VERSION ""

NS_ :

BS_:

BU_: FSClient FSBrowser FileServer
VAL_TABLE_ TIM_AuthErrorCode 39 "LwAPossibleBitMismatch" 38 "AuthenticationAbortedDueToGeneralPeerError" 37 "AuthenticationAbortedByPeerDueToError" 36 "ChallengeDataCorrupt" 35 "InvalidChallengeLength" 34 "FunctionFacilityNotCertified" 33 "RequestNotAllowed" 32 "Reserved_0x20" 31 "AuthenticationTimeout" 30 "CertificateTypeInvalid" 29 "DeviceCertificateRevoked" 28 "ManufacturerSeriesCertificateRevoked" 27 "ManufacturerCertificateRevoked" 26 "LabCertificateRevoked" 25 "RootCertificateRevoked" 24 "CertificateTypeMismatch" 23 "CertificateChainInvalid" 22 "ECU_CCID_Mismatch" 21 "NAME_Mismatch" 20 "ECC_PublicKeyValidationFailed" 19 "UnexpectedRestartAuthenticationBitSet" 18 "AuthenticationStatusInvalid" 17 "AuthenticationTypeNotSupported" 16 "AuthenticationStatusLost" 15 "DeviceCertificateDataCorrupt" 14 "ManufacturerSeriesCertificateDataCorrupt" 13 "ManufacturerCertificateDataCorrupt" 12 "TestLabCertificateDataCorrupt" 11 "RootCertificateDataCorrupt" 10 "InternalError" 9 "ChallengesDontMatch" 8 "DeviceCertificateSignatureInvalid" 7 "ManufacturerSeriesCertificateSignatureInvalid" 6 "ManufacturerCertificateSignatureInvalid" 5 "LabCertificateSignatureInvalid" 4 "RootCertificateSignatureInvalid" 3 "NotAuthenticationServerOrClient" 2 "CertificateFormatNotSupported" 1 "ParticipantBusy" 0 "NoError" ;
VAL_TABLE_ TIM_CertificateType 255 "NotAvailable" 6 "CRLCertificate" 5 "CRLSigningCertificate" 4 "DeviceCertificate" 3 "ManufacturereSeriesCertificate" 2 "ManufacturerCertificate" 1 "TestlabCertificate" 0 "AEFRootCertificate" ;
VAL_TABLE_ NetworkInterconnUnitParametrics 16 "NetworkInterconnectionUnitType" 15 "NumberOfPorts" 14 "UptimeSinceLastPowerOnReset " 13 "AverageNumOfMsgsFilteredPerSec" 12 "AverageNumOfMsgsForwardedPerSec" 11 "AverageNumOfMsgsReceivedPerSec" 10 "NumOfMsgsWithExcessTransitDelayTime " 9 "NumOfMsgsLostDueToBufferOverflow " 8 "AverageTransitDelayTime" 7 "MaxTransitDelayTime" 6 "MaxNumOfMsgsFilteredPerSec" 5 "MaxNumOfMsgsForwardedPerSec" 4 "MaxNumOfMsgsReceivedPerSec" 3 "NumberOfFilterDatabaseEntries" 2 "MaxFilterDatabaseSize" 1 "BufferSize" 0 "RequestAllParameters" ;
VAL_TABLE_ FMI 0 "Above normal (most severe)" 1 "Below normal (most severe)" 2 "Data erratic" 3 "Voltage above normal" 4 "Voltage below normal" 5 "Current below normal" 6 "Current above normal" 7 "Mechanical system not responding" 8 "Abnormal frequency" 9 "Abnormal update rate" 10 "Abnormal rate of change" 11 "Root cause not known" 12 "Bad intelligent device" 13 "Out of calibration" 14 "Special intstructions" 15 "Above normal (least severe)" 16 "Above normal (moderately severe)" 17 "Below normal (least severe)" 18 "Below normal (moderately severe)" 19 "Received network data in error" 31 "Not available" 20 "Data Drifted High" 21 "Data Drifted Low" ;

BO_ 2628517377 FSC_FileServer: 35 FileServer
 SG_ OF_ATTR_VolumeSupportsHidden m32 : 34|1@1+ (1,0) [0|1] "" Vector__XXX
 SG_ GCD_PathName m16 : 88|16@1+ (1,0) [0|65535] "" Vector__XXX
 SG_ GCD_FreeSpace m16 : 56|32@1+ (512,0) [0|4294966744] "Bytes" Vector__XXX
 SG_ FDT_TimeHour m52 : 51|5@1+ (1,0) [0|23] "Hour" Vector__XXX
 SG_ FDT_TimeMinutes m52 : 45|6@1+ (1,0) [0|59] "Minutes" Vector__XXX
 SG_ FDT_TimeSeconds m52 : 40|5@1+ (2,0) [0|58] "Seconds" Vector__XXX
 SG_ OF_ATTR_VolumeIsCaseSensitive m32 : 39|1@1+ (1,0) [0|1] "" Vector__XXX
 SG_ OF_ATTR_VolumeIsRemovable m32 : 38|1@1+ (1,0) [0|1] "" Vector__XXX
 SG_ OF_ATTR_SupportsLongFilenames m32 : 37|1@1+ (1,0) [0|1] "" Vector__XXX
 SG_ OF_ATTR_IsDirectory m32 : 36|1@1+ (1,0) [0|1] "" Vector__XXX
 SG_ OF_ATTR_IsVolume m32 : 35|1@1+ (1,0) [0|1] "" Vector__XXX
 SG_ FDT_DateYear m52 : 33|7@1+ (1,1980) [1980|2107] "Year" Vector__XXX
 SG_ OF_ATTR_Hidden m32 : 33|1@1+ (1,0) [0|1] "" Vector__XXX
 SG_ SF_Position m33 : 32|32@1+ (1,0) [0|4294967295] "" Vector__XXX
 SG_ OF_ATTR_ReadOnly m32 : 32|1@1+ (1,0) [0|1] "" Vector__XXX
 SG_ GA_Size m50 : 32|32@1+ (1,0) [0|4294967295] "" Vector__XXX
 SG_ VS_VolumeName m2 : 32|16@1+ (1,0) [0|65535] "" Vector__XXX
 SG_ VI_VolumeIsCaseSensitive m64 : 31|1@1+ (1,0) [0|1] "" Vector__XXX
 SG_ GA_ATTR_VolumeIsCaseSensitive m50 : 31|1@1+ (1,0) [0|1] "" Vector__XXX
 SG_ VI_ATTR_VolumeRemovable m64 : 30|1@1+ (1,0) [0|1] "" Vector__XXX
 SG_ GA_ATTR_VolumeIsRemovable m50 : 30|1@1+ (1,0) [0|1] "" Vector__XXX
 SG_ VI_ATTR_SupportsLongFilenames m64 : 29|1@1+ (1,0) [0|1] "" Vector__XXX
 SG_ FDT_DateMonth m52 : 29|4@1+ (1,0) [0|12] "Month" Vector__XXX
 SG_ GA_ATTR_SupportsLongFilenames m50 : 29|1@1+ (1,0) [0|1] "" Vector__XXX
 SG_ GA_ATTR_IsDirectory m50 : 28|1@1+ (1,0) [0|1] "" Vector__XXX
 SG_ VI_ATTR_IsDirectory m64 : 28|1@1+ (1,0) [0|1] "" Vector__XXX
 SG_ VI_ATTR_IsVolume m64 : 27|1@1+ (1,0) [0|1] "" Vector__XXX
 SG_ GA_ATTR_IsVolume m50 : 27|1@1+ (1,0) [0|1] "" Vector__XXX
 SG_ VI_ATTR_VolumeSupportsHidden m64 : 26|1@1+ (1,0) [0|1] "" Vector__XXX
 SG_ GA_ATTR_VolumeSupportsHidden m50 : 26|1@1+ (1,0) [0|1] "" Vector__XXX
 SG_ VI_ATTR_Hidden m64 : 25|1@1+ (1,0) [0|1] "" Vector__XXX
 SG_ GA_ATTR_Hidden m50 : 25|1@1+ (1,0) [0|1] "" Vector__XXX
 SG_ VI_ATTR_ReadOnly m64 : 24|1@1+ (1,0) [0|1] "" Vector__XXX
 SG_ FDT_DateDay m52 : 24|5@1+ (1,0) [0|31] "Day" Vector__XXX
 SG_ GA_ATTR_ReadOnly m50 : 24|1@1+ (1,0) [0|1] "" Vector__XXX
 SG_ OF_Handle m32 : 24|8@1+ (1,0) [0|255] "" Vector__XXX
 SG_ GCD_TotalSpace m16 : 24|32@1+ (512,0) [0|4294966744] "Bytes" Vector__XXX
 SG_ RF_Count m34 : 24|16@1+ (1,0) [0|65535] "Bytes" Vector__XXX
 SG_ GSP_SupportMultipleVolumes m1 : 24|1@1+ (1,0) [0|255] "" Vector__XXX
 SG_ WF_Count m35 : 24|16@1+ (1,0) [0|65535] "" Vector__XXX
 SG_ VS_ErrorCode m2 : 24|8@1+ (1,0) [0|255] "" Vector__XXX
 SG_ FDT_ErrorCode m52 : 16|8@1+ (1,0) [0|255] "" Vector__XXX
 SG_ RF_ErrorCode m34 : 16|8@1+ (1,0) [0|255] "" Vector__XXX
 SG_ SF_ErrorCode m33 : 16|8@1+ (1,0) [0|255] "" Vector__XXX
 SG_ FSNumberOfOpenFiles m0 : 16|8@1- (1,0) [0|255] "" Vector__XXX
 SG_ OF_ErrorCode m32 : 16|8@1+ (1,0) [0|255] "" Vector__XXX
 SG_ WF_ErrorCode m35 : 16|8@1+ (1,0) [0|255] "" Vector__XXX
 SG_ CF_ErrorCode m36 : 16|8@1+ (1,0) [0|255] "" Vector__XXX
 SG_ MF_ErrorCode m48 : 16|8@1+ (1,0) [0|255] "" Vector__XXX
 SG_ GA_ErrorCode m50 : 16|8@1+ (1,0) [0|255] "" Vector__XXX
 SG_ SA_ErrorCode m51 : 16|8@1+ (1,0) [0|255] "" Vector__XXX
 SG_ GCD_ErrorCode m16 : 16|8@1+ (1,0) [0|255] "" Vector__XXX
 SG_ CCD_ErrorCode m17 : 16|8@1+ (1,0) [0|255] "" Vector__XXX
 SG_ GSP_MaxNrSimultaneousFilesOpen m1 : 16|8@1+ (1,0) [0|255] "" Vector__XXX
 SG_ DF_ErrorCode m49 : 16|8@1+ (1,0) [0|255] "" Vector__XXX
 SG_ VI_ErrorCode m64 : 16|8@1+ (1,0) [0|255] "" Vector__XXX
 SG_ VS_MaxTimeBeforeVolRemoval m2 : 16|8@1+ (1,0) [0|250] "min/bit" Vector__XXX
 SG_ FSBusyWriting m0 : 9|1@1+ (1,0) [0|1] "" Vector__XXX
 SG_ FSBusyReading m0 : 8|1@1+ (1,0) [0|1] "" Vector__XXX
 SG_ OF_TAN m32 : 8|8@1+ (1,0) [0|255] "" Vector__XXX
 SG_ SF_TAN m33 : 8|8@1+ (1,0) [0|255] "" Vector__XXX
 SG_ RF_TAN m34 : 8|8@1+ (1,0) [0|255] "" Vector__XXX
 SG_ WF_TAN m35 : 8|8@1+ (1,0) [0|255] "" Vector__XXX
 SG_ CF_TAN m36 : 8|8@1+ (1,0) [0|255] "" Vector__XXX
 SG_ MF_TAN m48 : 8|8@1+ (1,0) [0|255] "" Vector__XXX
 SG_ GA_TAN m50 : 8|8@1+ (1,0) [0|255] "" Vector__XXX
 SG_ SA_TAN m51 : 8|8@1+ (1,0) [0|255] "" Vector__XXX
 SG_ FDT_TAN m52 : 8|8@1+ (1,0) [0|255] "" Vector__XXX
 SG_ GCD_TAN m16 : 8|8@1+ (1,0) [0|255] "" Vector__XXX
 SG_ CCD_TAN m17 : 8|8@1+ (1,0) [0|255] "" Vector__XXX
 SG_ GSP_VersionNumber m1 : 8|8@1+ (1,0) [0|255] "" Vector__XXX
 SG_ DF_TAN m49 : 8|8@1+ (1,0) [0|255] "" Vector__XXX
 SG_ VI_TAN m64 : 8|8@1+ (1,0) [0|255] "" Vector__XXX
 SG_ VS_VolumeStatus m2 : 8|8@1+ (1,0) [0|3] "" Vector__XXX
 SG_ FSServerCommand M : 0|8@1+ (1,0) [0|255] "" Vector__XXX

BO_ 2628451851 CFS_FSBrowser: 9 FSBrowser
 SG_ SA_ATTR_SupportsLongFilenames m51 : 21|1@1+ (1,0) [0|1] "" Vector__XXX
 SG_ SA_ATTR_VolumeSupportsHidden m51 : 18|1@1+ (1,0) [0|1] "" Vector__XXX
 SG_ SA_ATTR_VolumeIsRemovable m51 : 22|1@1+ (1,0) [0|1] "" Vector__XXX
 SG_ SA_ATTR_VolumeIsCaseSensitive m51 : 23|1@1+ (1,0) [0|1] "" Vector__XXX
 SG_ SA_ATTR_IsVolume m51 : 19|1@1+ (1,0) [0|1] "" Vector__XXX
 SG_ SA_ATTR_IsDirectory m51 : 20|1@1+ (1,0) [0|1] "" Vector__XXX
 SG_ VI_VolumeName m64 : 56|16@1+ (1,0) [0|65535] "" Vector__XXX
 SG_ VI_Flag_OverwriteExisting m64 : 48|1@1+ (1,0) [0|1] "" Vector__XXX
 SG_ MF_DestinationPathNameLength m48 : 40|16@1+ (1,0) [0|65535] "" Vector__XXX
 SG_ RF_ReportHiddenFiles m34 : 40|8@1+ (1,0) [0|255] "" Vector__XXX
 SG_ SF_Offset m33 : 32|32@1- (1,0) [-2147483648|2147483647] "" Vector__XXX
 SG_ RF_Count m34 : 24|16@1+ (1,0) [0|65535] "" Vector__XXX
 SG_ SF_PositionMode m33 : 24|8@1+ (1,0) [0|255] "" Vector__XXX
 SG_ OF_PathName m32 : 24|16@1+ (1,0) [0|65535] "" Vector__XXX
 SG_ MF_SourcePathNameLength m48 : 24|16@1+ (1,0) [0|65535] "" Vector__XXX
 SG_ WF_Count m35 : 24|16@1+ (1,0) [0|65535] "" Vector__XXX
 SG_ DF_PathName m49 : 24|16@1+ (1,0) [0|65535] "" Vector__XXX
 SG_ SA_PathName m51 : 24|16@1+ (1,0) [0|65535] "" Vector__XXX
 SG_ VI_Space m64 : 16|32@1+ (1,0) [0|4294967295] "" Vector__XXX
 SG_ OF_FlagExclusiveAccess m32 : 20|1@1+ (1,0) [0|1] "" Vector__XXX
 SG_ OF_FlagAppend m32 : 19|1@1+ (1,0) [0|1] "" Vector__XXX
 SG_ SA_ATTR_Hidden m51 : 17|1@1+ (1,0) [0|1] "" Vector__XXX
 SG_ OF_FlagCreateNew m32 : 18|1@1+ (1,0) [0|1] "" Vector__XXX
 SG_ MF_MoveModeRecursive m48 : 18|1@1+ (1,0) [0|1] "" Vector__XXX
 SG_ DF_DeleteModeRecursive m49 : 18|1@1+ (1,0) [0|1] "" Vector__XXX
 SG_ MF_MoveModeForce m48 : 17|1@1+ (1,0) [0|1] "" Vector__XXX
 SG_ DF_DeleteModeForce m49 : 17|1@1+ (1,0) [0|1] "" Vector__XXX
 SG_ VI_Flag_UsingSpaceSpecified m64 : 49|1@1+ (1,0) [0|1] "" Vector__XXX
 SG_ SA_ATTR_ReadOnly m51 : 16|1@1+ (1,0) [0|1] "" Vector__XXX
 SG_ CF_Handle m36 : 16|8@1+ (1,0) [0|255] "" Vector__XXX
 SG_ WF_Handle m35 : 16|8@1+ (1,0) [0|255] "" Vector__XXX
 SG_ RF_Handle m34 : 16|8@1+ (1,0) [0|255] "" Vector__XXX
 SG_ SF_Handle m33 : 16|8@1+ (1,0) [0|255] "" Vector__XXX
 SG_ OF_FlagReadWrite m32 : 16|2@1+ (1,0) [0|3] "" Vector__XXX
 SG_ CCD_PathName m17 : 16|16@1+ (1,0) [0|65535] "" Vector__XXX
 SG_ MF_MoveModeCopy m48 : 16|1@1+ (1,0) [0|1] "" Vector__XXX
 SG_ DF_DeleteMode m49 : 16|1@1+ (1,0) [0|1] "" Vector__XXX
 SG_ GA_PathName m50 : 16|16@1+ (1,0) [0|65535] "" Vector__XXX
 SG_ FDT_PathName m52 : 16|16@1+ (1,0) [0|65535] "" Vector__XXX
 SG_ VS_VolumeName m2 : 16|16@1+ (1,0) [0|0] "" Vector__XXX
 SG_ VS_RequestVolumeToPrepareForRemo m2 : 9|1@1- (1,0) [0|1] "" Vector__XXX
 SG_ CCD_TAN m17 : 8|8@1+ (1,0) [0|255] "" Vector__XXX
 SG_ GCD_TAN m16 : 8|8@1+ (1,0) [0|255] "" Vector__XXX
 SG_ FDT_TAN m52 : 8|8@1+ (1,0) [0|255] "" Vector__XXX
 SG_ SA_TAN m51 : 8|8@1+ (1,0) [0|255] "" Vector__XXX
 SG_ GA_TAN m50 : 8|8@1+ (1,0) [0|255] "" Vector__XXX
 SG_ RF_TAN m34 : 8|8@1+ (1,0) [0|255] "" Vector__XXX
 SG_ CF_TAN m36 : 8|8@1+ (1,0) [0|255] "" Vector__XXX
 SG_ WF_TAN m35 : 8|8@1+ (1,0) [0|255] "" Vector__XXX
 SG_ SF_TAN m33 : 8|8@1+ (1,0) [0|255] "" Vector__XXX
 SG_ OF_TAN m32 : 8|8@1+ (1,0) [0|255] "" Vector__XXX
 SG_ MF_TAN m48 : 8|8@1+ (1,0) [0|255] "" Vector__XXX
 SG_ DF_TAN m49 : 8|8@1+ (1,0) [0|255] "" Vector__XXX
 SG_ VI_TAN m64 : 8|8@1+ (1,0) [0|255] "" Vector__XXX
 SG_ VS_ReportVolumeUsedByClient m2 : 8|1@1+ (1,0) [0|1] "" Vector__XXX
 SG_ CM_VersionNumber m0 : 8|8@1+ (1,0) [0|255] "" Vector__XXX
 SG_ FSClientCommand M : 0|8@1+ (1,0) [0|255] "" Vector__XXX

BO_ 2628451850 CFS_FSClient: 9 FSClient
 SG_ SA_ATTR_SupportsLongFilenames m51 : 21|1@1+ (1,0) [0|1] "" Vector__XXX
 SG_ SA_ATTR_VolumeSupportsHidden m51 : 18|1@1+ (1,0) [0|1] "" Vector__XXX
 SG_ SA_ATTR_VolumeIsRemovable m51 : 22|1@1+ (1,0) [0|1] "" Vector__XXX
 SG_ SA_ATTR_VolumeIsCaseSensitive m51 : 23|1@1+ (1,0) [0|1] "" Vector__XXX
 SG_ SA_ATTR_IsVolume m51 : 19|1@1+ (1,0) [0|1] "" Vector__XXX
 SG_ SA_ATTR_IsDirectory m51 : 20|1@1+ (1,0) [0|1] "" Vector__XXX
 SG_ VI_VolumeName m64 : 56|16@1+ (1,0) [0|65535] "" Vector__XXX
 SG_ VI_Flag_OverwriteExisting m64 : 48|1@1+ (1,0) [0|1] "" Vector__XXX
 SG_ MF_DestinationPathNameLength m48 : 40|16@1+ (1,0) [0|65535] "" Vector__XXX
 SG_ RF_ReportHiddenFiles m34 : 40|8@1+ (1,0) [0|255] "" Vector__XXX
 SG_ SF_Offset m33 : 32|32@1- (1,0) [-2147483648|2147483647] "" Vector__XXX
 SG_ RF_Count m34 : 24|16@1+ (1,0) [0|65535] "" Vector__XXX
 SG_ SF_PositionMode m33 : 24|8@1+ (1,0) [0|255] "" Vector__XXX
 SG_ OF_PathName m32 : 24|16@1+ (1,0) [0|65535] "" Vector__XXX
 SG_ MF_SourcePathNameLength m48 : 24|16@1+ (1,0) [0|65535] "" Vector__XXX
 SG_ WF_Count m35 : 24|16@1+ (1,0) [0|65535] "" Vector__XXX
 SG_ DF_PathName m49 : 24|16@1+ (1,0) [0|65535] "" Vector__XXX
 SG_ SA_PathName m51 : 24|16@1+ (1,0) [0|65535] "" Vector__XXX
 SG_ VI_Space m64 : 16|32@1+ (1,0) [0|4294967295] "" Vector__XXX
 SG_ OF_FlagExclusiveAccess m32 : 20|1@1+ (1,0) [0|1] "" Vector__XXX
 SG_ OF_FlagAppend m32 : 19|1@1+ (1,0) [0|1] "" Vector__XXX
 SG_ SA_ATTR_Hidden m51 : 17|1@1+ (1,0) [0|1] "" Vector__XXX
 SG_ OF_FlagCreateNew m32 : 18|1@1+ (1,0) [0|1] "" Vector__XXX
 SG_ MF_MoveModeRecursive m48 : 18|1@1+ (1,0) [0|1] "" Vector__XXX
 SG_ DF_DeleteModeRecursive m49 : 18|1@1+ (1,0) [0|1] "" Vector__XXX
 SG_ MF_MoveModeForce m48 : 17|1@1+ (1,0) [0|1] "" Vector__XXX
 SG_ DF_DeleteModeForce m49 : 17|1@1+ (1,0) [0|1] "" Vector__XXX
 SG_ VI_Flag_UsingSpaceSpecified m64 : 49|1@1+ (1,0) [0|1] "" Vector__XXX
 SG_ SA_ATTR_ReadOnly m51 : 16|1@1+ (1,0) [0|1] "" Vector__XXX
 SG_ CF_Handle m36 : 16|8@1+ (1,0) [0|255] "" Vector__XXX
 SG_ WF_Handle m35 : 16|8@1+ (1,0) [0|255] "" Vector__XXX
 SG_ RF_Handle m34 : 16|8@1+ (1,0) [0|255] "" Vector__XXX
 SG_ SF_Handle m33 : 16|8@1+ (1,0) [0|255] "" Vector__XXX
 SG_ OF_FlagReadWrite m32 : 16|2@1+ (1,0) [0|3] "" Vector__XXX
 SG_ CCD_PathName m17 : 16|16@1+ (1,0) [0|65535] "" Vector__XXX
 SG_ MF_MoveModeCopy m48 : 16|1@1+ (1,0) [0|1] "" Vector__XXX
 SG_ DF_DeleteMode m49 : 16|1@1+ (1,0) [0|1] "" Vector__XXX
 SG_ GA_PathName m50 : 16|16@1+ (1,0) [0|65535] "" Vector__XXX
 SG_ FDT_PathName m52 : 16|16@1+ (1,0) [0|65535] "" Vector__XXX
 SG_ VS_VolumeName m2 : 16|16@1+ (1,0) [0|0] "" Vector__XXX
 SG_ VS_RequestVolumeToPrepareFo_0000 m2 : 9|1@1- (1,0) [0|1] "" Vector__XXX
 SG_ CCD_TAN m17 : 8|8@1+ (1,0) [0|255] "" Vector__XXX
 SG_ GCD_TAN m16 : 8|8@1+ (1,0) [0|255] "" Vector__XXX
 SG_ FDT_TAN m52 : 8|8@1+ (1,0) [0|255] "" Vector__XXX
 SG_ SA_TAN m51 : 8|8@1+ (1,0) [0|255] "" Vector__XXX
 SG_ GA_TAN m50 : 8|8@1+ (1,0) [0|255] "" Vector__XXX
 SG_ RF_TAN m34 : 8|8@1+ (1,0) [0|255] "" Vector__XXX
 SG_ CF_TAN m36 : 8|8@1+ (1,0) [0|255] "" Vector__XXX
 SG_ WF_TAN m35 : 8|8@1+ (1,0) [0|255] "" Vector__XXX
 SG_ SF_TAN m33 : 8|8@1+ (1,0) [0|255] "" Vector__XXX
 SG_ OF_TAN m32 : 8|8@1+ (1,0) [0|255] "" Vector__XXX
 SG_ MF_TAN m48 : 8|8@1+ (1,0) [0|255] "" Vector__XXX
 SG_ DF_TAN m49 : 8|8@1+ (1,0) [0|255] "" Vector__XXX
 SG_ VI_TAN m64 : 8|8@1+ (1,0) [0|255] "" Vector__XXX
 SG_ VS_ReportVolumeUsedByClient m2 : 8|1@1+ (1,0) [0|1] "" Vector__XXX
 SG_ CM_VersionNumber m0 : 8|8@1+ (1,0) [0|255] "" Vector__XXX
 SG_ FSClientCommand M : 0|8@1+ (1,0) [0|255] "" Vector__XXX

BO_ 2565799425 ACL_FileServer: 8 FileServer
 SG_ ReservedBit : 48|1@1+ (1,0) [0|0] "" Vector__XXX
 SG_ ArbitraryAddressCapable : 63|1@1+ (1,0) [0|1] "" Vector__XXX
 SG_ IndustryGroup M : 60|3@1+ (1,0) [0|7] "" Vector__XXX
 SG_ VehicleSystemInstance : 56|4@1+ (1,0) [0|15] "" Vector__XXX
 SG_ VehicleSystem m0 : 49|7@1+ (1,0) [0|127] "" Vector__XXX
 SG_ VehicleSystem5 m5 : 49|7@1+ (1,0) [0|127] "" Vector__XXX
 SG_ VehicleSystem4 m4 : 49|7@1+ (1,0) [0|127] "" Vector__XXX
 SG_ VehicleSystem3 m3 : 49|7@1+ (1,0) [0|127] "" Vector__XXX
 SG_ VehicleSystem2 m2 : 49|7@1+ (1,0) [0|127] "" Vector__XXX
 SG_ VehicleSystem1 m1 : 49|7@1+ (1,0) [0|127] "" Vector__XXX
 SG_ Function : 40|8@1+ (1,0) [0|255] "" Vector__XXX
 SG_ FunctionInstance : 35|5@1+ (1,0) [0|31] "" Vector__XXX
 SG_ ECUInstance : 32|3@1+ (1,0) [0|7] "" Vector__XXX
 SG_ ManufacturerCode : 21|11@1+ (1,0) [0|2047] "" Vector__XXX
 SG_ IdentityNumber : 0|21@1+ (1,0) [0|2097152] "" Vector__XXX

BO_ 2565799435 ACL_FSBrowser: 8 FSBrowser
 SG_ ReservedBit : 48|1@1+ (1,0) [0|0] "" Vector__XXX
 SG_ ArbitraryAddressCapable : 63|1@1+ (1,0) [0|1] "" Vector__XXX
 SG_ IndustryGroup M : 60|3@1+ (1,0) [0|7] "" Vector__XXX
 SG_ VehicleSystemInstance : 56|4@1+ (1,0) [0|15] "" Vector__XXX
 SG_ VehicleSystem m0 : 49|7@1+ (1,0) [0|127] "" Vector__XXX
 SG_ VehicleSystem5 m5 : 49|7@1+ (1,0) [0|127] "" Vector__XXX
 SG_ VehicleSystem4 m4 : 49|7@1+ (1,0) [0|127] "" Vector__XXX
 SG_ VehicleSystem3 m3 : 49|7@1+ (1,0) [0|127] "" Vector__XXX
 SG_ VehicleSystem2 m2 : 49|7@1+ (1,0) [0|127] "" Vector__XXX
 SG_ VehicleSystem1 m1 : 49|7@1+ (1,0) [0|127] "" Vector__XXX
 SG_ Function : 40|8@1+ (1,0) [0|255] "" Vector__XXX
 SG_ FunctionInstance : 35|5@1+ (1,0) [0|31] "" Vector__XXX
 SG_ ECUInstance : 32|3@1+ (1,0) [0|7] "" Vector__XXX
 SG_ ManufacturerCode : 21|11@1+ (1,0) [0|2047] "" Vector__XXX
 SG_ IdentityNumber : 0|21@1+ (1,0) [0|2097152] "" Vector__XXX

BO_ 2565799434 ACL_FSClient: 8 FSClient
 SG_ ReservedBit : 48|1@1+ (1,0) [0|0] "" Vector__XXX
 SG_ ArbitraryAddressCapable : 63|1@1+ (1,0) [0|1] "" Vector__XXX
 SG_ IndustryGroup M : 60|3@1+ (1,0) [0|7] "" Vector__XXX
 SG_ VehicleSystemInstance : 56|4@1+ (1,0) [0|15] "" Vector__XXX
 SG_ VehicleSystem m0 : 49|7@1+ (1,0) [0|127] "" Vector__XXX
 SG_ VehicleSystem5 m5 : 49|7@1+ (1,0) [0|127] "" Vector__XXX
 SG_ VehicleSystem4 m4 : 49|7@1+ (1,0) [0|127] "" Vector__XXX
 SG_ VehicleSystem3 m3 : 49|7@1+ (1,0) [0|127] "" Vector__XXX
 SG_ VehicleSystem2 m2 : 49|7@1+ (1,0) [0|127] "" Vector__XXX
 SG_ VehicleSystem1 m1 : 49|7@1+ (1,0) [0|127] "" Vector__XXX
 SG_ Function : 40|8@1+ (1,0) [0|255] "" Vector__XXX
 SG_ FunctionInstance : 35|5@1+ (1,0) [0|31] "" Vector__XXX
 SG_ ECUInstance : 32|3@1+ (1,0) [0|7] "" Vector__XXX
 SG_ ManufacturerCode : 21|11@1+ (1,0) [0|2047] "" Vector__XXX
 SG_ IdentityNumber : 0|21@1+ (1,0) [0|2097152] "" Vector__XXX

BO_ 2628452094 CFS: 9 Vector__XXX
 SG_ SA_ATTR_SupportsLongFilenames m51 : 21|1@1+ (1,0) [0|1] "" Vector__XXX
 SG_ SA_ATTR_VolumeSupportsHidden m51 : 18|1@1+ (1,0) [0|1] "" Vector__XXX
 SG_ SA_ATTR_VolumeIsRemovable m51 : 22|1@1+ (1,0) [0|1] "" Vector__XXX
 SG_ SA_ATTR_VolumeIsCaseSensitive m51 : 23|1@1+ (1,0) [0|1] "" Vector__XXX
 SG_ SA_ATTR_IsVolume m51 : 19|1@1+ (1,0) [0|1] "" Vector__XXX
 SG_ SA_ATTR_IsDirectory m51 : 20|1@1+ (1,0) [0|1] "" Vector__XXX
 SG_ VI_VolumeName m64 : 56|16@1+ (1,0) [0|65535] "" Vector__XXX
 SG_ VI_Flag_OverwriteExisting m64 : 48|1@1+ (1,0) [0|1] "" Vector__XXX
 SG_ MF_DestinationPathNameLength m48 : 40|16@1+ (1,0) [0|65535] "" Vector__XXX
 SG_ RF_ReportHiddenFiles m34 : 40|8@1+ (1,0) [0|255] "" Vector__XXX
 SG_ SF_Offset m33 : 32|32@1- (1,0) [-2147483648|2147483647] "" Vector__XXX
 SG_ RF_Count m34 : 24|16@1+ (1,0) [0|65535] "" Vector__XXX
 SG_ SF_PositionMode m33 : 24|8@1+ (1,0) [0|255] "" Vector__XXX
 SG_ OF_PathName m32 : 24|16@1+ (1,0) [0|65535] "" Vector__XXX
 SG_ MF_SourcePathNameLength m48 : 24|16@1+ (1,0) [0|65535] "" Vector__XXX
 SG_ WF_Count m35 : 24|16@1+ (1,0) [0|65535] "" Vector__XXX
 SG_ DF_PathName m49 : 24|16@1+ (1,0) [0|65535] "" Vector__XXX
 SG_ SA_PathName m51 : 24|16@1+ (1,0) [0|65535] "" Vector__XXX
 SG_ VI_Space m64 : 16|32@1+ (1,0) [0|4294967295] "" Vector__XXX
 SG_ OF_FlagExclusiveAccess m32 : 20|1@1+ (1,0) [0|1] "" Vector__XXX
 SG_ OF_FlagAppend m32 : 19|1@1+ (1,0) [0|1] "" Vector__XXX
 SG_ SA_ATTR_Hidden m51 : 17|1@1+ (1,0) [0|1] "" Vector__XXX
 SG_ OF_FlagCreateNew m32 : 18|1@1+ (1,0) [0|1] "" Vector__XXX
 SG_ MF_MoveModeRecursive m48 : 18|1@1+ (1,0) [0|1] "" Vector__XXX
 SG_ DF_DeleteModeRecursive m49 : 18|1@1+ (1,0) [0|1] "" Vector__XXX
 SG_ MF_MoveModeForce m48 : 17|1@1+ (1,0) [0|1] "" Vector__XXX
 SG_ DF_DeleteModeForce m49 : 17|1@1+ (1,0) [0|1] "" Vector__XXX
 SG_ VI_Flag_UsingSpaceSpecified m64 : 49|1@1+ (1,0) [0|1] "" Vector__XXX
 SG_ SA_ATTR_ReadOnly m51 : 16|1@1+ (1,0) [0|1] "" Vector__XXX
 SG_ CF_Handle m36 : 16|8@1+ (1,0) [0|255] "" Vector__XXX
 SG_ WF_Handle m35 : 16|8@1+ (1,0) [0|255] "" Vector__XXX
 SG_ RF_Handle m34 : 16|8@1+ (1,0) [0|255] "" Vector__XXX
 SG_ SF_Handle m33 : 16|8@1+ (1,0) [0|255] "" Vector__XXX
 SG_ OF_FlagReadWrite m32 : 16|2@1+ (1,0) [0|3] "" Vector__XXX
 SG_ CCD_PathName m17 : 16|16@1+ (1,0) [0|65535] "" Vector__XXX
 SG_ MF_MoveModeCopy m48 : 16|1@1+ (1,0) [0|1] "" Vector__XXX
 SG_ DF_DeleteMode m49 : 16|1@1+ (1,0) [0|1] "" Vector__XXX
 SG_ GA_PathName m50 : 16|16@1+ (1,0) [0|65535] "" Vector__XXX
 SG_ FDT_PathName m52 : 16|16@1+ (1,0) [0|65535] "" Vector__XXX
 SG_ VS_VolumeName m2 : 16|16@1+ (1,0) [0|0] "" Vector__XXX
 SG_ VS_RequestVolumeToPrepareFo_0001 m2 : 9|1@1- (1,0) [0|1] "" Vector__XXX
 SG_ CCD_TAN m17 : 8|8@1+ (1,0) [0|255] "" Vector__XXX
 SG_ GCD_TAN m16 : 8|8@1+ (1,0) [0|255] "" Vector__XXX
 SG_ FDT_TAN m52 : 8|8@1+ (1,0) [0|255] "" Vector__XXX
 SG_ SA_TAN m51 : 8|8@1+ (1,0) [0|255] "" Vector__XXX
 SG_ GA_TAN m50 : 8|8@1+ (1,0) [0|255] "" Vector__XXX
 SG_ RF_TAN m34 : 8|8@1+ (1,0) [0|255] "" Vector__XXX
 SG_ CF_TAN m36 : 8|8@1+ (1,0) [0|255] "" Vector__XXX
 SG_ WF_TAN m35 : 8|8@1+ (1,0) [0|255] "" Vector__XXX
 SG_ SF_TAN m33 : 8|8@1+ (1,0) [0|255] "" Vector__XXX
 SG_ OF_TAN m32 : 8|8@1+ (1,0) [0|255] "" Vector__XXX
 SG_ MF_TAN m48 : 8|8@1+ (1,0) [0|255] "" Vector__XXX
 SG_ DF_TAN m49 : 8|8@1+ (1,0) [0|255] "" Vector__XXX
 SG_ VI_TAN m64 : 8|8@1+ (1,0) [0|255] "" Vector__XXX
 SG_ VS_ReportVolumeUsedByClient m2 : 8|1@1+ (1,0) [0|1] "" Vector__XXX
 SG_ CM_VersionNumber m0 : 8|8@1+ (1,0) [0|255] "" Vector__XXX
 SG_ FSClientCommand M : 0|8@1+ (1,0) [0|255] "" Vector__XXX

BO_ 2628517630 FSC: 35 Vector__XXX
 SG_ OF_ATTR_VolumeSupportsHidden m32 : 34|1@1+ (1,0) [0|1] "" Vector__XXX
 SG_ GCD_PathName m16 : 88|16@1+ (1,0) [0|65535] "" Vector__XXX
 SG_ GCD_FreeSpace m16 : 56|32@1+ (512,0) [0|4294966744] "Bytes" Vector__XXX
 SG_ FDT_TimeHour m52 : 51|5@1+ (1,0) [0|23] "Hour" Vector__XXX
 SG_ FDT_TimeMinutes m52 : 45|6@1+ (1,0) [0|59] "Minutes" Vector__XXX
 SG_ FDT_TimeSeconds m52 : 40|5@1+ (2,0) [0|58] "Seconds" Vector__XXX
 SG_ OF_ATTR_VolumeIsCaseSensitive m32 : 39|1@1+ (1,0) [0|1] "" Vector__XXX
 SG_ OF_ATTR_VolumeIsRemovable m32 : 38|1@1+ (1,0) [0|1] "" Vector__XXX
 SG_ OF_ATTR_SupportsLongFilenames m32 : 37|1@1+ (1,0) [0|1] "" Vector__XXX
 SG_ OF_ATTR_IsDirectory m32 : 36|1@1+ (1,0) [0|1] "" Vector__XXX
 SG_ OF_ATTR_IsVolume m32 : 35|1@1+ (1,0) [0|1] "" Vector__XXX
 SG_ FDT_DateYear m52 : 33|7@1+ (1,1980) [1980|2107] "Year" Vector__XXX
 SG_ OF_ATTR_Hidden m32 : 33|1@1+ (1,0) [0|1] "" Vector__XXX
 SG_ SF_Position m33 : 32|32@1+ (1,0) [0|4294967295] "" Vector__XXX
 SG_ OF_ATTR_ReadOnly m32 : 32|1@1+ (1,0) [0|1] "" Vector__XXX
 SG_ GA_Size m50 : 32|32@1+ (1,0) [0|4294967295] "" Vector__XXX
 SG_ VS_VolumeName m2 : 32|16@1+ (1,0) [0|65535] "" Vector__XXX
 SG_ VI_VolumeIsCaseSensitive m64 : 31|1@1+ (1,0) [0|1] "" Vector__XXX
 SG_ GA_ATTR_VolumeIsCaseSensitive m50 : 31|1@1+ (1,0) [0|1] "" Vector__XXX
 SG_ VI_ATTR_VolumeRemovable m64 : 30|1@1+ (1,0) [0|1] "" Vector__XXX
 SG_ GA_ATTR_VolumeIsRemovable m50 : 30|1@1+ (1,0) [0|1] "" Vector__XXX
 SG_ VI_ATTR_SupportsLongFilenames m64 : 29|1@1+ (1,0) [0|1] "" Vector__XXX
 SG_ FDT_DateMonth m52 : 29|4@1+ (1,0) [0|12] "Month" Vector__XXX
 SG_ GA_ATTR_SupportsLongFilenames m50 : 29|1@1+ (1,0) [0|1] "" Vector__XXX
 SG_ GA_ATTR_IsDirectory m50 : 28|1@1+ (1,0) [0|1] "" Vector__XXX
 SG_ VI_ATTR_IsDirectory m64 : 28|1@1+ (1,0) [0|1] "" Vector__XXX
 SG_ VI_ATTR_IsVolume m64 : 27|1@1+ (1,0) [0|1] "" Vector__XXX
 SG_ GA_ATTR_IsVolume m50 : 27|1@1+ (1,0) [0|1] "" Vector__XXX
 SG_ VI_ATTR_VolumeSupportsHidden m64 : 26|1@1+ (1,0) [0|1] "" Vector__XXX
 SG_ GA_ATTR_VolumeSupportsHidden m50 : 26|1@1+ (1,0) [0|1] "" Vector__XXX
 SG_ VI_ATTR_Hidden m64 : 25|1@1+ (1,0) [0|1] "" Vector__XXX
 SG_ GA_ATTR_Hidden m50 : 25|1@1+ (1,0) [0|1] "" Vector__XXX
 SG_ VI_ATTR_ReadOnly m64 : 24|1@1+ (1,0) [0|1] "" Vector__XXX
 SG_ FDT_DateDay m52 : 24|5@1+ (1,0) [0|31] "Day" Vector__XXX
 SG_ GA_ATTR_ReadOnly m50 : 24|1@1+ (1,0) [0|1] "" Vector__XXX
 SG_ OF_Handle m32 : 24|8@1+ (1,0) [0|255] "" Vector__XXX
 SG_ GCD_TotalSpace m16 : 24|32@1+ (512,0) [0|4294966744] "Bytes" Vector__XXX
 SG_ RF_Count m34 : 24|16@1+ (1,0) [0|65535] "Bytes" Vector__XXX
 SG_ GSP_SupportMultipleVolumes m1 : 24|1@1+ (1,0) [0|255] "" Vector__XXX
 SG_ WF_Count m35 : 24|16@1+ (1,0) [0|65535] "" Vector__XXX
 SG_ VS_ErrorCode m2 : 24|8@1+ (1,0) [0|255] "" Vector__XXX
 SG_ FDT_ErrorCode m52 : 16|8@1+ (1,0) [0|255] "" Vector__XXX
 SG_ RF_ErrorCode m34 : 16|8@1+ (1,0) [0|255] "" Vector__XXX
 SG_ SF_ErrorCode m33 : 16|8@1+ (1,0) [0|255] "" Vector__XXX
 SG_ FSNumberOfOpenFiles m0 : 16|8@1- (1,0) [0|255] "" Vector__XXX
 SG_ OF_ErrorCode m32 : 16|8@1+ (1,0) [0|255] "" Vector__XXX
 SG_ WF_ErrorCode m35 : 16|8@1+ (1,0) [0|255] "" Vector__XXX
 SG_ CF_ErrorCode m36 : 16|8@1+ (1,0) [0|255] "" Vector__XXX
 SG_ MF_ErrorCode m48 : 16|8@1+ (1,0) [0|255] "" Vector__XXX
 SG_ GA_ErrorCode m50 : 16|8@1+ (1,0) [0|255] "" Vector__XXX
 SG_ SA_ErrorCode m51 : 16|8@1+ (1,0) [0|255] "" Vector__XXX
 SG_ GCD_ErrorCode m16 : 16|8@1+ (1,0) [0|255] "" Vector__XXX
 SG_ CCD_ErrorCode m17 : 16|8@1+ (1,0) [0|255] "" Vector__XXX
 SG_ GSP_MaxNrSimultaneousFilesOpen m1 : 16|8@1+ (1,0) [0|255] "" Vector__XXX
 SG_ DF_ErrorCode m49 : 16|8@1+ (1,0) [0|255] "" Vector__XXX
 SG_ VI_ErrorCode m64 : 16|8@1+ (1,0) [0|255] "" Vector__XXX
 SG_ VS_MaxTimeBeforeVolRemoval m2 : 16|8@1+ (1,0) [0|250] "min/bit" Vector__XXX
 SG_ FSBusyWriting m0 : 9|1@1+ (1,0) [0|1] "" Vector__XXX
 SG_ FSBusyReading m0 : 8|1@1+ (1,0) [0|1] "" Vector__XXX
 SG_ OF_TAN m32 : 8|8@1+ (1,0) [0|255] "" Vector__XXX
 SG_ SF_TAN m33 : 8|8@1+ (1,0) [0|255] "" Vector__XXX
 SG_ RF_TAN m34 : 8|8@1+ (1,0) [0|255] "" Vector__XXX
 SG_ WF_TAN m35 : 8|8@1+ (1,0) [0|255] "" Vector__XXX
 SG_ CF_TAN m36 : 8|8@1+ (1,0) [0|255] "" Vector__XXX
 SG_ MF_TAN m48 : 8|8@1+ (1,0) [0|255] "" Vector__XXX
 SG_ GA_TAN m50 : 8|8@1+ (1,0) [0|255] "" Vector__XXX
 SG_ SA_TAN m51 : 8|8@1+ (1,0) [0|255] "" Vector__XXX
 SG_ FDT_TAN m52 : 8|8@1+ (1,0) [0|255] "" Vector__XXX
 SG_ GCD_TAN m16 : 8|8@1+ (1,0) [0|255] "" Vector__XXX
 SG_ CCD_TAN m17 : 8|8@1+ (1,0) [0|255] "" Vector__XXX
 SG_ GSP_VersionNumber m1 : 8|8@1+ (1,0) [0|255] "" Vector__XXX
 SG_ DF_TAN m49 : 8|8@1+ (1,0) [0|255] "" Vector__XXX
 SG_ VI_TAN m64 : 8|8@1+ (1,0) [0|255] "" Vector__XXX
 SG_ VS_VolumeStatus m2 : 8|8@1+ (1,0) [0|3] "" Vector__XXX
 SG_ FSServerCommand M : 0|8@1+ (1,0) [0|255] "" Vector__XXX

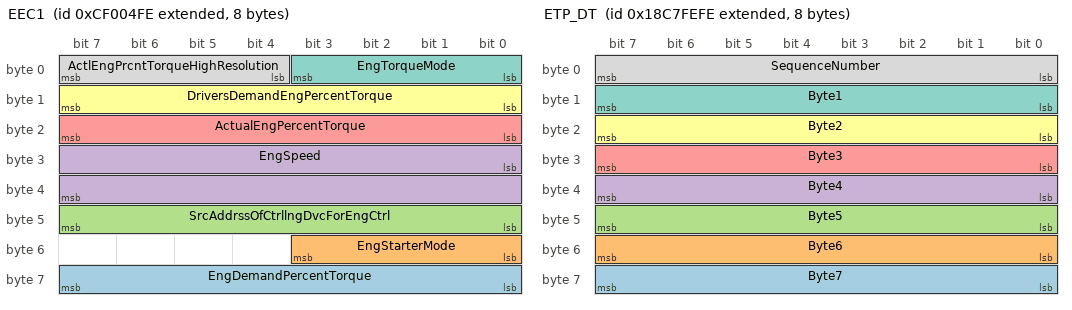
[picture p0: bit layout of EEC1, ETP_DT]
BO_ 2364540158 EEC1: 8 Vector__XXX
 SG_ EngDemandPercentTorque : 56|8@1+ (1,-125) [-125|125] "%" Vector__XXX
 SG_ EngStarterMode : 48|4@1+ (1,0) [0|15] "" Vector__XXX
 SG_ SrcAddrssOfCtrllngDvcForEngCtrl : 40|8@1+ (1,0) [0|255] "" Vector__XXX
 SG_ EngSpeed : 24|16@1+ (0.125,0) [0|8031.875] "rpm" Vector__XXX
 SG_ ActualEngPercentTorque : 16|8@1+ (1,-125) [-125|125] "%" Vector__XXX
 SG_ DriversDemandEngPercentTorque : 8|8@1+ (1,-125) [-125|125] "%" Vector__XXX
 SG_ EngTorqueMode : 0|4@1+ (1,0) [0|15] "" Vector__XXX
 SG_ ActlEngPrcntTorqueHighResolution : 4|4@1+ (0.125,0) [0|0.875] "%" Vector__XXX

BO_ 2563243774 ETP_DT: 8 Vector__XXX
 SG_ Byte7 : 56|8@1+ (1,0) [0|255] "" Vector__XXX
 SG_ Byte6 : 48|8@1+ (1,0) [0|255] "" Vector__XXX
 SG_ Byte5 : 40|8@1+ (1,0) [0|255] "" Vector__XXX
 SG_ Byte4 : 32|8@1+ (1,0) [0|255] "" Vector__XXX
 SG_ Byte3 : 24|8@1+ (1,0) [0|255] "" Vector__XXX
 SG_ Byte2 : 16|8@1+ (1,0) [0|255] "" Vector__XXX
 SG_ Byte1 : 8|8@1+ (1,0) [0|255] "" Vector__XXX
 SG_ SequenceNumber : 0|8@1+ (1,0) [1|255] "" Vector__XXX

BO_ 2563309310 ETP_CM: 8 Vector__XXX
 SG_ PGNumber : 40|24@1+ (1,0) [0|16777200] "" Vector__XXX
 SG_ DataPacketOffset m22 : 16|24@1+ (1,0) [0|16777215] "" Vector__XXX
 SG_ NextPacketNumberToSend m21 : 16|24@1+ (1,0) [1|16777215] "" Vector__XXX
 SG_ NumberOfBytesTransfered m23 : 8|32@1+ (1,0) [1786|117440505] "" Vector__XXX
 SG_ NumberOfPacketsOffset m22 : 8|8@1+ (1,0) [1|255] "" Vector__XXX
 SG_ NumberOfPacketsToSend m21 : 8|8@1+ (1,0) [1|255] "" Vector__XXX
 SG_ NumberOfBytesToTransfer m20 : 8|32@1+ (1,0) [1786|117440505] "" Vector__XXX
 SG_ ControlByte M : 0|8@1+ (1,0) [0|255] "" Vector__XXX
 SG_ ConnectionAbortReason m255 : 8|8@1+ (1,0) [0|255] "" Vector__XXX

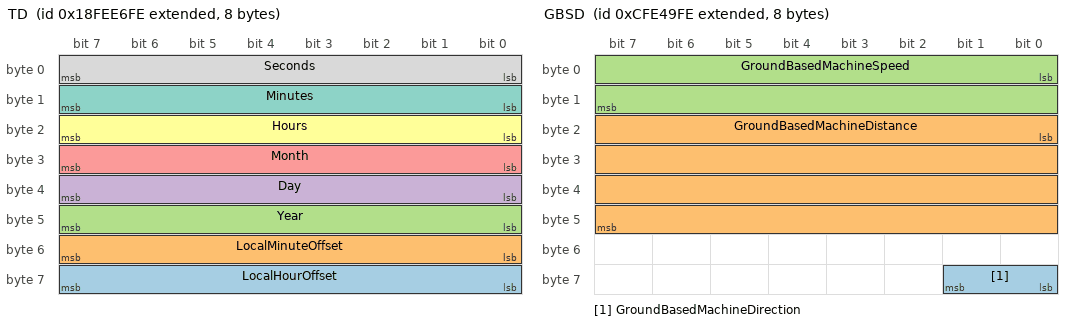
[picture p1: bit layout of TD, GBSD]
BO_ 2566842110 TD: 8 Vector__XXX
 SG_ LocalHourOffset : 56|8@1+ (1,-125) [-125|125] "hr" Vector__XXX
 SG_ LocalMinuteOffset : 48|8@1+ (1,-125) [-125|125] "mins" Vector__XXX
 SG_ Year : 40|8@1+ (1,1985) [1985|2235] "years" Vector__XXX
 SG_ Day : 32|8@1+ (0.25,0) [0|62.5] "days" Vector__XXX
 SG_ Month : 24|8@1+ (1,0) [0|250] "months" Vector__XXX
 SG_ Hours : 16|8@1+ (1,0) [0|250] "hr" Vector__XXX
 SG_ Minutes : 8|8@1+ (1,0) [0|250] "mins" Vector__XXX
 SG_ Seconds : 0|8@1+ (0.25,0) [0|62.5] "s" Vector__XXX

BO_ 2365475326 GBSD: 8 Vector__XXX
 SG_ GroundBasedMachineDirection : 56|2@1+ (1,0) [0|3] "" Vector__XXX
 SG_ GroundBasedMachineDistance : 16|32@1+ (0.001,0) [0|4211080] "m" Vector__XXX
 SG_ GroundBasedMachineSpeed : 0|16@1+ (0.001,0) [0|64.255] "m/s" Vector__XXX

CM_ BO_ 2628517377 "File Server to Client (ECU) message";
CM_ SG_ 2628517377 GCD_PathName "Length of path name string for Get Current Directory";
CM_ SG_ 2628517377 GCD_FreeSpace "Free Volume Space for Get Current Directory";
CM_ SG_ 2628517377 FDT_TimeHour "Hour of File Time";
CM_ SG_ 2628517377 FDT_TimeMinutes "Minutes of File Time";
CM_ SG_ 2628517377 FDT_TimeSeconds "Day of File Time";
CM_ SG_ 2628517377 FDT_DateYear "Year of File Date";
CM_ SG_ 2628517377 SF_Position "Position of Seek File response";
CM_ SG_ 2628517377 GA_Size "The number of bytes in a file.";
CM_ SG_ 2628517377 GA_ATTR_VolumeIsCaseSensitive "GetFileAttribute attribute 'Volume is case-sensitive'";
CM_ SG_ 2628517377 GA_ATTR_VolumeIsRemovable "GetFileAttribute attribute 'Volume is not removable'";
CM_ SG_ 2628517377 FDT_DateMonth "Month of File Date";
CM_ SG_ 2628517377 GA_ATTR_SupportsLongFilenames "GetFileAttribute attribute 'Volume supports long filenames'";
CM_ SG_ 2628517377 GA_ATTR_IsDirectory "GetFileAttribute attribute 'Handle specifies a directory'";
CM_ SG_ 2628517377 VI_ATTR_IsDirectory "File Attribute DirectoryFile Attribute DirectoryFile Attribute DirectoryFile Attribute Directory";
CM_ SG_ 2628517377 GA_ATTR_IsVolume "GetFileAttribute attribute 'Handle specifies a volume'";
CM_ SG_ 2628517377 GA_ATTR_VolumeSupportsHidden "GetFileAttribute attribute 'Volume supports hidden attribute'";
CM_ SG_ 2628517377 GA_ATTR_Hidden "GetFileAttribute attribute 'Hidden'";
CM_ SG_ 2628517377 FDT_DateDay "Day of File Date";
CM_ SG_ 2628517377 GA_ATTR_ReadOnly "GetFileAttribute attribute 'Read-Only'";
CM_ SG_ 2628517377 OF_Handle "Handle for Open File";
CM_ SG_ 2628517377 GCD_TotalSpace "Total Volume Space for Get Current Directory";
CM_ SG_ 2628517377 RF_Count "Number of read bytes or number of read directory entries";
CM_ SG_ 2628517377 GSP_SupportMultipleVolumes "File Server Capabilities for Get File Server Properties";
CM_ SG_ 2628517377 WF_Count "Number of written bytes";
CM_ SG_ 2628517377 FDT_ErrorCode "Error Code for Get File Data & Time";
CM_ SG_ 2628517377 RF_ErrorCode "Error Code for Read File";
CM_ SG_ 2628517377 SF_ErrorCode "ErrorCode for Seek File";
CM_ SG_ 2628517377 FSNumberOfOpenFiles "Number of open files";
CM_ SG_ 2628517377 OF_ErrorCode "Error Code for Open File";
CM_ SG_ 2628517377 WF_ErrorCode "Error Code for Write File";
CM_ SG_ 2628517377 CF_ErrorCode "Error Code for Close File";
CM_ SG_ 2628517377 MF_ErrorCode "Error Code for Move File";
CM_ SG_ 2628517377 GA_ErrorCode "Error Code for Get File Attribute";
CM_ SG_ 2628517377 SA_ErrorCode "Error Code for Set File Attribute";
CM_ SG_ 2628517377 GCD_ErrorCode "ErrorCode for Get Current Directory";
CM_ SG_ 2628517377 CCD_ErrorCode "Error Code for Change Current Directory";
CM_ SG_ 2628517377 GSP_MaxNrSimultaneousFilesOpen "The number of files that can maximally be opened simultaneous at the File Server.";
CM_ SG_ 2628517377 DF_ErrorCode "Error Code for Delete File";
CM_ SG_ 2628517377 VI_ErrorCode "Error Code for Volume Initialization";
CM_ SG_ 2628517377 FSBusyWriting "Busy writing";
CM_ SG_ 2628517377 FSBusyReading "Busy reading";
CM_ SG_ 2628517377 OF_TAN "Transaction Number for Open File";
CM_ SG_ 2628517377 SF_TAN "Transaction Number for Seek File";
CM_ SG_ 2628517377 RF_TAN "Transaction Number for Rename File";
CM_ SG_ 2628517377 WF_TAN "Transaction Number for Write File";
CM_ SG_ 2628517377 CF_TAN "Transaction Number for Close File";
CM_ SG_ 2628517377 MF_TAN "Transaction Number for Move File";
CM_ SG_ 2628517377 GA_TAN "Transaction Number for Get File Attributes";
CM_ SG_ 2628517377 SA_TAN "Transaction Number for Set File Attributes";
CM_ SG_ 2628517377 FDT_TAN "Transaction Number for Get File Data & Time";
CM_ SG_ 2628517377 GCD_TAN "Transaction Number for Get Current Directory";
CM_ SG_ 2628517377 CCD_TAN "Transaction Number for Change Current Directory";
CM_ SG_ 2628517377 GSP_VersionNumber "The version of ISO11783-13 that this File Server meets.";
CM_ SG_ 2628517377 DF_TAN "Transaction Number for Delete File";
CM_ SG_ 2628517377 VI_TAN "Transaction Number for Volume Initialization";
CM_ SG_ 2628517377 FSServerCommand "File Server Command";
CM_ BO_ 2628451851 "Client (ECU) to File Server message";
CM_ SG_ 2628451851 SA_ATTR_SupportsLongFilenames "SetFile Attribute 'Volume supports long filenames'";
CM_ SG_ 2628451851 SA_ATTR_VolumeSupportsHidden "SetFile Attribute 'Volume supports hidden attribute'";
CM_ SG_ 2628451851 SA_ATTR_VolumeIsRemovable "SetFile Attribute 'Volume is not removable'";
CM_ SG_ 2628451851 SA_ATTR_VolumeIsCaseSensitive "SetFile Attribute 'Volume is case-sensitive'";
CM_ SG_ 2628451851 SA_ATTR_IsVolume "SetFile Attribute 'Handle specifies a volume'";
CM_ SG_ 2628451851 SA_ATTR_IsDirectory "SetFile Attribute 'Handle specifies a directory'";
CM_ SG_ 2628451851 VI_VolumeName "Length of path name string for Initailize Volume Request";
CM_ SG_ 2628451851 VI_Flag_OverwriteExisting "Create a new volume if not yet existing (fails if existing volume)";
CM_ SG_ 2628451851 MF_DestinationPathNameLength "Length of destination path name string for Move File";
CM_ SG_ 2628451851 RF_ReportHiddenFiles "Report Hidden Files";
CM_ SG_ 2628451851 SF_Offset "Offset for Seek File";
CM_ SG_ 2628451851 RF_Count "Number of bytes or number of directory entries to be read";
CM_ SG_ 2628451851 SF_PositionMode "Position Mode for Seek File";
CM_ SG_ 2628451851 OF_PathName "Length of path name string for Open File";
CM_ SG_ 2628451851 MF_SourcePathNameLength "Length of source path name string for Move File";
CM_ SG_ 2628451851 WF_Count "Byte count of data to be written to file";
CM_ SG_ 2628451851 DF_PathName "Length of path name string for Delete File";
CM_ SG_ 2628451851 SA_PathName "Length of path name string for Set File Attributes";
CM_ SG_ 2628451851 VI_Space "The space in units of 512";
CM_ SG_ 2628451851 OF_FlagExclusiveAccess "Open file with exclusive access (fails if already open)";
CM_ SG_ 2628451851 OF_FlagAppend "Open file for appending data to the end of the file";
CM_ SG_ 2628451851 SA_ATTR_Hidden "SetFile Attribute 'Hidden'";
CM_ SG_ 2628451851 OF_FlagCreateNew "Create a new file if not yet existing";
CM_ SG_ 2628451851 MF_MoveModeRecursive "Recursive mode for Move File";
CM_ SG_ 2628451851 DF_DeleteModeRecursive "Recursive mode for Move File";
CM_ SG_ 2628451851 MF_MoveModeForce "Force mode for Move File";
CM_ SG_ 2628451851 DF_DeleteModeForce "Force mode for Move File";
CM_ SG_ 2628451851 VI_Flag_UsingSpaceSpecified "Create volume using space specified";
CM_ SG_ 2628451851 SA_ATTR_ReadOnly "SetFile Attribute Read-Only";
CM_ SG_ 2628451851 CF_Handle "Handle for Close File";
CM_ SG_ 2628451851 WF_Handle "Handle for Write File";
CM_ SG_ 2628451851 RF_Handle "Handle for Read File";
CM_ SG_ 2628451851 SF_Handle "Handle for Seek File";
CM_ SG_ 2628451851 OF_FlagReadWrite "Read/Write/Both/Directory Flag for Open File";
CM_ SG_ 2628451851 CCD_PathName "Length of path name string for Change Current Directory";
CM_ SG_ 2628451851 MF_MoveModeCopy "Copy mode for Move File";
CM_ SG_ 2628451851 DF_DeleteMode "Copy mode for Move File";
CM_ SG_ 2628451851 GA_PathName "Length of path name string for Get File Attributes";
CM_ SG_ 2628451851 FDT_PathName "Length of path name string for Get File Date and Time";
CM_ SG_ 2628451851 CCD_TAN "Transaction Number for Change Default Directory";
CM_ SG_ 2628451851 GCD_TAN "Transaction Number for Get Default Directory";
CM_ SG_ 2628451851 FDT_TAN "Transaction Number for Get File Data & Time";
CM_ SG_ 2628451851 SA_TAN "Transaction Number for Set File Attribute";
CM_ SG_ 2628451851 GA_TAN "Transaction Number for Get File Attribute";
CM_ SG_ 2628451851 RF_TAN "Transaction Number for Read File";
CM_ SG_ 2628451851 CF_TAN "Transaction Number for Close File";
CM_ SG_ 2628451851 WF_TAN "Transaction Number for Write File";
CM_ SG_ 2628451851 SF_TAN "Transaction Number for Seek File";
CM_ SG_ 2628451851 OF_TAN "Transaction Number for Open File";
CM_ SG_ 2628451851 MF_TAN "Transaction Number for Move File";
CM_ SG_ 2628451851 DF_TAN "Transaction Number for Delete File";
CM_ SG_ 2628451851 VI_TAN "Transaction Number for Initailize Volume Request";
CM_ SG_ 2628451851 FSClientCommand "File Server - Client Command";
CM_ BO_ 2628451850 "Client (ECU) to File Server message";
CM_ SG_ 2628451850 SA_ATTR_SupportsLongFilenames "SetFile Attribute 'Volume supports long filenames'";
CM_ SG_ 2628451850 SA_ATTR_VolumeSupportsHidden "SetFile Attribute 'Volume supports hidden attribute'";
CM_ SG_ 2628451850 SA_ATTR_VolumeIsRemovable "SetFile Attribute 'Volume is not removable'";
CM_ SG_ 2628451850 SA_ATTR_VolumeIsCaseSensitive "SetFile Attribute 'Volume is case-sensitive'";
CM_ SG_ 2628451850 SA_ATTR_IsVolume "SetFile Attribute 'Handle specifies a volume'";
CM_ SG_ 2628451850 SA_ATTR_IsDirectory "SetFile Attribute 'Handle specifies a directory'";
CM_ SG_ 2628451850 VI_VolumeName "Length of path name string for Initailize Volume Request";
CM_ SG_ 2628451850 VI_Flag_OverwriteExisting "Create a new volume if not yet existing (fails if existing volume)";
CM_ SG_ 2628451850 MF_DestinationPathNameLength "Length of destination path name string for Move File";
CM_ SG_ 2628451850 RF_ReportHiddenFiles "Report Hidden Files";
CM_ SG_ 2628451850 SF_Offset "Offset for Seek File";
CM_ SG_ 2628451850 RF_Count "Number of bytes or number of directory entries to be read";
CM_ SG_ 2628451850 SF_PositionMode "Position Mode for Seek File";
CM_ SG_ 2628451850 OF_PathName "Length of path name string for Open File";
CM_ SG_ 2628451850 MF_SourcePathNameLength "Length of source path name string for Move File";
CM_ SG_ 2628451850 WF_Count "Byte count of data to be written to file";
CM_ SG_ 2628451850 DF_PathName "Length of path name string for Delete File";
CM_ SG_ 2628451850 SA_PathName "Length of path name string for Set File Attributes";
CM_ SG_ 2628451850 VI_Space "The space in units of 512";
CM_ SG_ 2628451850 OF_FlagExclusiveAccess "Open file with exclusive access (fails if already open)";
CM_ SG_ 2628451850 OF_FlagAppend "Open file for appending data to the end of the file";
CM_ SG_ 2628451850 SA_ATTR_Hidden "SetFile Attribute 'Hidden'";
CM_ SG_ 2628451850 OF_FlagCreateNew "Create a new file if not yet existing";
CM_ SG_ 2628451850 MF_MoveModeRecursive "Recursive mode for Move File";
CM_ SG_ 2628451850 DF_DeleteModeRecursive "Recursive mode for Move File";
CM_ SG_ 2628451850 MF_MoveModeForce "Force mode for Move File";
CM_ SG_ 2628451850 DF_DeleteModeForce "Force mode for Move File";
CM_ SG_ 2628451850 VI_Flag_UsingSpaceSpecified "Create volume using space specified";
CM_ SG_ 2628451850 SA_ATTR_ReadOnly "SetFile Attribute Read-Only";
CM_ SG_ 2628451850 CF_Handle "Handle for Close File";
CM_ SG_ 2628451850 WF_Handle "Handle for Write File";
CM_ SG_ 2628451850 RF_Handle "Handle for Read File";
CM_ SG_ 2628451850 SF_Handle "Handle for Seek File";
CM_ SG_ 2628451850 OF_FlagReadWrite "Read/Write/Both/Directory Flag for Open File";
CM_ SG_ 2628451850 CCD_PathName "Length of path name string for Change Current Directory";
CM_ SG_ 2628451850 MF_MoveModeCopy "Copy mode for Move File";
CM_ SG_ 2628451850 DF_DeleteMode "Copy mode for Move File";
CM_ SG_ 2628451850 GA_PathName "Length of path name string for Get File Attributes";
CM_ SG_ 2628451850 FDT_PathName "Length of path name string for Get File Date and Time";
CM_ SG_ 2628451850 CCD_TAN "Transaction Number for Change Default Directory";
CM_ SG_ 2628451850 GCD_TAN "Transaction Number for Get Default Directory";
CM_ SG_ 2628451850 FDT_TAN "Transaction Number for Get File Data & Time";
CM_ SG_ 2628451850 SA_TAN "Transaction Number for Set File Attribute";
CM_ SG_ 2628451850 GA_TAN "Transaction Number for Get File Attribute";
CM_ SG_ 2628451850 RF_TAN "Transaction Number for Read File";
CM_ SG_ 2628451850 CF_TAN "Transaction Number for Close File";
CM_ SG_ 2628451850 WF_TAN "Transaction Number for Write File";
CM_ SG_ 2628451850 SF_TAN "Transaction Number for Seek File";
CM_ SG_ 2628451850 OF_TAN "Transaction Number for Open File";
CM_ SG_ 2628451850 MF_TAN "Transaction Number for Move File";
CM_ SG_ 2628451850 DF_TAN "Transaction Number for Delete File";
CM_ SG_ 2628451850 VI_TAN "Transaction Number for Initailize Volume Request";
CM_ SG_ 2628451850 FSClientCommand "File Server - Client Command";
CM_ BO_ 2565799425 "Address Claimed";
CM_ SG_ 2565799425 ReservedBit "The reserved bit shall be set to zero.";
CM_ BO_ 2565799435 "Address Claimed";
CM_ SG_ 2565799435 ReservedBit "The reserved bit shall be set to zero.";
CM_ BO_ 2565799434 "Address Claimed";
CM_ SG_ 2565799434 ReservedBit "The reserved bit shall be set to zero.";
CM_ BO_ 2628452094 "Client (ECU) to File Server message";
CM_ SG_ 2628452094 SA_ATTR_SupportsLongFilenames "SetFile Attribute 'Volume supports long filenames'";
CM_ SG_ 2628452094 SA_ATTR_VolumeSupportsHidden "SetFile Attribute 'Volume supports hidden attribute'";
CM_ SG_ 2628452094 SA_ATTR_VolumeIsRemovable "SetFile Attribute 'Volume is not removable'";
CM_ SG_ 2628452094 SA_ATTR_VolumeIsCaseSensitive "SetFile Attribute 'Volume is case-sensitive'";
CM_ SG_ 2628452094 SA_ATTR_IsVolume "SetFile Attribute 'Handle specifies a volume'";
CM_ SG_ 2628452094 SA_ATTR_IsDirectory "SetFile Attribute 'Handle specifies a directory'";
CM_ SG_ 2628452094 VI_VolumeName "Length of path name string for Initailize Volume Request";
CM_ SG_ 2628452094 VI_Flag_OverwriteExisting "Create a new volume if not yet existing (fails if existing volume)";
CM_ SG_ 2628452094 MF_DestinationPathNameLength "Length of destination path name string for Move File";
CM_ SG_ 2628452094 RF_ReportHiddenFiles "Report Hidden Files";
CM_ SG_ 2628452094 SF_Offset "Offset for Seek File";
CM_ SG_ 2628452094 RF_Count "Number of bytes or number of directory entries to be read";
CM_ SG_ 2628452094 SF_PositionMode "Position Mode for Seek File";
CM_ SG_ 2628452094 OF_PathName "Length of path name string for Open File";
CM_ SG_ 2628452094 MF_SourcePathNameLength "Length of source path name string for Move File";
CM_ SG_ 2628452094 WF_Count "Byte count of data to be written to file";
CM_ SG_ 2628452094 DF_PathName "Length of path name string for Delete File";
CM_ SG_ 2628452094 SA_PathName "Length of path name string for Set File Attributes";
CM_ SG_ 2628452094 VI_Space "The space in units of 512";
CM_ SG_ 2628452094 OF_FlagExclusiveAccess "Open file with exclusive access (fails if already open)";
CM_ SG_ 2628452094 OF_FlagAppend "Open file for appending data to the end of the file";
CM_ SG_ 2628452094 SA_ATTR_Hidden "SetFile Attribute 'Hidden'";
CM_ SG_ 2628452094 OF_FlagCreateNew "Create a new file if not yet existing";
CM_ SG_ 2628452094 MF_MoveModeRecursive "Recursive mode for Move File";
CM_ SG_ 2628452094 DF_DeleteModeRecursive "Recursive mode for Move File";
CM_ SG_ 2628452094 MF_MoveModeForce "Force mode for Move File";
CM_ SG_ 2628452094 DF_DeleteModeForce "Force mode for Move File";
CM_ SG_ 2628452094 VI_Flag_UsingSpaceSpecified "Create volume using space specified";
CM_ SG_ 2628452094 SA_ATTR_ReadOnly "SetFile Attribute Read-Only";
CM_ SG_ 2628452094 CF_Handle "Handle for Close File";
CM_ SG_ 2628452094 WF_Handle "Handle for Write File";
CM_ SG_ 2628452094 RF_Handle "Handle for Read File";
CM_ SG_ 2628452094 SF_Handle "Handle for Seek File";
CM_ SG_ 2628452094 OF_FlagReadWrite "Read/Write/Both/Directory Flag for Open File";
CM_ SG_ 2628452094 CCD_PathName "Length of path name string for Change Current Directory";
CM_ SG_ 2628452094 MF_MoveModeCopy "Copy mode for Move File";
CM_ SG_ 2628452094 DF_DeleteMode "Copy mode for Move File";
CM_ SG_ 2628452094 GA_PathName "Length of path name string for Get File Attributes";
CM_ SG_ 2628452094 FDT_PathName "Length of path name string for Get File Date and Time";
CM_ SG_ 2628452094 CCD_TAN "Transaction Number for Change Default Directory";
CM_ SG_ 2628452094 GCD_TAN "Transaction Number for Get Default Directory";
CM_ SG_ 2628452094 FDT_TAN "Transaction Number for Get File Data & Time";
CM_ SG_ 2628452094 SA_TAN "Transaction Number for Set File Attribute";
CM_ SG_ 2628452094 GA_TAN "Transaction Number for Get File Attribute";
CM_ SG_ 2628452094 RF_TAN "Transaction Number for Read File";
CM_ SG_ 2628452094 CF_TAN "Transaction Number for Close File";
CM_ SG_ 2628452094 WF_TAN "Transaction Number for Write File";
CM_ SG_ 2628452094 SF_TAN "Transaction Number for Seek File";
CM_ SG_ 2628452094 OF_TAN "Transaction Number for Open File";
CM_ SG_ 2628452094 MF_TAN "Transaction Number for Move File";
CM_ SG_ 2628452094 DF_TAN "Transaction Number for Delete File";
CM_ SG_ 2628452094 VI_TAN "Transaction Number for Initailize Volume Request";
CM_ SG_ 2628452094 FSClientCommand "File Server - Client Command";
CM_ BO_ 2628517630 "File Server to Client (ECU) message";
CM_ SG_ 2628517630 GCD_PathName "Length of path name string for Get Current Directory";
CM_ SG_ 2628517630 GCD_FreeSpace "Free Volume Space for Get Current Directory";
CM_ SG_ 2628517630 FDT_TimeHour "Hour of File Time";
CM_ SG_ 2628517630 FDT_TimeMinutes "Minutes of File Time";
CM_ SG_ 2628517630 FDT_TimeSeconds "Day of File Time";
CM_ SG_ 2628517630 FDT_DateYear "Year of File Date";
CM_ SG_ 2628517630 SF_Position "Position of Seek File response";
CM_ SG_ 2628517630 GA_Size "The number of bytes in a file.";
CM_ SG_ 2628517630 GA_ATTR_VolumeIsCaseSensitive "GetFileAttribute attribute 'Volume is case-sensitive'";
CM_ SG_ 2628517630 GA_ATTR_VolumeIsRemovable "GetFileAttribute attribute 'Volume is not removable'";
CM_ SG_ 2628517630 FDT_DateMonth "Month of File Date";
CM_ SG_ 2628517630 GA_ATTR_SupportsLongFilenames "GetFileAttribute attribute 'Volume supports long filenames'";
CM_ SG_ 2628517630 GA_ATTR_IsDirectory "GetFileAttribute attribute 'Handle specifies a directory'";
CM_ SG_ 2628517630 VI_ATTR_IsDirectory "File Attribute DirectoryFile Attribute DirectoryFile Attribute DirectoryFile Attribute Directory";
CM_ SG_ 2628517630 GA_ATTR_IsVolume "GetFileAttribute attribute 'Handle specifies a volume'";
CM_ SG_ 2628517630 GA_ATTR_VolumeSupportsHidden "GetFileAttribute attribute 'Volume supports hidden attribute'";
CM_ SG_ 2628517630 GA_ATTR_Hidden "GetFileAttribute attribute 'Hidden'";
CM_ SG_ 2628517630 FDT_DateDay "Day of File Date";
CM_ SG_ 2628517630 GA_ATTR_ReadOnly "GetFileAttribute attribute 'Read-Only'";
CM_ SG_ 2628517630 OF_Handle "Handle for Open File";
CM_ SG_ 2628517630 GCD_TotalSpace "Total Volume Space for Get Current Directory";
CM_ SG_ 2628517630 RF_Count "Number of read bytes or number of read directory entries";
CM_ SG_ 2628517630 GSP_SupportMultipleVolumes "File Server Capabilities for Get File Server Properties";
CM_ SG_ 2628517630 WF_Count "Number of written bytes";
CM_ SG_ 2628517630 FDT_ErrorCode "Error Code for Get File Data & Time";
CM_ SG_ 2628517630 RF_ErrorCode "Error Code for Read File";
CM_ SG_ 2628517630 SF_ErrorCode "ErrorCode for Seek File";
CM_ SG_ 2628517630 FSNumberOfOpenFiles "Number of open files";
CM_ SG_ 2628517630 OF_ErrorCode "Error Code for Open File";
CM_ SG_ 2628517630 WF_ErrorCode "Error Code for Write File";
CM_ SG_ 2628517630 CF_ErrorCode "Error Code for Close File";
CM_ SG_ 2628517630 MF_ErrorCode "Error Code for Move File";
CM_ SG_ 2628517630 GA_ErrorCode "Error Code for Get File Attribute";
CM_ SG_ 2628517630 SA_ErrorCode "Error Code for Set File Attribute";
CM_ SG_ 2628517630 GCD_ErrorCode "ErrorCode for Get Current Directory";
CM_ SG_ 2628517630 CCD_ErrorCode "Error Code for Change Current Directory";
CM_ SG_ 2628517630 GSP_MaxNrSimultaneousFilesOpen "The number of files that can maximally be opened simultaneous at the File Server.";
CM_ SG_ 2628517630 DF_ErrorCode "Error Code for Delete File";
CM_ SG_ 2628517630 VI_ErrorCode "Error Code for Volume Initialization";
CM_ SG_ 2628517630 FSBusyWriting "Busy writing";
CM_ SG_ 2628517630 FSBusyReading "Busy reading";
CM_ SG_ 2628517630 OF_TAN "Transaction Number for Open File";
CM_ SG_ 2628517630 SF_TAN "Transaction Number for Seek File";
CM_ SG_ 2628517630 RF_TAN "Transaction Number for Rename File";
CM_ SG_ 2628517630 WF_TAN "Transaction Number for Write File";
CM_ SG_ 2628517630 CF_TAN "Transaction Number for Close File";
CM_ SG_ 2628517630 MF_TAN "Transaction Number for Move File";
CM_ SG_ 2628517630 GA_TAN "Transaction Number for Get File Attributes";
CM_ SG_ 2628517630 SA_TAN "Transaction Number for Set File Attributes";
CM_ SG_ 2628517630 FDT_TAN "Transaction Number for Get File Data & Time";
CM_ SG_ 2628517630 GCD_TAN "Transaction Number for Get Current Directory";
CM_ SG_ 2628517630 CCD_TAN "Transaction Number for Change Current Directory";
CM_ SG_ 2628517630 GSP_VersionNumber "The version of ISO11783-13 that this File Server meets.";
CM_ SG_ 2628517630 DF_TAN "Transaction Number for Delete File";
CM_ SG_ 2628517630 VI_TAN "Transaction Number for Volume Initialization";
CM_ SG_ 2628517630 FSServerCommand "File Server Command";
CM_ BO_ 2364540158 "Electronic Engine Controller #1";
CM_ SG_ 2364540158 EngStarterMode "There are several phases in a starting action and different reasons why a start cannot take place.";
CM_ SG_ 2364540158 SrcAddrssOfCtrllngDvcForEngCtrl "The source address of the SAE J1939 device currently controlling the engine.";
CM_ SG_ 2364540158 ActualEngPercentTorque "The calculated output torque of the engine.";
CM_ SG_ 2364540158 DriversDemandEngPercentTorque "The requested torque output of the engine by the driver.";
CM_ SG_ 2364540158 EngTorqueMode "State signal which indicates which engine torque mode is currently generating, limiting, or controlling the torque.";
CM_ SG_ 2364540158 ActlEngPrcntTorqueHighResolution "This parameter displays an additional torque in percent of the reference engine torque.";
CM_ BO_ 2563243774 "Extended TP (Data)";
CM_ BO_ 2563309310 "Extended TP (Command)";
CM_ BO_ 2566842110 "Time/Date";
CM_ SG_ 2566842110 LocalHourOffset "The hour component of the offset between the UTC (Universal Time Coordinate) time and date and a local time zone time ...";
CM_ SG_ 2566842110 LocalMinuteOffset "The minute component of the offset between the UTC time and date and a local time zone time and date.  This is the ...";
CM_ SG_ 2566842110 Day "The day component of the current calendar date.  This should be reported as the day component of the current date at ...";
CM_ SG_ 2566842110 Hours "The hour component of the current time of day.  This should be reported as the hour component of the current time at ...";
CM_ SG_ 2566842110 Minutes "The minutes component of the current time of day.  This should be reported as the minutes component of the current time ...";
CM_ BO_ 2365475326 "Ground-based Speed and Distance";
BA_DEF_  "ISO11783_11_SpecVersion" STRING ;
BA_DEF_  "ISO11783_7_SpecVersion" STRING ;
BA_DEF_  "ISO11783_6_SpecVersion" STRING ;
BA_DEF_ SG_  "DDI" INT 0 65535;
BA_DEF_ BO_  "SingleFrame" INT 0 1;
BA_DEF_ BU_  "NodeLayerModules" STRING ;
BA_DEF_  "ProtocolType" STRING ;
BA_DEF_  "BusType" STRING ;
BA_DEF_  "ISO11783_TIM_SpecVersion" STRING ;
BA_DEF_ BU_  "NmStationAddress" INT 0 255;
BA_DEF_ BU_  "NmJ1939AAC" INT 0 1;
BA_DEF_ BU_  "NmJ1939IndustryGroup" INT 0 7;
BA_DEF_ BU_  "NmJ1939System" INT 0 127;
BA_DEF_ BU_  "NmJ1939SystemInstance" INT 0 15;
BA_DEF_ BU_  "NmJ1939Function" INT 0 255;
BA_DEF_ BU_  "NmJ1939FunctionInstance" INT 0 7;
BA_DEF_ BU_  "NmJ1939ECUInstance" INT 0 3;
BA_DEF_ BU_  "NmJ1939ManufacturerCode" INT 0 2047;
BA_DEF_ BU_  "NmJ1939IdentityNumber" INT 0 2097151;
BA_DEF_ BO_  "VFrameFormat" ENUM  "StandardCAN","ExtendedCAN","reserved","J1939PG","vector_leerstring";
BA_DEF_ BO_  "GenMsgSendType" ENUM  "cyclic","NotUsed","IfActive","NotUsed","NotUsed","NotUsed","NotUsed","NotUsed","noMsgSendType","vector_leerstring";
BA_DEF_ BO_  "GenMsgCycleTime" INT 0 3600000;
BA_DEF_ BO_  "GenMsgRequestable" INT 0 1;
BA_DEF_ BO_  "GenMsgCycleTimeFast" INT 0 3600000;
BA_DEF_ SG_  "SPN" INT 0 524287;
BA_DEF_  "DatabaseVersion" STRING ;
BA_DEF_ SG_  "GenSigSendType" ENUM  "Cyclic","OnWrite","OnWriteWithRepetition","OnChange","OnChangeWithRepetition","IfActive","IfActiveWithRepetition","NoSigSendType";
BA_DEF_ SG_  "SigType" ENUM  "Default","Range","RangeSigned","ASCII","Discrete","Control","ReferencePGN","DTC","StringDelimiter","StringLength","StringLengthControl","MessageCounter","MessageChecksum";
BA_DEF_  "ISO11783_12_SpecVersion" STRING ;
BA_DEF_  "ISO11783_13_SpecVersion" STRING ;
BA_DEF_ SG_  "GenSigStartValue" INT -2147483648 2147483647;
BA_DEF_ BU_  "ISO11783IOPVersion" ENUM  "0","1","2","3","4";
BA_DEF_ BU_  "ISO11783PDDVersion" ENUM  "0","1","2","3";
BA_DEF_ SG_  "SystemSignalLongSymbol" STRING ;
BA_DEF_DEF_  "ISO11783_11_SpecVersion" "";
BA_DEF_DEF_  "ISO11783_7_SpecVersion" "";
BA_DEF_DEF_  "ISO11783_6_SpecVersion" "";
BA_DEF_DEF_  "DDI" 0;
BA_DEF_DEF_  "SingleFrame" 1;
BA_DEF_DEF_  "NodeLayerModules" "";
BA_DEF_DEF_  "ProtocolType" "";
BA_DEF_DEF_  "BusType" "";
BA_DEF_DEF_  "ISO11783_TIM_SpecVersion" "";
BA_DEF_DEF_  "NmStationAddress" 254;
BA_DEF_DEF_  "NmJ1939AAC" 0;
BA_DEF_DEF_  "NmJ1939IndustryGroup" 0;
BA_DEF_DEF_  "NmJ1939System" 0;
BA_DEF_DEF_  "NmJ1939SystemInstance" 0;
BA_DEF_DEF_  "NmJ1939Function" 0;
BA_DEF_DEF_  "NmJ1939FunctionInstance" 0;
BA_DEF_DEF_  "NmJ1939ECUInstance" 0;
BA_DEF_DEF_  "NmJ1939ManufacturerCode" 0;
BA_DEF_DEF_  "NmJ1939IdentityNumber" 0;
BA_DEF_DEF_  "VFrameFormat" "J1939PG";
BA_DEF_DEF_  "GenMsgSendType" "noMsgSendType";
BA_DEF_DEF_  "GenMsgCycleTime" 0;
BA_DEF_DEF_  "GenMsgRequestable" 1;
BA_DEF_DEF_  "GenMsgCycleTimeFast" 0;
BA_DEF_DEF_  "SPN" 0;
BA_DEF_DEF_  "DatabaseVersion" "";
BA_DEF_DEF_  "GenSigSendType" "NoSigSendType";
BA_DEF_DEF_  "SigType" "Default";
BA_DEF_DEF_  "ISO11783_12_SpecVersion" "";
BA_DEF_DEF_  "ISO11783_13_SpecVersion" "";
BA_DEF_DEF_  "GenSigStartValue" 0;
BA_DEF_DEF_  "ISO11783IOPVersion" "3";
BA_DEF_DEF_  "ISO11783PDDVersion" "3";
BA_DEF_DEF_  "SystemSignalLongSymbol" "";
BA_ "ISO11783_12_SpecVersion" "2013-01-29 IS (ISO/TC 23/SC 19)";
BA_ "DatabaseVersion" "7.5 SP2";
BA_ "ProtocolType" "ISO11783";
BA_ "ISO11783_6_SpecVersion" "2010-05-11 FDIS";
BA_ "ISO11783_7_SpecVersion" "2009-01-29 FDIS";
BA_ "ISO11783_11_SpecVersion" "2007-04-01 IS";
BA_ "BusType" "CAN";
BA_ "ISO11783_13_SpecVersion" "2010-01-29 2007 With Amendments ";
BA_ "ISO11783_TIM_SpecVersion" "AEF 023 DIG 0_07 ISOBUS - ISOBUS Automation Principles";
BA_ "NmJ1939IdentityNumber" BU_ FSClient 13001;
BA_ "NmJ1939ManufacturerCode" BU_ FSClient 1861;
BA_ "NmJ1939Function" BU_ FSClient 255;
BA_ "NmJ1939IndustryGroup" BU_ FSClient 2;
BA_ "NmStationAddress" BU_ FSClient 10;
BA_ "NodeLayerModules" BU_ FSClient "ISO11783_IL.dll";
BA_ "NmJ1939IdentityNumber" BU_ FSBrowser 13101;
BA_ "NmJ1939ManufacturerCode" BU_ FSBrowser 1861;
BA_ "NmJ1939Function" BU_ FSBrowser 255;
BA_ "NmJ1939IndustryGroup" BU_ FSBrowser 2;
BA_ "NmStationAddress" BU_ FSBrowser 11;
BA_ "NodeLayerModules" BU_ FSBrowser "ISO11783_IL.dll";
BA_ "NmJ1939IdentityNumber" BU_ FileServer 25501;
BA_ "NmJ1939ManufacturerCode" BU_ FileServer 1861;
BA_ "NmJ1939Function" BU_ FileServer 61;
BA_ "NmJ1939IndustryGroup" BU_ FileServer 2;
BA_ "NmJ1939AAC" BU_ FileServer 1;
BA_ "NodeLayerModules" BU_ FileServer "ISO11783_FS_IL.dll";
BA_ "NmStationAddress" BU_ FileServer 1;
BA_ "GenMsgSendType" BO_ 2365475326 8.53594844804822E-317;
BA_ "GenMsgCycleTime" BO_ 2365475326 100;
BA_ "SigType" SG_ 2628517377 GCD_PathName 9;
BA_ "SigType" SG_ 2628517377 VS_VolumeName 9;
BA_ "SigType" SG_ 2628451851 VI_VolumeName 9;
BA_ "SigType" SG_ 2628451851 OF_PathName 9;
BA_ "SigType" SG_ 2628451851 DF_PathName 9;
BA_ "SigType" SG_ 2628451851 SA_PathName 9;
BA_ "SigType" SG_ 2628451851 CCD_PathName 9;
BA_ "SigType" SG_ 2628451851 GA_PathName 9;
BA_ "SigType" SG_ 2628451851 FDT_PathName 9;
BA_ "SigType" SG_ 2628451851 VS_VolumeName 8;
BA_ "SystemSignalLongSymbol" SG_ 2628451851 VS_RequestVolumeToPrepareForRemo "VS_RequestVolumeToPrepareForRemoval";
BA_ "SigType" SG_ 2628451850 VI_VolumeName 9;
BA_ "SigType" SG_ 2628451850 OF_PathName 9;
BA_ "SigType" SG_ 2628451850 DF_PathName 9;
BA_ "SigType" SG_ 2628451850 SA_PathName 9;
BA_ "SigType" SG_ 2628451850 CCD_PathName 9;
BA_ "SigType" SG_ 2628451850 GA_PathName 9;
BA_ "SigType" SG_ 2628451850 FDT_PathName 9;
BA_ "SigType" SG_ 2628451850 VS_VolumeName 8;
BA_ "SystemSignalLongSymbol" SG_ 2628451850 VS_RequestVolumeToPrepareFo_0000 "VS_RequestVolumeToPrepareForRemoval";
BA_ "SPN" SG_ 2565799425 ArbitraryAddressCapable 2844;
BA_ "SPN" SG_ 2565799425 IndustryGroup 2846;
BA_ "SPN" SG_ 2565799425 VehicleSystemInstance 2843;
BA_ "SPN" SG_ 2565799425 Function 2841;
BA_ "SPN" SG_ 2565799425 FunctionInstance 2839;
BA_ "SPN" SG_ 2565799425 ECUInstance 2840;
BA_ "SigType" SG_ 2565799425 ManufacturerCode 1;
BA_ "SPN" SG_ 2565799425 ManufacturerCode 2838;
BA_ "SPN" SG_ 2565799425 IdentityNumber 2837;
BA_ "SPN" SG_ 2565799435 ArbitraryAddressCapable 2844;
BA_ "SPN" SG_ 2565799435 IndustryGroup 2846;
BA_ "SPN" SG_ 2565799435 VehicleSystemInstance 2843;
BA_ "SPN" SG_ 2565799435 Function 2841;
BA_ "SPN" SG_ 2565799435 FunctionInstance 2839;
BA_ "SPN" SG_ 2565799435 ECUInstance 2840;
BA_ "SigType" SG_ 2565799435 ManufacturerCode 1;
BA_ "SPN" SG_ 2565799435 ManufacturerCode 2838;
BA_ "SPN" SG_ 2565799435 IdentityNumber 2837;
BA_ "SPN" SG_ 2565799434 ArbitraryAddressCapable 2844;
BA_ "SPN" SG_ 2565799434 IndustryGroup 2846;
BA_ "SPN" SG_ 2565799434 VehicleSystemInstance 2843;
BA_ "SPN" SG_ 2565799434 Function 2841;
BA_ "SPN" SG_ 2565799434 FunctionInstance 2839;
BA_ "SPN" SG_ 2565799434 ECUInstance 2840;
BA_ "SigType" SG_ 2565799434 ManufacturerCode 1;
BA_ "SPN" SG_ 2565799434 ManufacturerCode 2838;
BA_ "SPN" SG_ 2565799434 IdentityNumber 2837;
BA_ "SigType" SG_ 2628452094 VI_VolumeName 9;
BA_ "SigType" SG_ 2628452094 OF_PathName 9;
BA_ "SigType" SG_ 2628452094 DF_PathName 9;
BA_ "SigType" SG_ 2628452094 SA_PathName 9;
BA_ "SigType" SG_ 2628452094 CCD_PathName 9;
BA_ "SigType" SG_ 2628452094 GA_PathName 9;
BA_ "SigType" SG_ 2628452094 FDT_PathName 9;
BA_ "SigType" SG_ 2628452094 VS_VolumeName 8;
BA_ "SystemSignalLongSymbol" SG_ 2628452094 VS_RequestVolumeToPrepareFo_0001 "VS_RequestVolumeToPrepareForRemoval";
BA_ "SigType" SG_ 2628517630 GCD_PathName 9;
BA_ "SigType" SG_ 2628517630 VS_VolumeName 9;
BA_ "SPN" SG_ 2364540158 EngDemandPercentTorque 2432;
BA_ "SigType" SG_ 2364540158 EngDemandPercentTorque 1;
BA_ "SPN" SG_ 2364540158 EngStarterMode 1675;
BA_ "SPN" SG_ 2364540158 SrcAddrssOfCtrllngDvcForEngCtrl 1483;
BA_ "SPN" SG_ 2364540158 EngSpeed 190;
BA_ "SigType" SG_ 2364540158 EngSpeed 1;
BA_ "SPN" SG_ 2364540158 ActualEngPercentTorque 513;
BA_ "SigType" SG_ 2364540158 ActualEngPercentTorque 1;
BA_ "SPN" SG_ 2364540158 DriversDemandEngPercentTorque 512;
BA_ "SigType" SG_ 2364540158 DriversDemandEngPercentTorque 1;
BA_ "SPN" SG_ 2364540158 EngTorqueMode 899;
BA_ "SPN" SG_ 2364540158 ActlEngPrcntTorqueHighResolution 4154;
BA_ "SigType" SG_ 2563243774 Byte7 1;
BA_ "SigType" SG_ 2563243774 Byte6 1;
BA_ "SigType" SG_ 2563243774 Byte5 1;
BA_ "SigType" SG_ 2563243774 Byte4 1;
BA_ "SigType" SG_ 2563243774 Byte3 1;
BA_ "SigType" SG_ 2563243774 Byte2 1;
BA_ "SigType" SG_ 2563243774 Byte1 1;
BA_ "SigType" SG_ 2563243774 SequenceNumber 1;
BA_ "GenSigStartValue" SG_ 2563243774 SequenceNumber 1;
BA_ "SigType" SG_ 2563309310 PGNumber 6;
BA_ "SigType" SG_ 2563309310 DataPacketOffset 1;
BA_ "SigType" SG_ 2563309310 NextPacketNumberToSend 1;
BA_ "GenSigStartValue" SG_ 2563309310 NextPacketNumberToSend 1;
BA_ "SigType" SG_ 2563309310 NumberOfBytesTransfered 1;
BA_ "GenSigStartValue" SG_ 2563309310 NumberOfBytesTransfered 1786;
BA_ "SigType" SG_ 2563309310 NumberOfPacketsOffset 1;
BA_ "GenSigStartValue" SG_ 2563309310 NumberOfPacketsOffset 1;
BA_ "SigType" SG_ 2563309310 NumberOfPacketsToSend 1;
BA_ "GenSigStartValue" SG_ 2563309310 NumberOfPacketsToSend 1;
BA_ "SigType" SG_ 2563309310 NumberOfBytesToTransfer 1;
BA_ "GenSigStartValue" SG_ 2563309310 NumberOfBytesToTransfer 1786;
BA_ "SigType" SG_ 2563309310 ControlByte 1;
BA_ "SigType" SG_ 2566842110 LocalHourOffset 1;
BA_ "SPN" SG_ 2566842110 LocalHourOffset 1602;
BA_ "SigType" SG_ 2566842110 LocalMinuteOffset 1;
BA_ "SPN" SG_ 2566842110 LocalMinuteOffset 1601;
BA_ "SigType" SG_ 2566842110 Year 1;
BA_ "SPN" SG_ 2566842110 Year 964;
BA_ "SigType" SG_ 2566842110 Day 1;
BA_ "SPN" SG_ 2566842110 Day 962;
BA_ "SigType" SG_ 2566842110 Month 1;
BA_ "SPN" SG_ 2566842110 Month 963;
BA_ "SigType" SG_ 2566842110 Hours 1;
BA_ "SPN" SG_ 2566842110 Hours 961;
BA_ "SigType" SG_ 2566842110 Minutes 1;
BA_ "SPN" SG_ 2566842110 Minutes 960;
BA_ "SigType" SG_ 2566842110 Seconds 1;
BA_ "SPN" SG_ 2566842110 Seconds 959;
BA_ "SigType" SG_ 2365475326 GroundBasedMachineDirection 4;
BA_ "SPN" SG_ 2365475326 GroundBasedMachineDirection 1861;
BA_ "SigType" SG_ 2365475326 GroundBasedMachineDistance 1;
BA_ "SPN" SG_ 2365475326 GroundBasedMachineDistance 1860;
BA_ "SigType" SG_ 2365475326 GroundBasedMachineSpeed 1;
BA_ "SPN" SG_ 2365475326 GroundBasedMachineSpeed 1859;
VAL_ 2628517377 OF_ATTR_VolumeSupportsHidden 0 "No support of hidden attribute" 1 "Supports hidden attribute" ;
VAL_ 2628517377 OF_ATTR_VolumeIsCaseSensitive 0 "Is case-insensitive" 1 "Is case-sensitive" ;
VAL_ 2628517377 OF_ATTR_VolumeIsRemovable 0 "Is removable" 1 "Is not removable" ;
VAL_ 2628517377 OF_ATTR_SupportsLongFilenames 0 "Does not support long filename" 1 "Supports long filenames" ;
VAL_ 2628517377 OF_ATTR_IsDirectory 0 "Does not specifiy a directory" 1 "Specifes a directory" ;
VAL_ 2628517377 OF_ATTR_IsVolume 0 "Does not specifiy a volume" 1 "Specifies a volume" ;
VAL_ 2628517377 OF_ATTR_Hidden 0 "'Hidden' attribute is not set" 1 "'Hidden' attribute is set" ;
VAL_ 2628517377 OF_ATTR_ReadOnly 0 "'Read-only' attribute is not set" 1 "'Read-only' attribute is set" ;
VAL_ 2628517377 GA_ATTR_VolumeIsCaseSensitive 0 "Is case-insensitive" 1 "Is case-sensitive" ;
VAL_ 2628517377 VI_ATTR_VolumeRemovable 0 "Is removable" 1 "Is not removable" ;
VAL_ 2628517377 GA_ATTR_VolumeIsRemovable 0 "Is removable" 1 "Is not removable" ;
VAL_ 2628517377 VI_ATTR_SupportsLongFilenames 0 "Does not support long filename" 1 "Supports long filenames" ;
VAL_ 2628517377 GA_ATTR_SupportsLongFilenames 0 "Does not support long filename" 1 "Supports long filenames" ;
VAL_ 2628517377 GA_ATTR_IsDirectory 0 "Does not specifiy a directory" 1 "Specifes a directory" ;
VAL_ 2628517377 VI_ATTR_IsDirectory 0 "Does not specify a directory" 1 "Secifies a directory" ;
VAL_ 2628517377 VI_ATTR_IsVolume 0 "Does not specifiy a volume" 1 "Specifies a volume" ;
VAL_ 2628517377 GA_ATTR_IsVolume 0 "Does not specifiy a volume" 1 "Specifies a volume" ;
VAL_ 2628517377 VI_ATTR_VolumeSupportsHidden 0 "No support of hidden attribute" 1 "Supports hidden attribute" ;
VAL_ 2628517377 GA_ATTR_VolumeSupportsHidden 0 "No support of hidden attribute" 1 "Supports hidden attribute" ;
VAL_ 2628517377 VI_ATTR_Hidden 0 "'Hidden' attribute is not set" 1 "'Hidden' attribute is set" ;
VAL_ 2628517377 GA_ATTR_Hidden 0 "'Hidden' attribute is not set" 1 "'Hidden' attribute is set" ;
VAL_ 2628517377 VI_ATTR_ReadOnly 0 "'Read-only' attribute is not set" 1 "'Read-only' attribute is set" ;
VAL_ 2628517377 GA_ATTR_ReadOnly 0 "'Read-only' attribute is not set" 1 "'Read-only' attribute is set" ;
VAL_ 2628517377 GSP_SupportMultipleVolumes 0 "Beschreibung für den Wert '0'" ;
VAL_ 2628517377 FDT_ErrorCode 0 "Success" 1 "Access Denied" 3 "Too many files open" 4 "File, path or volume not found" 6 "Invalid given source name" 10 "Media is not present" 44 "Any other error" 43 "Out ot memory" 11 "Failure during a read operation" 13 " Volume possibly not initialized" ;
VAL_ 2628517377 RF_ErrorCode 45 "File pointer at end of file" 44 "Any other error" 42 "Invalid request length" 5 "Invalid handle" 0 "Success" 11 "Failure during read operation" 43 "Out of memory" 1 "Access denied" ;
VAL_ 2628517377 SF_ErrorCode 0 "Success" 5 "Invalid handle" 42 "Invalid request length" 44 "Any other error" 45 "File pointer at end of file" 11 "Failure during read operation" 43 "Out of memory" ;
VAL_ 2628517377 OF_ErrorCode 0 "Success" 1 "Access Denied" 2 "Invalid Access" 3 "Too many files open" 4 "File, path or volume not found" 6 "Invalid given source name" 8 "Volume out of free space" 10 "Media is not present" 44 "Any other error" 43 "Out of memory" 13 "Volume possibly not initialized" ;
VAL_ 2628517377 WF_ErrorCode 0 "Success" 1 "Access Denied" 5 "Invalid handle" 8 "Volume out of free space" 9 "Failure during a write operation" 42 "Invalid request length" 44 "Any other error" 43 "Out of memory" ;
VAL_ 2628517377 CF_ErrorCode 0 "Success" 1 "Access Denied" 5 "Invalid handle" 8 "Volume out of free space" 9 "Failure during a write operation" 44 "Any other error" 43 "Out ot memory" ;
VAL_ 2628517377 MF_ErrorCode 0 "Success" 1 "Access Denied" 3 "Too many files open" 6 "Invalid given source name" 7 "Invalid given destination name" 8 "Volume out of free space" 9 "Verify failure during a write op" 10 "Media is not present" 44 "Any other error" 43 "Out of memory" 4 "File, path or volume not found" 13 "Volume possibly not initialized" ;
VAL_ 2628517377 GA_ErrorCode 0 "Success" 1 "Access Denied" 3 "Too many files open" 4 "File, path or volume not found" 6 "Invalid given source name" 10 "Media is not present" 44 "Any other error" 43 "Out of memory" 11 "Failure during read operation" 13 "Volume possibly not initialized" ;
VAL_ 2628517377 SA_ErrorCode 0 "Success" 1 "Access Denied" 3 "Too many files open" 4 "File, path or volume not found" 6 "Invalid given source name" 8 "Volume out of free space" 9 "Failure during write operation" 10 "Media is not present" 44 "Any other error" 43 "Out of memory" 11 "Failure during read operation" 13 "Volume possibly not initialized" ;
VAL_ 2628517377 GCD_ErrorCode 0 "Success" 10 "Media is not present" 44 "Any other error" 43 "Out of Memory" 13 "Volume possibly not initialized" ;
VAL_ 2628517377 CCD_ErrorCode 0 "Success" 10 "Media is not present" 44 "Any other error" 43 "Out of memory" 13 "Volume possibly not initialized" 1 "Access denied" 2 "Invalid Access" 4 "File, path or volume not found" 7 "Invalid destination name given" ;
VAL_ 2628517377 DF_ErrorCode 0 "Success" 1 "Access Denied" 4 "File, path or volume not found" 6 "Invalid given source name" 10 "Media is not present" 44 "Any other error" 43 "Out of memory" 9 "Failure during write operation" 11 "Failure during read operation" 13 "Volume possibly not initialized" ;
VAL_ 2628517377 VI_ErrorCode 0 "Success" 1 "Access Denied" 4 "File, path or volume not found" 6 "Invalid given source name" 8 "Volume out of free space" 9 "Failure during write operation" 42 "Invalid request length" 44 "Any other error" 43 "Out of memory" 10 "Media is not present" 11 "Failure during read operation" 13 "Volume possibly not initialized" ;
VAL_ 2628517377 GSP_VersionNumber 0 "DIS" 1 "FDIS" 2 "FirstPublishedEditionOfIS" 3 "SecondPublishedEditionOfIS" 255 "CompliantToVersion2AndPrior" ;
VAL_ 2628517377 VS_VolumeStatus 0 "Present" 1 "InUse" 2 "PreparingForRemoval" 3 "Removed" ;
VAL_ 2628517377 FSServerCommand 0 "FileServerStatus" 16 "GetCurrentDirectoryResponse" 32 "OpenFileResponse" 33 "SeekFileResponse" 34 "ReadFileResponse" 35 "WriteFileResponse" 36 "CloseFileResponse" 48 "MoveFileResponse" 49 "DeleteFileResponse" 50 "GetFileAttributesResponse" 51 "SetFileAttributeResponse" 17 "ChangeCurrentDirectoryResponse" 52 "GetFileDateTimeResponse" 64 "VolumeInitializationResponse" 1 "GetFileServerPropertiesResponse" 2 "VolumeStatusResponse" ;
VAL_ 2628451851 SA_ATTR_SupportsLongFilenames 0 "Does not support long file names" 1 "Supports long file names" ;
VAL_ 2628451851 SA_ATTR_VolumeSupportsHidden 0 "No support of hidden attribute" 1 "Supports hidden attribute" ;
VAL_ 2628451851 SA_ATTR_VolumeIsRemovable 0 "Is not removable" 1 "Is removable" ;
VAL_ 2628451851 SA_ATTR_VolumeIsCaseSensitive 0 "Is case-insensitive" 1 "Is case-sensitive" ;
VAL_ 2628451851 SA_ATTR_IsVolume 0 "Does not specify a volume " 1 "Specifies a volume" ;
VAL_ 2628451851 SA_ATTR_IsDirectory 0 "Does not specify a directory" 1 "Specifies a directory" ;
VAL_ 2628451851 RF_ReportHiddenFiles 0 "DoNotReportHiddenFiles" 1 "ReportHiddenFiles" 255 "NotAvailable" ;
VAL_ 2628451851 SF_PositionMode 0 "From the beginning of the file" 1 "From the current pointer pos" 2 "From the end of the file" ;
VAL_ 2628451851 OF_FlagExclusiveAccess 0 "Open file for shared read access" 1 "Open file with exclusive access" ;
VAL_ 2628451851 OF_FlagAppend 0 "Open file for random access" 1 "Open file for appending data" ;
VAL_ 2628451851 SA_ATTR_Hidden 0 "'Hidden' attribute is not set" 1 "'Hidden' attribute is set" ;
VAL_ 2628451851 OF_FlagCreateNew 0 "Open an existing file" 1 "Create new file if not existing" ;
VAL_ 2628451851 MF_MoveModeRecursive 0 "'recursive' mode is not set" 1 "'recursive' mode is set" ;
VAL_ 2628451851 DF_DeleteModeRecursive 0 "'recursive' mode is not set" 1 "'recursive' mode is set" ;
VAL_ 2628451851 MF_MoveModeForce 0 "'force' mode is not set" 1 "'force' mode is set" ;
VAL_ 2628451851 DF_DeleteModeForce 0 "'force' mode is not set" 1 "'force' mode is set" ;
VAL_ 2628451851 SA_ATTR_ReadOnly 0 "'Read-only' attribute is not set" 1 "'Read-only' attribute is set" ;
VAL_ 2628451851 OF_FlagReadWrite 0 "Open file for reading only" 1 "Open file for writing only" 2 "Open file for reading & writing" 3 "Open directory for reading" ;
VAL_ 2628451851 MF_MoveModeCopy 0 "'copy' mode is not set" 1 "'copy' mode is set" ;
VAL_ 2628451851 DF_DeleteMode 0 "'copy' mode is not set" 1 "'copy' mode is set" ;
VAL_ 2628451851 VS_RequestVolumeToPrepareForRemo 1 "RequestVolumeToPrepareForRemoval" ;
VAL_ 2628451851 VS_ReportVolumeUsedByClient 0 "ReportVolumeNotInUseByClient" 1 "ReportVolumeInUseByClient" ;
VAL_ 2628451851 CM_VersionNumber 0 "DIS" 1 "FDIS" 2 "FirstPublishedEditionOfIS" 3 "SecondPublishedEditionOfIS" 255 "CompliantToVersion2AndPrior" ;
VAL_ 2628451851 FSClientCommand 0 "ConnectionMaintenance" 16 "GetCurrentDirectoryRequest" 32 "OpenFileRequest" 33 "SeekFileRequest" 34 "ReadFileRequest" 35 "WriteFileRequest" 36 "CloseFileRequest" 48 "MoveFileRequest" 49 "DeleteFileRequest" 50 "GetFileAttributesRequest" 51 "SetFileAttributesRequest" 17 "ChangeCurrentDirectoryRequest" 52 "GetFileDateTimeRequest" 64 "VolumeInitializationRequest" 1 "GetFileServerProperties" 2 "VolumeStatusRequest" ;
VAL_ 2628451850 SA_ATTR_SupportsLongFilenames 0 "Does not support long file names" 1 "Supports long file names" ;
VAL_ 2628451850 SA_ATTR_VolumeSupportsHidden 0 "No support of hidden attribute" 1 "Supports hidden attribute" ;
VAL_ 2628451850 SA_ATTR_VolumeIsRemovable 0 "Is not removable" 1 "Is removable" ;
VAL_ 2628451850 SA_ATTR_VolumeIsCaseSensitive 0 "Is case-insensitive" 1 "Is case-sensitive" ;
VAL_ 2628451850 SA_ATTR_IsVolume 0 "Does not specify a volume " 1 "Specifies a volume" ;
VAL_ 2628451850 SA_ATTR_IsDirectory 0 "Does not specify a directory" 1 "Specifies a directory" ;
VAL_ 2628451850 RF_ReportHiddenFiles 0 "DoNotReportHiddenFiles" 1 "ReportHiddenFiles" 255 "NotAvailable" ;
VAL_ 2628451850 SF_PositionMode 0 "From the beginning of the file" 1 "From the current pointer pos" 2 "From the end of the file" ;
VAL_ 2628451850 OF_FlagExclusiveAccess 0 "Open file for shared read access" 1 "Open file with exclusive access" ;
VAL_ 2628451850 OF_FlagAppend 0 "Open file for random access" 1 "Open file for appending data" ;
VAL_ 2628451850 SA_ATTR_Hidden 0 "'Hidden' attribute is not set" 1 "'Hidden' attribute is set" ;
VAL_ 2628451850 OF_FlagCreateNew 0 "Open an existing file" 1 "Create new file if not existing" ;
VAL_ 2628451850 MF_MoveModeRecursive 0 "'recursive' mode is not set" 1 "'recursive' mode is set" ;
VAL_ 2628451850 DF_DeleteModeRecursive 0 "'recursive' mode is not set" 1 "'recursive' mode is set" ;
VAL_ 2628451850 MF_MoveModeForce 0 "'force' mode is not set" 1 "'force' mode is set" ;
VAL_ 2628451850 DF_DeleteModeForce 0 "'force' mode is not set" 1 "'force' mode is set" ;
VAL_ 2628451850 SA_ATTR_ReadOnly 0 "'Read-only' attribute is not set" 1 "'Read-only' attribute is set" ;
VAL_ 2628451850 OF_FlagReadWrite 0 "Open file for reading only" 1 "Open file for writing only" 2 "Open file for reading & writing" 3 "Open directory for reading" ;
VAL_ 2628451850 MF_MoveModeCopy 0 "'copy' mode is not set" 1 "'copy' mode is set" ;
VAL_ 2628451850 DF_DeleteMode 0 "'copy' mode is not set" 1 "'copy' mode is set" ;
VAL_ 2628451850 VS_RequestVolumeToPrepareFo_0000 1 "RequestVolumeToPrepareForRemoval" ;
VAL_ 2628451850 VS_ReportVolumeUsedByClient 0 "ReportVolumeNotInUseByClient" 1 "ReportVolumeInUseByClient" ;
VAL_ 2628451850 CM_VersionNumber 0 "DIS" 1 "FDIS" 2 "FirstPublishedEditionOfIS" 3 "SecondPublishedEditionOfIS" 255 "CompliantToVersion2AndPrior" ;
VAL_ 2628451850 FSClientCommand 0 "ConnectionMaintenance" 16 "GetCurrentDirectoryRequest" 32 "OpenFileRequest" 33 "SeekFileRequest" 34 "ReadFileRequest" 35 "WriteFileRequest" 36 "CloseFileRequest" 48 "MoveFileRequest" 49 "DeleteFileRequest" 50 "GetFileAttributesRequest" 51 "SetFileAttributesRequest" 17 "ChangeCurrentDirectoryRequest" 52 "GetFileDateTimeRequest" 64 "VolumeInitializationRequest" 1 "GetFileServerProperties" 2 "VolumeStatusRequest" ;
VAL_ 2565799425 IndustryGroup 7 "Reserved for SAE" 5 "IndustrialProcessCtrlStationary" 4 "Marine" 3 "Construction" 2 "Agricultural and Forestry" 1 "On-Highway" 0 "Global" ;
VAL_ 2565799425 VehicleSystem 127 "Not Available" 0 "Non-specific System" ;
VAL_ 2565799425 VehicleSystem5 0 "Ind. Process Control Stationary" 127 "Not Available" ;
VAL_ 2565799425 VehicleSystem4 0 "Non-specific System" 127 "Not Available" 10 "System Tools" 20 "Safety Systems" 25 "Inter/Intranetwork Device" 30 "Electrical Distribution" 40 "Steering and Control Surfaces" 50 "Propulsion" 60 "Navigation" 70 "Communications" 80 "Instrumentation/General Systems (deprecate)" 90 "Internal Environment" 100 "Deck, Cargo and Fishing Equipment" 35 "Electrical Generation" 75 "Sensor Communication Interface" 85 "External Environment" 120 "Display" 125 "Entertainment" ;
VAL_ 2565799425 VehicleSystem3 0 "Non-specific System" 127 "Not Available" 1 "Skid Steer Loader" 2 "Articulated Dump Truck" 3 "Backhoe" 4 "Crawler" 5 "Excavator" 6 "Forklift" 7 "Four Wheel Drive Loader" 8 "Grader" ;
VAL_ 2565799425 VehicleSystem2 0 "Non-specific System" 127 "Not Available" 1 "Tractor" 2 "Tillage" 3 "Secondary Tillage" 4 "Planters/Seeders" 5 "Fertilizers" 6 "Sprayers" 7 "Harvesters" 8 "Root Harvesters" 9 "Forage" 10 "Irrigation" 11 "Transport/Trailer" 12 "Farm Yard Operations" 13 "Powered Auxiliary Device" 14 "Special Crops" 15 "Earth Work" 16 "Skidder" 17 "Sensor Systems" 19 "Timber Harvesters" 20 "Forwarders" 21 "Timber loaders" 22 "Timber Processing Machines" 23 "Mulchers" 24 "Utility Vehicles" 25 "Slurry Applicators" ;
VAL_ 2565799425 VehicleSystem1 0 "Non-specific System" 127 "Not Available" 1 "Tractor" 2 "Trailer" ;
VAL_ 2565799425 Function 43 "Transmission Display" 44 "Exhaust Emission Control" 45 "Vehicle Dynamic Stability Control" 46 "Oil Sensor Unit" 47 "Information System Controller" 48 "Ramp Control" 49 "Clutch/Converter Control" 50 "Auxiliary Heater" 51 "Forward-Looking Collision Warning System" 52 "Chassis Controller" 53 "Alternator/Charging System" 54 "Communications Unit, Cellular" 55 "Communications Unit, Satellite" 56 "Communications Unit, Radio" 57 "Steering Column Unit" 58 "Fan Drive Control" 59 "Starter" 60 "Cab Display" 61 "File Server/Printer" 62 "On-Board Diagnostic Unit" 63 "Engine Valve Controller" 64 "Endurance Braking" 65 "Gas Flow Measurement" 66 "I/O Controller" 67 "Electrical System Controller" 68 "Aftertreatment system gas measurement" 69 "Engine Emission Aftertreatement System" 70 "Auxiliary Regeneration Device" 71 "Transfer Case Control" 72 "Coolant Valve Controller" 73 "Rollover Detection Control" 74 "Lubrication System" 75 "Supplemental Fan" 76 "Temperature Sensor" 77 "Fuel Properties Sensor" 78 "Fire Suppression System" 79 "Power Systems Manager" 80 "Electric Powertrain" 81 "Hydraulic Powertrain" 82 "File Server" 83 "Printer" 84 "Start Aid Device" 85 "Engine Injection Control Module" 86 "Reserved" 87 "Reserved" 88 "Reserved" 89 "Reserved" 90 "Reserved" 91 "Reserved" 92 "Reserved" 93 "Reserved" 94 "Reserved" 95 "Reserved" 96 "Reserved" 97 "Reserved" 98 "Reserved" 99 "Reserved" 100 "Reserved" 0 "Engine" 1 "Auxiliary Power Unit (APU)" 2 "Electric Propulsion Control" 3 "Transmission" 4 "Battery Pack Monitor" 5 "Shift Control/Console" 6 "Power TakeOff - (Main or Rear)" 7 "Axle - Steering" 8 "Axle - Drive" 9 "Brakes - System Controller" 10 "Brakes - Steer Axle" 11 "Brakes - Drive Axle" 12 "Retarder - Engine" 13 "Retarder - Driveline" 14 "Cruise Control" 15 "Fuel System" 16 "Steering Controller" 17 "Suspension - Steer Axle" 18 "Suspension - Drive Axle" 19 "Instrument Cluster" 20 "Trip Recorder" 21 "Cab Climate Control" 22 "Aerodynamic Control" 23 "Vehicle Navigation" 24 "Vehicle Security" 25 "Network Interconnect ECU" 26 "Body Controller" 27 "Power TakeOff (Secondary or Front)" 28 "Off Vehicle Gateway" 29 "Virtual Terminal (in cab)" 30 "Management Computer" 31 "Propulsion Battery Charger" 32 "Headway Controller" 33 "System Monitor" 34 "Hydraulic Pump Controller" 35 "Suspension - System Controller" 36 "Pneumatic - System Controller" 37 "Cab Controller" 38 "Tire Pressure Control" 39 "Ignition Control Module" 40 "Seat Control" 41 "Lighting - Operator Controls" 42 "Water Pump Control" 101 "Reserved" 102 "Reserved" 103 "Reserved" 104 "Reserved" 105 "Reserved" 106 "Reserved" 107 "Reserved" 108 "Reserved" 109 "Reserved" 110 "Reserved" 111 "Reserved" 112 "Reserved" 113 "Reserved" 114 "Reserved" 115 "Reserved" 116 "Reserved" 117 "Reserved" 118 "Reserved" 119 "Reserved" 120 "Reserved" 121 "Reserved" 122 "Reserved" 123 "Reserved" 124 "Reserved" 125 "Reserved" 126 "Reserved" 127 "Reserved" 128 "Non Virtual Terminal Display" 129 "Operator Controls" 130 "Task Controller" 131 "Position Control" 132 "Machine Control" 133 "Foreign Object Detection" 134 "Tractor ECU" 135 "Sequence Control Master" 136 "Product Dosing" 137 "Product Treatment" 138 "Reserved" 139 "Data Logger" 140 "Decision Support" 141 "Lighting Controller" 142 "TIM Server" 255 "Not Available" ;
VAL_ 2565799425 ManufacturerCode 1863 "Thomas G. Faria Co." 1862 "Sanshin" 1861 "Vector North America " 1860 "MMP" 1859 "Kvasar AB" 1858 "Litton" 1857 "Simrad" 1856 "Trimble" 1855 "Furuno USA" 1854 "Northstar Technologies" 1853 "Japan Radio Co" 1852 "Navionics" 1851 "RayMarine" 1850 "Teleflex" 786 "Johnson Matthey Battery Systems" 785 "Fischer Panda GmbH" 784 "CM Automotive Systems, Inc." 783 "Loup Electronics Inc." 782 "AVR bvba" 781 "Poly-Planar LLC" 780 "AVID Technology Ltd" 779 "RLC Electronic Systems" 778 "Seakeeper Inc." 777 "Ocean Signal Ltd" 776 "HMI Systems LLC" 775 "ZIEHL-ABEGG Automotive GmbH" 774 "Taisho Corporation" 773 "Clarion Corporation of America" 772 "Blink Marine" 771 "Shaw Development, LLC" 770 "MONOSEM" 769 "Trombetta" 768 "Flores Automation, LLC" 767 "Alliance Wireless Technologies Inc." 766 "Epec Oy" 765 "GIGAVAC" 764 "Bednar FMT s.r.o." 763 "AT-Systems BVBA" 762 "ROJ s.r.l." 761 "MITA OLEODINAMICA S.p.A." 760 "Bernecker + Rainer Industrie Elektronik GmbH" 759 "Hydro-Gear" 758 "Banner Engineering Corp." 757 "IMPCO Technologies" 756 "Maschio Gaspardo S.P.A." 755 "Firefly Integrations" 754 "Parker Hannifin Corp., Automation Group" 753 "AIROD Technologies" 752 "Deep Sea Electronics Plc" 751 "Pacific Track" 750 "Joskin SA" 749 "Chart Inc." 748 "ISOTTA" 747 "Agratronix" 746 "SureFire Ag Systems, Inc." 745 "Cidra Corporate Services Inc." 744 "Woosung Engineering Co., Ltd." 743 "Daemyung Elevator Co., Ltd." 742 "EROAD" 741 "Carling Technologies" 740 "e-Traction" 739 "LXNAV d.o.o." 738 "Blue Ink Technologies" 737 "Balluff GmbH" 736 "Terex Aerial Work Platforms - Genie" 735 "AEM Performance Electronics" 734 "REAPsystems" 733 "Intendia S.L." 732 "Gefran S.p.A." 731 "Modine Manufacturing Company" 730 "BERTHOUD AGRICOLE" 729 "Liebherr" 728 "Streumaster / Panien" 727 "Dhoot Transmission Pvt Ltd." 726 "MIDORI PRECISIONS" 725 "Hitachi Construction Machinery Co., Ltd." 724 "Electronic Applications, Inc." 723 "Jabil Inc." 722 "Contelec AG" 721 "Hypro" 720 "WITZ Corporation" 719 "Cojali S. L." 718 "Micronet Inc" 717 "Yacht Devices Ltd" 716 "Eaton Control & Power Conversion Division (CPCD)" 715 "Autonnic Research Ltd" 714 "Kobashi Kogyo Co., Ltd." 713 "US Hybrid Corporation" 712 "LOR Manufacturing Company Inc." 711 "DAS Co., LTD" 710 "Greentronics Ltd." 709 "Marquardt GmbH" 708 "Lars Thrane A/S" 707 "Rochester Gauges Inc" 706 "Shanghai Diesel Engine Corporation Limited" 705 "SVAB Hydraulik AB" 704 "JL Audio, Inc." 703 "Hydro Tab Marine Engineering" 702 "Weichai Power Co., Ltd." 701 "BigRoad Inc." 700 "K-Tec Earthmovers Inc." 699 "Harman International Industries" 698 "Scorpion Technologies Ltd." 697 "Ålö AB" 696 "DRS Network & Imaging Systems, LLC (DRS Technologies)" 695 "Weldon Technologies" 694 "GasTOPS Ltd." 693 "Agility Fuel Solutions (formerly Agility Fuel Systems)" 692 "Tanhay Corporation" 691 "Digitroll Agricultural Electronics" 690 "LINAK A/S" 689 "Aarcomm Systems Inc" 688 "Rockford Corp" 687 "Flight Systems, Inc." 686 "Taigene Electric Machinery Corp." 685 "ANEDO Ltd." 684 "KEB" 683 "Fosen Elektro" 682 "Eckelmann AG" 681 "BEDIA Motorentechnik GmbH & Co. KG" 680 "AMVAC Chemical Corporation" 679 "Cimco Marine AB" 678 "KeepTruckin, Inc." 677 "DSA Daten- und Systemtechnik GmbH" 676 "Danfoss IXA A/S" 675 "Kawasaki Motors Corp., USA" 674 "Yara International ASA" 673 "Caruelle Nicolas" 672 "OPTIMA Concept" 671 "Innovative Controls Inc." 670 "STEMCO LP" 669 "Quantum Fuel Systems Technologies Worldwide, Inc" 668 "MacDon Industries Ltd." 667 "Bartec" 666 "Schaeffler Technologies AG & Co., KG" 665 "Gebr. Bode GmbH & Co. KG" 664 "Level Developments Ltd" 663 "Delta Systems, Inc" 662 "Kissling Elektrotechnik GmbH" 661 "SPAL Automotive S.r.l." 660 "Auto-Gaz Centrum" 659 "Data Panel Corp." 658 "Shenzhen Jiuzhou Himunication Technology Co., Ltd" 657 "Terzo Power Systems" 656 "PRO SOLUS do Brasil" 655 "Genge & Thoma AG" 654 "Kohler Power Systems, Detroit Engine Development Center (DEDC)" 653 "AEV, spol. s r. o." 652 "MicroControl GmbH & Co. KG" 651 "Takakita Co, Ltd." 650 "Seiko Epson Corp." 649 "Control-Q BV" 648 "OJSC Ekran" 647 "Siloking" 646 "Veenhuis Machines BV" 645 "esd electronic system design gmbh" 644 "KUS USA" 643 "Bogballe A/S" 642 "Moog / Aspen Motion Technologies" 641 "Diverse Yacht Services" 640 "Power Solutions International" 639 "Startec s.r.l." 638 "KVH Industries, Inc." 637 "Bavaria Yachtbau GmbH" 636 "Divelbiss Corporation" 635 "Argo Tractors S.p.A." 634 "Rocky Research" 633 "TORC Robotics" 632 "Pepperl+Fuchs GmbH" 631 "Reltima" 630 "SmartDrive Systems Inc." 629 "Agri Info Design, Ltd." 524 "Vomax Instrumentation Pty. Ltd." 523 "Reggio Emilia Innovazione" 522 "Nebraska Tractor Test Laboratory" 521 "Clever Devices Ltd." 520 "Trapeze" 519 "Peeters Landbouwmachines b.v." 518 "Transas USA Inc." 517 "Noland Engineering" 516 "AVAT Automation GmbH" 515 "GINAF Trucks Nederland B.V." 514 "DISTek Integration, Inc." 513 "FarmscanAg" 512 "Inpower LLC" 511 "Sulky" 510 "Marinesoft Co. Ltd" 509 "MOTORTECH GmbH" 508 "Transtech Innovations" 507 "ISOBUS Test Center" 506 "IHI STAR Machinery Corporation" 505 "Yetter Farm Equipment" 504 "Vesper Marine" 503 "Naviop S.R.L." 502 "Attwood Corporation" 501 "Agrotronix S.A." 500 "Oxbo International Corporation" 499 "LCJ Capteurs" 498 "Innovative Design Solutions, Inc." 497 "SENTRON Sistemas Embarcados" 496 "W. Gessmann GmbH" 495 "HOLMER Maschinenbau GmbH" 494 "Synerject" 493 "Watcheye" 492 "Inergy Automotive Systems" 491 "Penny and Giles Ltd" 490 "QuikQ" 489 "Appareo Systems, LLC" 488 "The Charles Machine Works, Inc." 487 "DSE Test Solutions A/S" 486 "Westport Innovations Inc." 485 "MATT automotive" 484 "Headsight Inc." 483 "Valeo" 482 "Tricon Electronics" 481 "Chetco Digital Instruments" 480 "EnerDel, Inc." 479 "Vapor Bus International" 478 "OceanSat BV" 477 "OilQuick AB" 476 "Hummingbird Marine Electronics" 475 "GME" 474 "Persen Technologies Inc." 473 "Boss Industries, Inc." 472 "Tenneco Inc." 471 "Sea Cross Marine AB" 628 "Falck Schmidt Defence Systems" 627 "Radio Ocean" 626 "AVL DiTEST GmbH" 625 "Global MRV Inc." 624 "Blackbox Machine Control Pty Ltd" 623 "Xirgo Technologies" 622 "Floyd Bell Inc" 621 "Hagie Manufacturing Company" 620 "Sevcon Ltd." 619 "Right Weigh Load Scales" 618 "Evrard SA" 617 "Zero Emission Vehicles" 616 "SMART-TEC s.r.o." 615 "Networkfleet, Verizon Telematics" 614 "ARLT Technologies GmbH" 613 "HKS Co., Ltd." 612 "Samwon IT" 611 "Esterline" 610 "Trail Tech" 609 "Walvoil S.p.A." 608 "Gale Banks Engineering" 607 "Knappco/Civacon" 606 "Intellian Technologies" 605 "Aventics GmbH" 604 "Indexator Rototilt Systems AB" 603 "Kereval" 602 "Nomad Digital Ltd." 601 "Navitas Systems" 600 "Aquatic AV" 599 "Spudnik Equipment Co, LLC" 598 "ABB Turbo Systems Ltd" 597 "Hydac Filter Systems GmbH" 596 "Brunelco Electronic Innovators B.V." 595 "CustomWare" 594 "Kongsberg Automotive" 593 "Sensata Technologies" 592 "tecsis GmbH" 591 "United States Coast Guard" 590 "ARGO-HYTOS GMBH" 589 "MICO, Inc." 588 "Vignal Systems" 587 "JCA Electronics" 586 "Suzuki Motor Corp" 585 "Industrial Electronic Controls" 584 "CarMedialab GmbH" 583 "Yachtcontrol" 582 "Innovative Software Engineering" 581 "Väderstad - Verken AB" 580 "San Jose Technology, Inc." 579 "KVH Industries, Inc." 578 "advanSea" 577 "Denchi Power Ltd  (formerly ABSL Power Solutions Limited)" 576 "Vectia" 575 "Lytx" 574 "Vishay Precision Group" 573 "Orolia Ltd" 572 "Fasse Valves" 571 "Marinecraft Co., Ltd." 570 "frenzel + berg electronic GmbH & Co. KG" 569 "LORD MicroStrain Sensing Systems" 568 "Makersan Ltd. Co." 567 "Lithiumstart LLC" 566 "Geode Technology, Inc." 565 "Micro-Trak Systems, Inc." 564 "Auto Power Electronic" 563 "LOHR Sistemas Eletronicos LTDA" 562 "Bombardier Transportation GmbH" 561 "b-plus GmbH" 560 "Iowa State University, Agricultural and Biosystems Engineering" 559 "Four Peaks Navigation" 558 "Davis Instruments Corp." 557 "Rockson Automation GmbH" 556 "Doosan Infracore Norway" 555 "Sasaki Corporation" 554 "iris-GmbH infrared & intelligent sensors" 553 "KIB Electronics" 552 "Matsuyama Plow Mfg Co, Ltd" 551 "Wexler CSD Ltd." 550 "SUN-A Corporation" 549 "ROAD Deutschland GmbH" 548 "TM4 Inc." 547 "Thomson Linear LLC" 546 "Maruyama Mfg Co, Inc." 545 "GS Hydraulics" 544 "Au Group Electronics" 543 "BAUER Maschinen GmbH" 542 "Dinamica Generale s.p.a." 541 "Total Fire Systems, Inc." 540 "Dinex A/S" 539 "Mobileview" 538 "Crop Ventures, Inc." 537 "Schrader Electronics Ltd." 536 "SSI Technologies" 535 "MOTORPAL, a.s." 534 "Webasto Thermo & Comfort SE" 533 "Doran Manufacturing, LLC" 532 "Onwa Marine Electronics Co Ltd." 531 "Genge & Thoma AG" 530 "NMEA" 529 "National Instruments Korea" 528 "Hoganas AB, Electric Drive Systems" 527 "GKN Walterscheid GmbH" 526 "LOFA Industries, Inc" 525 "Rust Sales INC" 470 "SI-TEX Marine Electronics" 469 "RA Consulting GmbH" 468 "Tyco Fire Protection Products" 467 "Lely Industries N.V." 466 "Veethree Electronics and Marine LLC" 465 "Ashcroft Inc" 464 "Leach International Corporation" 463 "PROBOTIQ" 462 "IHI Shibaura Machinery Corporation" 461 "HAWE Hydraulik SE" 460 "San Giorgio S.E.I.N." 459 "Alltek Marine Electronics Corp" 458 "Control Solutions, Inc." 457 "RUSELPROM-ElectricDrive Ltd" 456 "General Kinetics" 455 "ADZ NAGANO GmbH" 454 "NGK Spark Plug Co. Ltd" 453 "Cooper Bussmann" 452 "WIKA Alexander Wiegand SE & Co. KG" 451 "Parker Hannifin Corp" 450 "Dycor Technologies Ltd." 449 "Polaris Industries Inc" 448 "Stanadyne Corporation, Electronics Systems" 447 "Great Plains Mfg." 446 "CertTech, L.L.C." 445 "KAT MECHATRONIC, Electronic Product Division" 444 "ITT Power Solutions" 443 "SignalQuest, Inc." 442 "Horsch Maschinen GmbH" 441 "PTG Reifendruckregelsysteme GmbH" 440 "Cummins Power Generation" 439 "Hyundai Heavy Industries" 438 "Comar Systems Ltd" 437 "Digital Yacht Limited" 436 "Kinze Manufacturing" 435 "Zunhammer GmbH" 434 "Stored Energy Systems" 433 "Rowe Electronics" 432 "S&A Systems, Inc." 431 "Tohatsu Corporation" 430 "Auteq Telematica S.A." 429 "Rota Engineering Ltd." 425 "Methode Electronics Inc, MDI" 424 "Odyne LLC" 423 "BSM Wireless, Inc." 422 "True Heading AB" 421 "Vertex Standard Co, Ltd" 420 "Vermeer Corporation, ACS Group" 419 "Fusion Electronics Ltd" 418 "Intellistick Inc" 417 "KZValve" 416 "Kubota Corporation" 415 "Valid Manufacturing Ltd." 414 "Cattron Group International" 413 "Datapross Nijbroek bv" 412 "WebTech Wireless Inc." 411 "Hy-Drive Technologies Ltd." 410 "COBO S.p.A. Divisione 3B6" 409 "Transfluid S.r.L." 408 "Corvus Energy Ltd." 407 "Comtech Mobile Datacom" 406 "Vecima Networks Inc." 405 "Wema System AS" 404 "Com Nav Marine Ltd" 403 "Trackwell ADS, Inc." 402 "Simma Software, Inc." 401 "Torqeedo GmbH" 400 "Livorsi Marine" 399 "ISEKI & Co., Ltd." 398 "Hilite International" 397 "Sanyo-kiki Co Ltd." 396 "Beyond Measure" 395 "GENTEC S.R.L." 394 "Capi 2 Nederland BV" 393 "Harvest Tec, Inc" 392 "Tianyuan Technology Co Ltd." 391 "Electronic Design for Industry, Inc" 390 "Partech Inc." 389 "Benchmark Electronics, Minnesota Division" 388 "Innomatix, LLC" 387 "Orscheln Products, LLC" 386 "JLG Automation BVBA" 385 "Johnson Outdoor Marine Electronics" 384 "Camano Light" 383 "MCL Industries" 382 "National Agriculture and Food Research Organization" 381 "B & G" 380 "Suntech International Ltd." 379 "Yamabiko Corporation" 378 "Glendinning Marine Products" 377 "ifm electronic gmbh" 376 "Quake Global" 375 "Williams Controls Inc." 374 "Northern Lights, Inc." 373 "Electronic Design Inc." 372 "Delphi" 371 "Heinzmann GmbH & Co. KG" 370 "Rolls-Royce Marine AS" 369 "Power Torque Engineering Ltd" 368 "HANSENHOF_electronic" 367 "Fliegl Agrartechnik" 366 "Viewnyx Corp." 365 "Digi-Star, LLC" 364 "OEM Controls Inc." 363 "BEI Duncan" 362 "Poettinger Landtechnik GmbH (formerly Alois Poettinger Maschinenfabrik GmbH)" 361 "InMach" 360 "HJS Emission Technology GmbH & Co KG   (formerly HJS Fahrzeugtechnik GmbH & Co KG)" 359 "Ludwig Bergmann GmbH" 358 "Victron Energy BV" 357 "Hardi International A/S" 356 "Fischer Panda Generators, Inc" 355 "Mastervolt International B.V." 354 "Junkkari OY" 353 "Hegemon Electronics, Inc." 352 "SAME DEUTZ-FAHR GROUP S.p.A." 351 "Thrane & Thrane" 350 "Noris Marine Systems GmbH & Co KG" 349 "Suonentieto" 348 "Amazonen Werke H. Dreyer" 347 "Honeywell" 346 "Control Solutions" 345 "Korean Maritime University" 344 "Parvus Corporation" 343 "Baumer Group" 342 "THOMAS MAGNETE GmbH" 341 "Boning GmbH & Co" 340 "Continental AG" 339 "Competence Center ISOBUS e.V." 338 "GRAF-SYTECO" 337 "Carraro S.p.A." 336 "APE s.r.o." 335 "Evo Electric Ltd" 334 "Takata-Petri AG" 333 "Hadley Products Corporation" 332 "HWH Corporation" 331 "Horton, Inc." 330 "Kidde Aerospace and Defense" 329 "Deif A/S" 328 "Qwerty Electronik AB" 327 "Sonceboz SA" 326 "Akron Brass Company" 325 "ASM Automation Sensorik Messtechnik GmbH" 324 "Snap-on Diagnostics" 323 "Mobileye Vision Technologies Ltd." 322 "MICHENKA s.r.o." 321 "Ultra Electronics, Electrics" 320 "Miedema Landbouwwerktuigenfabriek B.V." 319 "Cadec Global" 318 "SAT Plan" 317 "Navtronics Bvba" 263 "IMMI" 262 "HydraForce, Inc" 261 "Red Dot Corporation" 260 "Reichhardt GmbH Steuerungstechnik" 259 "Jetter AG" 258 "ARAG" 257 "Honda Motor Co., Ltd" 256 "Tyco Electronics AMP" 255 "MEAS France" 254 "GE Sensing" 253 "Mobile Control Systems" 252 "Sensor-Technik Wiedemann GmbH" 251 "German Agricultural Society, Test Center (DLG)" 250 "Kuhn Group" 249 "Schaltbau GmbH" 248 "Cooper Standard Automotive Active Systems Group" 247 "ePULSE" 246 "Class 1, Inc" 245 "Capstan Ag Systems, Inc." 244 "Techno-Matic" 243 "eRide, Inc." 242 "Kokusandenki Co. Ltd" 241 "Schneider Automation SAS" 240 "Vanair Mfg" 239 "May & Scofield Ltd" 238 "ZF Friedrichshafen AG" 237 "Agtron Enterprises Inc" 236 "NORAC Systems International Inc" 235 "SailorMade Marine Telemetry - Tetra Technology Ltd." 234 "Mondial electronic GmbH" 233 "Yacht Monitoring Solutions Inc." 232 "TSD Integrated Controls" 231 "Topcon Positioning Systems, Inc." 230 "Saucon Technologies" 229 "Garmin International Inc." 228 "Unused (formerly ZF Marine Electronics)" 227 "Lykketronic A/S" 226 "Monaco Coach Corporation" 225 "SKF" 224 "EMMI Network, S.L." 223 "Vaueo Retarder Co., Ltd." 222 "Generac Power Systems, Inc." 221 "SiE" 220 "Beede Electrical Instrument Company, Inc" 219 "Cat OEM Solutions" 218 "Gits Manufacturing Company" 217 "RM Michaelides Software & Elektronik GmbH" 216 "Paneltronics Inc." 215 "Aetna Engineering/Fireboy-Xintex" 214 "MC elettronica Srl" 164 "MTU Friedrichshafen GmbH (formerly DaimlerChrysler Off-Highway)" 163 "BRP Inc." 162 "Axiomatic Technologies" 161 "Offshore Systems (UK) Ltd" 160 "Nido" 159 "NTech Industries Inc" 158 "Firestone Industrial Products Company" 157 "ISSPRO Inc." 156 "ITT Industries - Cannon" 155 "Vetronix Corporation" 154 "Westerbeke Corporation" 153 "Woodward, Industrial Controls Division" 152 "elobau GmbH & Co. KG" 151 "Raven Industries, Inc." 150 "Fleetguard" 149 "Holset" 148 "Blue Water Data, Inc." 147 "Nautibus electronic GmbH" 146 "Maxima Technologies" 145 "MurCal Controls" 144 "Mercury Marine" 143 "W. Gmeiner GmbH & Co." 142 "TRW Automotive (Commercial Steering Systems)" 141 "Thales Navigation Ltd." 140 "Lowrance Electronics, Inc." 139 "Caterpillar Trimble Control Technologies (CTCT), LLC" 138 "Georg Fritzmeier GmbH & Co. KG" 137 "Maretron" 136 "Komatsu Ltd" 135 "Airmar Technology Corporation" 134 "Iris Technology Ltd" 133 "Bucher Schoerling GmbH" 132 "Mulag-Fahrzeugwerk" 131 "ITT Industries" 130 "Nido - Universal Machines B.V." 129 "OMNEX Control Systems Inc." 128 "Gerhard Duecker GmbH & Co. KG" 127 "Holland USA" 126 "Driver Tech" 125 "Nevada Automotive Test Center" 124 "Hydac Electronic" 123 "Basler Electric" 122 "FG Wilson (Engineering) Limited" 121 "HED (Hydro Electronic Devices, Inc.)" 120 "RDS Technology Ltd" 119 "IntegriNautics  " 118 "Intron GmbH" 117 "HUSCO International" 116 "BEELINE Technologies" 115 "NACCO Materials Handling Group, Inc." 114 "EControls, Inc." 113 "Stress-Tek, Inc." 112 "MECALAC" 111 "Maschinenfabrik Bernard Krone GmbH" 110 "EPIQ Sensor-Nite" 109 "TeeJet Technologies Denmark (formerly LH Technologies ApS)" 108 "WTK-Elecktronik GmbH" 107 "Grimme Landmaschinen GmbH & Co. KG" 106 "BAE Systems Controls, Inc." 105 "Kiepe Elektrik GmbH & Co. KG" 104 "CLAAS KGaA mbH (formerly CLAAS Selbstfahrende Erntemaschinen GmbH)" 103 "CLAAS E-Systems KGaA mbH & Co. KG (formerly CLAAS Agrosystems GmbH & Co. KG)" 102 "AGCO (formerly AGCO GmbH & Co.)" 101 "Sensoria" 100 "VDO Technik AG" 99 "International Transmissions Ltd (ITL)" 98 "Mueller-Elektronik GmbH & Co" 97 "Ag Leader Technology, Inc." 96 "Mech@tronic IT GmbH" 95 "Pacific Insight Electronics Corp." 94 "CNH Industrial N.V. (formerly CNH Global N.V.)" 93 "Perkins Engines Company Ltd." 92 "Ag-Chem Equipment Co., Inc." 91 "BSG Bodensee Steuergeraete GmbH" 90 "Knorr-Bremse SfN GmbH" 89 "Kverneland Group, Electronics Division" 88 "Satloc Precision GPS" 87 "J.C. Bamford Excavators Ltd (JCB)" 86 "C. E. Niehoff & Company" 85 "Kohler Co" 84 "New Holland UK Limited" 83 "Bendix VORAD Technologies (formerly Eaton VORAD Technologies)" 82 "Bobcat/Ingersoll-Rand (formerly Melroe/Ingersoll-Rand)" 81 "Fire Research Corp." 80 "Twin Disc, Inc." 79 "Daimler Benz AG - Engine Division (PBM)" 78 "Frank W. Murphy Manufacturing, Inc" 77 "Deere Power Systems Group" 76 "unused (formerly Deere & Co, Construction Division)" 75 "Deere & Co, Agricultural Division" 74 "Eaton Axle-Brake Division" 73 "LeTourneau, Inc." 72 "Sisu Corporation" 71 "Vansco Electronics Ltd." 70 "Flex-coil Limited" 69 "Trimble Navigation" 316 "ITT Flow Control" 315 "Icom Incorporated" 314 "CSM GmbH" 313 "Ilmor Engineering, Inc." 312 "Lectronix, Inc." 311 "Patrick Power Products" 310 "TECNORD srl" 309 "Krauss-Maffei Wegmann GmbH & Co. KG" 308 "Cyntrx" 307 "MAS Technologies" 306 "Sleipner Motor AB" 305 "NovAtel Inc" 304 "EmpirBus AB" 303 "CTS Corporation" 302 "Nissin Kogyo Co., LTD" 301 "Parker Hannifin (UK) Ltd FDE group" 300 "Systron Donner Automotive" 299 "Rauch" 298 "Holley Performance" 297 "Zonar Systems Inc" 296 "micro dynamics GmbH" 295 "BEP Marine" 294 "Grayhill Inc." 293 "Spyder Controls Corp." 292 "IKUSI - Angel Iglesias S.A." 291 "Groeneveld Transport Efficiency BV" 290 "Kuebler GmbH" 289 "Watlow" 288 "Mitsubishi FUSO Truck & Bus Corp." 287 "NTech Industries, Inc" 286 "Coelmo srl" 285 "Sea Recovery Corp" 284 "Mobile Tech Chile" 283 "CWF Hamilton & Co Ltd" 282 "Medallion Instrumentation Systems" 281 "Precision Governors LLC" 280 "Leica Geosystems Pty Ltd" 279 "Geometris LP" 278 "Takata Electronics" 277 "LHP Telematics" 276 "Aqua-Hot Heating Systems" 275 "Navico Egersund AS" 274 "LTW Technology Co., LTD" 273 "Active Research Limited" 272 "Gross Mechanical Laboratories, Inc" 271 "Cole Hersee" 270 "Tennant" 269 "Saft America Inc.,  Space & Defense Division" 268 "Accurate Technologies" 267 "Red Lion Controls, Inc" 266 "International Thermal Research Ltd" 265 "MTS Sensor Technologie GmbH" 264 "Autolync" 213 "CNH Belgium N.V." 212 "Sure Power Industries, Inc" 211 "DNA Group" 210 "Iteris, Inc." 209 "Bell Equip. Co. SA (PTY) LTD" 208 "Drew Technologies, Inc" 207 "Otto Engineering" 206 "port GmbH" 205 "SmarTire Systems Inc" 204 "The Morey Corporation" 203 "MILtronik GmbH" 202 "Curtis Instruments, Inc" 201 "Disenos y Tecnologia S.A." 200 "MGM Brakes" 199 "Actia Corp" 198 "Mystic Valley Communications" 197 "Mechron Power Systems" 196 "LEMKEN GmbH & Co KG" 195 "General Engine Products" 194 "TriMark Corporation" 193 "Jeppesen Marine" 192 "Floscan" 191 "XRS Corporation (formerly XATA Corporation)" 190 "Hella KGaA Hueck & Co" 189 "QUALCOMM" 188 "EMP Corp" 187 "Air-Weigh" 186 "Altronic, Inc" 185 "Beede Electrical Instrument Company" 184 "EIA Electronics" 183 "KDS Controls, Inc" 182 "Vehicle Systems Engineering B.V." 181 "Coretronics, Inc." 180 "Smart Power Systems" 179 "TeeJet Technologies Springfield (formerly Midwest Technologies Illinois, LLC)" 178 "Continental Automotive GmbH (formerly Siemens VDO Automotive AG)" 177 "Diagnostic Systems Associates" 176 "Moritz Aerospace" 175 "Veris Technologies, Inc." 174 "AB Volvo Penta" 173 "Ryeso, Inc." 172 "Yanmar Co., Ltd. (formerly Yanmar Marine USA)" 171 "Wachendorff Elektronik GmbH & Co. KG" 170 "Computronics Corporation Ltd." 169 "Marlin Technologies Inc." 168 "Xantrex" 167 "JLG Industries Inc" 166 "John Deere Electronic Solutions (formerly Phoenix International)" 165 "CPAC Systems AB" 68 "Scania" 67 "John Deere Coffeyville Works (formerly Funk Manufacturing Company)" 66 "John Deere Construction Equipment Division" 65 "MAN Nutzfahrzeuge AG" 64 "Unused (formerly SpectraPrecision Laserplane, then SpectraPhysics)" 63 "ZF Industries Inc." 62 "Wabco" 61 "Volvo Truck Corp." 60 "Volvo Trucks North America Inc." 59 "VES Inc." 58 "SPX Corporation, OTC Div" 57 "Danfoss  (formerly Sauer Sundstrand Co, then Sauer-Danfoss Co)" 56 "SAIC" 55 "Ryder System Inc." 54 "Meritor Wabco" 53 "Continental Automotive Systems US, Inc. (formerly Rockwell Land Transportation)" 52 "Meritor Automotive, Inc. (formerly Rockwell Automotive)" 51 "Robert Bosch GmbH" 50 "Robert Bosch Corp" 49 "RE America Inc." 48 "Pollak Alphabet" 47 "Phillips Semiconductor" 46 "Noregon Systems, Inc  (formerly Parasoft Computing Solutions)" 45 "PACCAR" 44 "Nippondenso Co. Ltd." 43 "International Truck and Engine Corporation - Vehicle Electronics (formerly Navistar Intl Trans Corp.)" 42 "International Truck and Engine Corporation - Engine Electronics  (formerly Navistar Intl Trans Co., Engine Electronics)" 41 "Motorola Inc." 40 "Motorola AIEG Inc." 39 "Microfirm Inc." 38 "Micro Processor Systems Inc." 37 "Mack Trucks Inc." 36 "Lucas Ind." 35 "Kenworth Truck Co." 34 "Kelsey Hayes Co." 33 "John Deere" 32 "Jacobs Vehicle Systems" 31 "J Pollak Corp" 30 "Isuzu Motors Ltd" 29 "Hino Motors Ltd." 28 "Grote Ind. Inc." 27 "GMC" 26 "General Motors Corp, Service Technology Grp" 25 "Daimler Trucks North America LLC (formerly Freightliner LLC)" 24 "Ford Motor Co., Vehicle Controls" 23 "Ford Motor Co., Heavy Truck" 22 "Ford Motor Co., Electronic Concepts & Systems" 21 "Echlin Inc., Midland Brake Inc." 20 "Eaton Ltd" 19 "Eaton Corp. Trucking Info Services" 18 "Eaton Corp, Transmission Div." 17 "Eaton Corp, Corp Res & Dev" 16 "Eaton Corp" 15 "DICKEY-john Corporation" 14 "Detroit Diesel Corporation" 13 "Delco Electronics" 12 "Deere & Company, Precision Farming" 11 "Dearborn Group Inc." 10 "Cummins Inc (formerly Cummins Engine Co)" 9 "Chrysler Corp." 8 "Caterpillar Inc." 7 "Case Corp." 6 "Berifors Electronics AB" 5 "AMP Inc." 4 "Ametek-Dixson" 3 "Ametek, US Gauge Division" 2 "Allison Transmission, Inc." 1 "Bendix Commercial Vehicle Systems LLC (formerly Allied Signal Inc.)" 0 "Reserved" ;
VAL_ 2565799435 IndustryGroup 7 "Reserved for SAE" 5 "IndustrialProcessCtrlStationary" 4 "Marine" 3 "Construction" 2 "Agricultural and Forestry" 1 "On-Highway" 0 "Global" ;
VAL_ 2565799435 VehicleSystem 127 "Not Available" 0 "Non-specific System" ;
VAL_ 2565799435 VehicleSystem5 0 "Ind. Process Control Stationary" 127 "Not Available" ;
VAL_ 2565799435 VehicleSystem4 0 "Non-specific System" 127 "Not Available" 10 "System Tools" 20 "Safety Systems" 25 "Inter/Intranetwork Device" 30 "Electrical Distribution" 40 "Steering and Control Surfaces" 50 "Propulsion" 60 "Navigation" 70 "Communications" 80 "Instrumentation/General Systems (deprecate)" 90 "Internal Environment" 100 "Deck, Cargo and Fishing Equipment" 35 "Electrical Generation" 75 "Sensor Communication Interface" 85 "External Environment" 120 "Display" 125 "Entertainment" ;
VAL_ 2565799435 VehicleSystem3 0 "Non-specific System" 127 "Not Available" 1 "Skid Steer Loader" 2 "Articulated Dump Truck" 3 "Backhoe" 4 "Crawler" 5 "Excavator" 6 "Forklift" 7 "Four Wheel Drive Loader" 8 "Grader" ;
VAL_ 2565799435 VehicleSystem2 0 "Non-specific System" 127 "Not Available" 1 "Tractor" 2 "Tillage" 3 "Secondary Tillage" 4 "Planters/Seeders" 5 "Fertilizers" 6 "Sprayers" 7 "Harvesters" 8 "Root Harvesters" 9 "Forage" 10 "Irrigation" 11 "Transport/Trailer" 12 "Farm Yard Operations" 13 "Powered Auxiliary Device" 14 "Special Crops" 15 "Earth Work" 16 "Skidder" 17 "Sensor Systems" 19 "Timber Harvesters" 20 "Forwarders" 21 "Timber loaders" 22 "Timber Processing Machines" 23 "Mulchers" 24 "Utility Vehicles" 25 "Slurry Applicators" ;
VAL_ 2565799435 VehicleSystem1 0 "Non-specific System" 127 "Not Available" 1 "Tractor" 2 "Trailer" ;
VAL_ 2565799435 Function 43 "Transmission Display" 44 "Exhaust Emission Control" 45 "Vehicle Dynamic Stability Control" 46 "Oil Sensor Unit" 47 "Information System Controller" 48 "Ramp Control" 49 "Clutch/Converter Control" 50 "Auxiliary Heater" 51 "Forward-Looking Collision Warning System" 52 "Chassis Controller" 53 "Alternator/Charging System" 54 "Communications Unit, Cellular" 55 "Communications Unit, Satellite" 56 "Communications Unit, Radio" 57 "Steering Column Unit" 58 "Fan Drive Control" 59 "Starter" 60 "Cab Display" 61 "File Server/Printer" 62 "On-Board Diagnostic Unit" 63 "Engine Valve Controller" 64 "Endurance Braking" 65 "Gas Flow Measurement" 66 "I/O Controller" 67 "Electrical System Controller" 68 "Aftertreatment system gas measurement" 69 "Engine Emission Aftertreatement System" 70 "Auxiliary Regeneration Device" 71 "Transfer Case Control" 72 "Coolant Valve Controller" 73 "Rollover Detection Control" 74 "Lubrication System" 75 "Supplemental Fan" 76 "Temperature Sensor" 77 "Fuel Properties Sensor" 78 "Fire Suppression System" 79 "Power Systems Manager" 80 "Electric Powertrain" 81 "Hydraulic Powertrain" 82 "File Server" 83 "Printer" 84 "Start Aid Device" 85 "Engine Injection Control Module" 86 "Reserved" 87 "Reserved" 88 "Reserved" 89 "Reserved" 90 "Reserved" 91 "Reserved" 92 "Reserved" 93 "Reserved" 94 "Reserved" 95 "Reserved" 96 "Reserved" 97 "Reserved" 98 "Reserved" 99 "Reserved" 100 "Reserved" 0 "Engine" 1 "Auxiliary Power Unit (APU)" 2 "Electric Propulsion Control" 3 "Transmission" 4 "Battery Pack Monitor" 5 "Shift Control/Console" 6 "Power TakeOff - (Main or Rear)" 7 "Axle - Steering" 8 "Axle - Drive" 9 "Brakes - System Controller" 10 "Brakes - Steer Axle" 11 "Brakes - Drive Axle" 12 "Retarder - Engine" 13 "Retarder - Driveline" 14 "Cruise Control" 15 "Fuel System" 16 "Steering Controller" 17 "Suspension - Steer Axle" 18 "Suspension - Drive Axle" 19 "Instrument Cluster" 20 "Trip Recorder" 21 "Cab Climate Control" 22 "Aerodynamic Control" 23 "Vehicle Navigation" 24 "Vehicle Security" 25 "Network Interconnect ECU" 26 "Body Controller" 27 "Power TakeOff (Secondary or Front)" 28 "Off Vehicle Gateway" 29 "Virtual Terminal (in cab)" 30 "Management Computer" 31 "Propulsion Battery Charger" 32 "Headway Controller" 33 "System Monitor" 34 "Hydraulic Pump Controller" 35 "Suspension - System Controller" 36 "Pneumatic - System Controller" 37 "Cab Controller" 38 "Tire Pressure Control" 39 "Ignition Control Module" 40 "Seat Control" 41 "Lighting - Operator Controls" 42 "Water Pump Control" 101 "Reserved" 102 "Reserved" 103 "Reserved" 104 "Reserved" 105 "Reserved" 106 "Reserved" 107 "Reserved" 108 "Reserved" 109 "Reserved" 110 "Reserved" 111 "Reserved" 112 "Reserved" 113 "Reserved" 114 "Reserved" 115 "Reserved" 116 "Reserved" 117 "Reserved" 118 "Reserved" 119 "Reserved" 120 "Reserved" 121 "Reserved" 122 "Reserved" 123 "Reserved" 124 "Reserved" 125 "Reserved" 126 "Reserved" 127 "Reserved" 128 "Non Virtual Terminal Display" 129 "Operator Controls" 130 "Task Controller" 131 "Position Control" 132 "Machine Control" 133 "Foreign Object Detection" 134 "Tractor ECU" 135 "Sequence Control Master" 136 "Product Dosing" 137 "Product Treatment" 138 "Reserved" 139 "Data Logger" 140 "Decision Support" 141 "Lighting Controller" 142 "TIM Server" 255 "Not Available" ;
VAL_ 2565799435 ManufacturerCode 1863 "Thomas G. Faria Co." 1862 "Sanshin" 1861 "Vector North America " 1860 "MMP" 1859 "Kvasar AB" 1858 "Litton" 1857 "Simrad" 1856 "Trimble" 1855 "Furuno USA" 1854 "Northstar Technologies" 1853 "Japan Radio Co" 1852 "Navionics" 1851 "RayMarine" 1850 "Teleflex" 786 "Johnson Matthey Battery Systems" 785 "Fischer Panda GmbH" 784 "CM Automotive Systems, Inc." 783 "Loup Electronics Inc." 782 "AVR bvba" 781 "Poly-Planar LLC" 780 "AVID Technology Ltd" 779 "RLC Electronic Systems" 778 "Seakeeper Inc." 777 "Ocean Signal Ltd" 776 "HMI Systems LLC" 775 "ZIEHL-ABEGG Automotive GmbH" 774 "Taisho Corporation" 773 "Clarion Corporation of America" 772 "Blink Marine" 771 "Shaw Development, LLC" 770 "MONOSEM" 769 "Trombetta" 768 "Flores Automation, LLC" 767 "Alliance Wireless Technologies Inc." 766 "Epec Oy" 765 "GIGAVAC" 764 "Bednar FMT s.r.o." 763 "AT-Systems BVBA" 762 "ROJ s.r.l." 761 "MITA OLEODINAMICA S.p.A." 760 "Bernecker + Rainer Industrie Elektronik GmbH" 759 "Hydro-Gear" 758 "Banner Engineering Corp." 757 "IMPCO Technologies" 756 "Maschio Gaspardo S.P.A." 755 "Firefly Integrations" 754 "Parker Hannifin Corp., Automation Group" 753 "AIROD Technologies" 752 "Deep Sea Electronics Plc" 751 "Pacific Track" 750 "Joskin SA" 749 "Chart Inc." 748 "ISOTTA" 747 "Agratronix" 746 "SureFire Ag Systems, Inc." 745 "Cidra Corporate Services Inc." 744 "Woosung Engineering Co., Ltd." 743 "Daemyung Elevator Co., Ltd." 742 "EROAD" 741 "Carling Technologies" 740 "e-Traction" 739 "LXNAV d.o.o." 738 "Blue Ink Technologies" 737 "Balluff GmbH" 736 "Terex Aerial Work Platforms - Genie" 735 "AEM Performance Electronics" 734 "REAPsystems" 733 "Intendia S.L." 732 "Gefran S.p.A." 731 "Modine Manufacturing Company" 730 "BERTHOUD AGRICOLE" 729 "Liebherr" 728 "Streumaster / Panien" 727 "Dhoot Transmission Pvt Ltd." 726 "MIDORI PRECISIONS" 725 "Hitachi Construction Machinery Co., Ltd." 724 "Electronic Applications, Inc." 723 "Jabil Inc." 722 "Contelec AG" 721 "Hypro" 720 "WITZ Corporation" 719 "Cojali S. L." 718 "Micronet Inc" 717 "Yacht Devices Ltd" 716 "Eaton Control & Power Conversion Division (CPCD)" 715 "Autonnic Research Ltd" 714 "Kobashi Kogyo Co., Ltd." 713 "US Hybrid Corporation" 712 "LOR Manufacturing Company Inc." 711 "DAS Co., LTD" 710 "Greentronics Ltd." 709 "Marquardt GmbH" 708 "Lars Thrane A/S" 707 "Rochester Gauges Inc" 706 "Shanghai Diesel Engine Corporation Limited" 705 "SVAB Hydraulik AB" 704 "JL Audio, Inc." 703 "Hydro Tab Marine Engineering" 702 "Weichai Power Co., Ltd." 701 "BigRoad Inc." 700 "K-Tec Earthmovers Inc." 699 "Harman International Industries" 698 "Scorpion Technologies Ltd." 697 "Ålö AB" 696 "DRS Network & Imaging Systems, LLC (DRS Technologies)" 695 "Weldon Technologies" 694 "GasTOPS Ltd." 693 "Agility Fuel Solutions (formerly Agility Fuel Systems)" 692 "Tanhay Corporation" 691 "Digitroll Agricultural Electronics" 690 "LINAK A/S" 689 "Aarcomm Systems Inc" 688 "Rockford Corp" 687 "Flight Systems, Inc." 686 "Taigene Electric Machinery Corp." 685 "ANEDO Ltd." 684 "KEB" 683 "Fosen Elektro" 682 "Eckelmann AG" 681 "BEDIA Motorentechnik GmbH & Co. KG" 680 "AMVAC Chemical Corporation" 679 "Cimco Marine AB" 678 "KeepTruckin, Inc." 677 "DSA Daten- und Systemtechnik GmbH" 676 "Danfoss IXA A/S" 675 "Kawasaki Motors Corp., USA" 674 "Yara International ASA" 673 "Caruelle Nicolas" 672 "OPTIMA Concept" 671 "Innovative Controls Inc." 670 "STEMCO LP" 669 "Quantum Fuel Systems Technologies Worldwide, Inc" 668 "MacDon Industries Ltd." 667 "Bartec" 666 "Schaeffler Technologies AG & Co., KG" 665 "Gebr. Bode GmbH & Co. KG" 664 "Level Developments Ltd" 663 "Delta Systems, Inc" 662 "Kissling Elektrotechnik GmbH" 661 "SPAL Automotive S.r.l." 660 "Auto-Gaz Centrum" 659 "Data Panel Corp." 658 "Shenzhen Jiuzhou Himunication Technology Co., Ltd" 657 "Terzo Power Systems" 656 "PRO SOLUS do Brasil" 655 "Genge & Thoma AG" 654 "Kohler Power Systems, Detroit Engine Development Center (DEDC)" 653 "AEV, spol. s r. o." 652 "MicroControl GmbH & Co. KG" 651 "Takakita Co, Ltd." 650 "Seiko Epson Corp." 649 "Control-Q BV" 648 "OJSC Ekran" 647 "Siloking" 646 "Veenhuis Machines BV" 645 "esd electronic system design gmbh" 644 "KUS USA" 643 "Bogballe A/S" 642 "Moog / Aspen Motion Technologies" 641 "Diverse Yacht Services" 640 "Power Solutions International" 639 "Startec s.r.l." 638 "KVH Industries, Inc." 637 "Bavaria Yachtbau GmbH" 636 "Divelbiss Corporation" 635 "Argo Tractors S.p.A." 634 "Rocky Research" 633 "TORC Robotics" 632 "Pepperl+Fuchs GmbH" 631 "Reltima" 630 "SmartDrive Systems Inc." 629 "Agri Info Design, Ltd." 524 "Vomax Instrumentation Pty. Ltd." 523 "Reggio Emilia Innovazione" 522 "Nebraska Tractor Test Laboratory" 521 "Clever Devices Ltd." 520 "Trapeze" 519 "Peeters Landbouwmachines b.v." 518 "Transas USA Inc." 517 "Noland Engineering" 516 "AVAT Automation GmbH" 515 "GINAF Trucks Nederland B.V." 514 "DISTek Integration, Inc." 513 "FarmscanAg" 512 "Inpower LLC" 511 "Sulky" 510 "Marinesoft Co. Ltd" 509 "MOTORTECH GmbH" 508 "Transtech Innovations" 507 "ISOBUS Test Center" 506 "IHI STAR Machinery Corporation" 505 "Yetter Farm Equipment" 504 "Vesper Marine" 503 "Naviop S.R.L." 502 "Attwood Corporation" 501 "Agrotronix S.A." 500 "Oxbo International Corporation" 499 "LCJ Capteurs" 498 "Innovative Design Solutions, Inc." 497 "SENTRON Sistemas Embarcados" 496 "W. Gessmann GmbH" 495 "HOLMER Maschinenbau GmbH" 494 "Synerject" 493 "Watcheye" 492 "Inergy Automotive Systems" 491 "Penny and Giles Ltd" 490 "QuikQ" 489 "Appareo Systems, LLC" 488 "The Charles Machine Works, Inc." 487 "DSE Test Solutions A/S" 486 "Westport Innovations Inc." 485 "MATT automotive" 484 "Headsight Inc." 483 "Valeo" 482 "Tricon Electronics" 481 "Chetco Digital Instruments" 480 "EnerDel, Inc." 479 "Vapor Bus International" 478 "OceanSat BV" 477 "OilQuick AB" 476 "Hummingbird Marine Electronics" 475 "GME" 474 "Persen Technologies Inc." 473 "Boss Industries, Inc." 472 "Tenneco Inc." 471 "Sea Cross Marine AB" 628 "Falck Schmidt Defence Systems" 627 "Radio Ocean" 626 "AVL DiTEST GmbH" 625 "Global MRV Inc." 624 "Blackbox Machine Control Pty Ltd" 623 "Xirgo Technologies" 622 "Floyd Bell Inc" 621 "Hagie Manufacturing Company" 620 "Sevcon Ltd." 619 "Right Weigh Load Scales" 618 "Evrard SA" 617 "Zero Emission Vehicles" 616 "SMART-TEC s.r.o." 615 "Networkfleet, Verizon Telematics" 614 "ARLT Technologies GmbH" 613 "HKS Co., Ltd." 612 "Samwon IT" 611 "Esterline" 610 "Trail Tech" 609 "Walvoil S.p.A." 608 "Gale Banks Engineering" 607 "Knappco/Civacon" 606 "Intellian Technologies" 605 "Aventics GmbH" 604 "Indexator Rototilt Systems AB" 603 "Kereval" 602 "Nomad Digital Ltd." 601 "Navitas Systems" 600 "Aquatic AV" 599 "Spudnik Equipment Co, LLC" 598 "ABB Turbo Systems Ltd" 597 "Hydac Filter Systems GmbH" 596 "Brunelco Electronic Innovators B.V." 595 "CustomWare" 594 "Kongsberg Automotive" 593 "Sensata Technologies" 592 "tecsis GmbH" 591 "United States Coast Guard" 590 "ARGO-HYTOS GMBH" 589 "MICO, Inc." 588 "Vignal Systems" 587 "JCA Electronics" 586 "Suzuki Motor Corp" 585 "Industrial Electronic Controls" 584 "CarMedialab GmbH" 583 "Yachtcontrol" 582 "Innovative Software Engineering" 581 "Väderstad - Verken AB" 580 "San Jose Technology, Inc." 579 "KVH Industries, Inc." 578 "advanSea" 577 "Denchi Power Ltd  (formerly ABSL Power Solutions Limited)" 576 "Vectia" 575 "Lytx" 574 "Vishay Precision Group" 573 "Orolia Ltd" 572 "Fasse Valves" 571 "Marinecraft Co., Ltd." 570 "frenzel + berg electronic GmbH & Co. KG" 569 "LORD MicroStrain Sensing Systems" 568 "Makersan Ltd. Co." 567 "Lithiumstart LLC" 566 "Geode Technology, Inc." 565 "Micro-Trak Systems, Inc." 564 "Auto Power Electronic" 563 "LOHR Sistemas Eletronicos LTDA" 562 "Bombardier Transportation GmbH" 561 "b-plus GmbH" 560 "Iowa State University, Agricultural and Biosystems Engineering" 559 "Four Peaks Navigation" 558 "Davis Instruments Corp." 557 "Rockson Automation GmbH" 556 "Doosan Infracore Norway" 555 "Sasaki Corporation" 554 "iris-GmbH infrared & intelligent sensors" 553 "KIB Electronics" 552 "Matsuyama Plow Mfg Co, Ltd" 551 "Wexler CSD Ltd." 550 "SUN-A Corporation" 549 "ROAD Deutschland GmbH" 548 "TM4 Inc." 547 "Thomson Linear LLC" 546 "Maruyama Mfg Co, Inc." 545 "GS Hydraulics" 544 "Au Group Electronics" 543 "BAUER Maschinen GmbH" 542 "Dinamica Generale s.p.a." 541 "Total Fire Systems, Inc." 540 "Dinex A/S" 539 "Mobileview" 538 "Crop Ventures, Inc." 537 "Schrader Electronics Ltd." 536 "SSI Technologies" 535 "MOTORPAL, a.s." 534 "Webasto Thermo & Comfort SE" 533 "Doran Manufacturing, LLC" 532 "Onwa Marine Electronics Co Ltd." 531 "Genge & Thoma AG" 530 "NMEA" 529 "National Instruments Korea" 528 "Hoganas AB, Electric Drive Systems" 527 "GKN Walterscheid GmbH" 526 "LOFA Industries, Inc" 525 "Rust Sales INC" 470 "SI-TEX Marine Electronics" 469 "RA Consulting GmbH" 468 "Tyco Fire Protection Products" 467 "Lely Industries N.V." 466 "Veethree Electronics and Marine LLC" 465 "Ashcroft Inc" 464 "Leach International Corporation" 463 "PROBOTIQ" 462 "IHI Shibaura Machinery Corporation" 461 "HAWE Hydraulik SE" 460 "San Giorgio S.E.I.N." 459 "Alltek Marine Electronics Corp" 458 "Control Solutions, Inc." 457 "RUSELPROM-ElectricDrive Ltd" 456 "General Kinetics" 455 "ADZ NAGANO GmbH" 454 "NGK Spark Plug Co. Ltd" 453 "Cooper Bussmann" 452 "WIKA Alexander Wiegand SE & Co. KG" 451 "Parker Hannifin Corp" 450 "Dycor Technologies Ltd." 449 "Polaris Industries Inc" 448 "Stanadyne Corporation, Electronics Systems" 447 "Great Plains Mfg." 446 "CertTech, L.L.C." 445 "KAT MECHATRONIC, Electronic Product Division" 444 "ITT Power Solutions" 443 "SignalQuest, Inc." 442 "Horsch Maschinen GmbH" 441 "PTG Reifendruckregelsysteme GmbH" 440 "Cummins Power Generation" 439 "Hyundai Heavy Industries" 438 "Comar Systems Ltd" 437 "Digital Yacht Limited" 436 "Kinze Manufacturing" 435 "Zunhammer GmbH" 434 "Stored Energy Systems" 433 "Rowe Electronics" 432 "S&A Systems, Inc." 431 "Tohatsu Corporation" 430 "Auteq Telematica S.A." 429 "Rota Engineering Ltd." 425 "Methode Electronics Inc, MDI" 424 "Odyne LLC" 423 "BSM Wireless, Inc." 422 "True Heading AB" 421 "Vertex Standard Co, Ltd" 420 "Vermeer Corporation, ACS Group" 419 "Fusion Electronics Ltd" 418 "Intellistick Inc" 417 "KZValve" 416 "Kubota Corporation" 415 "Valid Manufacturing Ltd." 414 "Cattron Group International" 413 "Datapross Nijbroek bv" 412 "WebTech Wireless Inc." 411 "Hy-Drive Technologies Ltd." 410 "COBO S.p.A. Divisione 3B6" 409 "Transfluid S.r.L." 408 "Corvus Energy Ltd." 407 "Comtech Mobile Datacom" 406 "Vecima Networks Inc." 405 "Wema System AS" 404 "Com Nav Marine Ltd" 403 "Trackwell ADS, Inc." 402 "Simma Software, Inc." 401 "Torqeedo GmbH" 400 "Livorsi Marine" 399 "ISEKI & Co., Ltd." 398 "Hilite International" 397 "Sanyo-kiki Co Ltd." 396 "Beyond Measure" 395 "GENTEC S.R.L." 394 "Capi 2 Nederland BV" 393 "Harvest Tec, Inc" 392 "Tianyuan Technology Co Ltd." 391 "Electronic Design for Industry, Inc" 390 "Partech Inc." 389 "Benchmark Electronics, Minnesota Division" 388 "Innomatix, LLC" 387 "Orscheln Products, LLC" 386 "JLG Automation BVBA" 385 "Johnson Outdoor Marine Electronics" 384 "Camano Light" 383 "MCL Industries" 382 "National Agriculture and Food Research Organization" 381 "B & G" 380 "Suntech International Ltd." 379 "Yamabiko Corporation" 378 "Glendinning Marine Products" 377 "ifm electronic gmbh" 376 "Quake Global" 375 "Williams Controls Inc." 374 "Northern Lights, Inc." 373 "Electronic Design Inc." 372 "Delphi" 371 "Heinzmann GmbH & Co. KG" 370 "Rolls-Royce Marine AS" 369 "Power Torque Engineering Ltd" 368 "HANSENHOF_electronic" 367 "Fliegl Agrartechnik" 366 "Viewnyx Corp." 365 "Digi-Star, LLC" 364 "OEM Controls Inc." 363 "BEI Duncan" 362 "Poettinger Landtechnik GmbH (formerly Alois Poettinger Maschinenfabrik GmbH)" 361 "InMach" 360 "HJS Emission Technology GmbH & Co KG   (formerly HJS Fahrzeugtechnik GmbH & Co KG)" 359 "Ludwig Bergmann GmbH" 358 "Victron Energy BV" 357 "Hardi International A/S" 356 "Fischer Panda Generators, Inc" 355 "Mastervolt International B.V." 354 "Junkkari OY" 353 "Hegemon Electronics, Inc." 352 "SAME DEUTZ-FAHR GROUP S.p.A." 351 "Thrane & Thrane" 350 "Noris Marine Systems GmbH & Co KG" 349 "Suonentieto" 348 "Amazonen Werke H. Dreyer" 347 "Honeywell" 346 "Control Solutions" 345 "Korean Maritime University" 344 "Parvus Corporation" 343 "Baumer Group" 342 "THOMAS MAGNETE GmbH" 341 "Boning GmbH & Co" 340 "Continental AG" 339 "Competence Center ISOBUS e.V." 338 "GRAF-SYTECO" 337 "Carraro S.p.A." 336 "APE s.r.o." 335 "Evo Electric Ltd" 334 "Takata-Petri AG" 333 "Hadley Products Corporation" 332 "HWH Corporation" 331 "Horton, Inc." 330 "Kidde Aerospace and Defense" 329 "Deif A/S" 328 "Qwerty Electronik AB" 327 "Sonceboz SA" 326 "Akron Brass Company" 325 "ASM Automation Sensorik Messtechnik GmbH" 324 "Snap-on Diagnostics" 323 "Mobileye Vision Technologies Ltd." 322 "MICHENKA s.r.o." 321 "Ultra Electronics, Electrics" 320 "Miedema Landbouwwerktuigenfabriek B.V." 319 "Cadec Global" 318 "SAT Plan" 317 "Navtronics Bvba" 263 "IMMI" 262 "HydraForce, Inc" 261 "Red Dot Corporation" 260 "Reichhardt GmbH Steuerungstechnik" 259 "Jetter AG" 258 "ARAG" 257 "Honda Motor Co., Ltd" 256 "Tyco Electronics AMP" 255 "MEAS France" 254 "GE Sensing" 253 "Mobile Control Systems" 252 "Sensor-Technik Wiedemann GmbH" 251 "German Agricultural Society, Test Center (DLG)" 250 "Kuhn Group" 249 "Schaltbau GmbH" 248 "Cooper Standard Automotive Active Systems Group" 247 "ePULSE" 246 "Class 1, Inc" 245 "Capstan Ag Systems, Inc." 244 "Techno-Matic" 243 "eRide, Inc." 242 "Kokusandenki Co. Ltd" 241 "Schneider Automation SAS" 240 "Vanair Mfg" 239 "May & Scofield Ltd" 238 "ZF Friedrichshafen AG" 237 "Agtron Enterprises Inc" 236 "NORAC Systems International Inc" 235 "SailorMade Marine Telemetry - Tetra Technology Ltd." 234 "Mondial electronic GmbH" 233 "Yacht Monitoring Solutions Inc." 232 "TSD Integrated Controls" 231 "Topcon Positioning Systems, Inc." 230 "Saucon Technologies" 229 "Garmin International Inc." 228 "Unused (formerly ZF Marine Electronics)" 227 "Lykketronic A/S" 226 "Monaco Coach Corporation" 225 "SKF" 224 "EMMI Network, S.L." 223 "Vaueo Retarder Co., Ltd." 222 "Generac Power Systems, Inc." 221 "SiE" 220 "Beede Electrical Instrument Company, Inc" 219 "Cat OEM Solutions" 218 "Gits Manufacturing Company" 217 "RM Michaelides Software & Elektronik GmbH" 216 "Paneltronics Inc." 215 "Aetna Engineering/Fireboy-Xintex" 214 "MC elettronica Srl" 164 "MTU Friedrichshafen GmbH (formerly DaimlerChrysler Off-Highway)" 163 "BRP Inc." 162 "Axiomatic Technologies" 161 "Offshore Systems (UK) Ltd" 160 "Nido" 159 "NTech Industries Inc" 158 "Firestone Industrial Products Company" 157 "ISSPRO Inc." 156 "ITT Industries - Cannon" 155 "Vetronix Corporation" 154 "Westerbeke Corporation" 153 "Woodward, Industrial Controls Division" 152 "elobau GmbH & Co. KG" 151 "Raven Industries, Inc." 150 "Fleetguard" 149 "Holset" 148 "Blue Water Data, Inc." 147 "Nautibus electronic GmbH" 146 "Maxima Technologies" 145 "MurCal Controls" 144 "Mercury Marine" 143 "W. Gmeiner GmbH & Co." 142 "TRW Automotive (Commercial Steering Systems)" 141 "Thales Navigation Ltd." 140 "Lowrance Electronics, Inc." 139 "Caterpillar Trimble Control Technologies (CTCT), LLC" 138 "Georg Fritzmeier GmbH & Co. KG" 137 "Maretron" 136 "Komatsu Ltd" 135 "Airmar Technology Corporation" 134 "Iris Technology Ltd" 133 "Bucher Schoerling GmbH" 132 "Mulag-Fahrzeugwerk" 131 "ITT Industries" 130 "Nido - Universal Machines B.V." 129 "OMNEX Control Systems Inc." 128 "Gerhard Duecker GmbH & Co. KG" 127 "Holland USA" 126 "Driver Tech" 125 "Nevada Automotive Test Center" 124 "Hydac Electronic" 123 "Basler Electric" 122 "FG Wilson (Engineering) Limited" 121 "HED (Hydro Electronic Devices, Inc.)" 120 "RDS Technology Ltd" 119 "IntegriNautics  " 118 "Intron GmbH" 117 "HUSCO International" 116 "BEELINE Technologies" 115 "NACCO Materials Handling Group, Inc." 114 "EControls, Inc." 113 "Stress-Tek, Inc." 112 "MECALAC" 111 "Maschinenfabrik Bernard Krone GmbH" 110 "EPIQ Sensor-Nite" 109 "TeeJet Technologies Denmark (formerly LH Technologies ApS)" 108 "WTK-Elecktronik GmbH" 107 "Grimme Landmaschinen GmbH & Co. KG" 106 "BAE Systems Controls, Inc." 105 "Kiepe Elektrik GmbH & Co. KG" 104 "CLAAS KGaA mbH (formerly CLAAS Selbstfahrende Erntemaschinen GmbH)" 103 "CLAAS E-Systems KGaA mbH & Co. KG (formerly CLAAS Agrosystems GmbH & Co. KG)" 102 "AGCO (formerly AGCO GmbH & Co.)" 101 "Sensoria" 100 "VDO Technik AG" 99 "International Transmissions Ltd (ITL)" 98 "Mueller-Elektronik GmbH & Co" 97 "Ag Leader Technology, Inc." 96 "Mech@tronic IT GmbH" 95 "Pacific Insight Electronics Corp." 94 "CNH Industrial N.V. (formerly CNH Global N.V.)" 93 "Perkins Engines Company Ltd." 92 "Ag-Chem Equipment Co., Inc." 91 "BSG Bodensee Steuergeraete GmbH" 90 "Knorr-Bremse SfN GmbH" 89 "Kverneland Group, Electronics Division" 88 "Satloc Precision GPS" 87 "J.C. Bamford Excavators Ltd (JCB)" 86 "C. E. Niehoff & Company" 85 "Kohler Co" 84 "New Holland UK Limited" 83 "Bendix VORAD Technologies (formerly Eaton VORAD Technologies)" 82 "Bobcat/Ingersoll-Rand (formerly Melroe/Ingersoll-Rand)" 81 "Fire Research Corp." 80 "Twin Disc, Inc." 79 "Daimler Benz AG - Engine Division (PBM)" 78 "Frank W. Murphy Manufacturing, Inc" 77 "Deere Power Systems Group" 76 "unused (formerly Deere & Co, Construction Division)" 75 "Deere & Co, Agricultural Division" 74 "Eaton Axle-Brake Division" 73 "LeTourneau, Inc." 72 "Sisu Corporation" 71 "Vansco Electronics Ltd." 70 "Flex-coil Limited" 69 "Trimble Navigation" 316 "ITT Flow Control" 315 "Icom Incorporated" 314 "CSM GmbH" 313 "Ilmor Engineering, Inc." 312 "Lectronix, Inc." 311 "Patrick Power Products" 310 "TECNORD srl" 309 "Krauss-Maffei Wegmann GmbH & Co. KG" 308 "Cyntrx" 307 "MAS Technologies" 306 "Sleipner Motor AB" 305 "NovAtel Inc" 304 "EmpirBus AB" 303 "CTS Corporation" 302 "Nissin Kogyo Co., LTD" 301 "Parker Hannifin (UK) Ltd FDE group" 300 "Systron Donner Automotive" 299 "Rauch" 298 "Holley Performance" 297 "Zonar Systems Inc" 296 "micro dynamics GmbH" 295 "BEP Marine" 294 "Grayhill Inc." 293 "Spyder Controls Corp." 292 "IKUSI - Angel Iglesias S.A." 291 "Groeneveld Transport Efficiency BV" 290 "Kuebler GmbH" 289 "Watlow" 288 "Mitsubishi FUSO Truck & Bus Corp." 287 "NTech Industries, Inc" 286 "Coelmo srl" 285 "Sea Recovery Corp" 284 "Mobile Tech Chile" 283 "CWF Hamilton & Co Ltd" 282 "Medallion Instrumentation Systems" 281 "Precision Governors LLC" 280 "Leica Geosystems Pty Ltd" 279 "Geometris LP" 278 "Takata Electronics" 277 "LHP Telematics" 276 "Aqua-Hot Heating Systems" 275 "Navico Egersund AS" 274 "LTW Technology Co., LTD" 273 "Active Research Limited" 272 "Gross Mechanical Laboratories, Inc" 271 "Cole Hersee" 270 "Tennant" 269 "Saft America Inc.,  Space & Defense Division" 268 "Accurate Technologies" 267 "Red Lion Controls, Inc" 266 "International Thermal Research Ltd" 265 "MTS Sensor Technologie GmbH" 264 "Autolync" 213 "CNH Belgium N.V." 212 "Sure Power Industries, Inc" 211 "DNA Group" 210 "Iteris, Inc." 209 "Bell Equip. Co. SA (PTY) LTD" 208 "Drew Technologies, Inc" 207 "Otto Engineering" 206 "port GmbH" 205 "SmarTire Systems Inc" 204 "The Morey Corporation" 203 "MILtronik GmbH" 202 "Curtis Instruments, Inc" 201 "Disenos y Tecnologia S.A." 200 "MGM Brakes" 199 "Actia Corp" 198 "Mystic Valley Communications" 197 "Mechron Power Systems" 196 "LEMKEN GmbH & Co KG" 195 "General Engine Products" 194 "TriMark Corporation" 193 "Jeppesen Marine" 192 "Floscan" 191 "XRS Corporation (formerly XATA Corporation)" 190 "Hella KGaA Hueck & Co" 189 "QUALCOMM" 188 "EMP Corp" 187 "Air-Weigh" 186 "Altronic, Inc" 185 "Beede Electrical Instrument Company" 184 "EIA Electronics" 183 "KDS Controls, Inc" 182 "Vehicle Systems Engineering B.V." 181 "Coretronics, Inc." 180 "Smart Power Systems" 179 "TeeJet Technologies Springfield (formerly Midwest Technologies Illinois, LLC)" 178 "Continental Automotive GmbH (formerly Siemens VDO Automotive AG)" 177 "Diagnostic Systems Associates" 176 "Moritz Aerospace" 175 "Veris Technologies, Inc." 174 "AB Volvo Penta" 173 "Ryeso, Inc." 172 "Yanmar Co., Ltd. (formerly Yanmar Marine USA)" 171 "Wachendorff Elektronik GmbH & Co. KG" 170 "Computronics Corporation Ltd." 169 "Marlin Technologies Inc." 168 "Xantrex" 167 "JLG Industries Inc" 166 "John Deere Electronic Solutions (formerly Phoenix International)" 165 "CPAC Systems AB" 68 "Scania" 67 "John Deere Coffeyville Works (formerly Funk Manufacturing Company)" 66 "John Deere Construction Equipment Division" 65 "MAN Nutzfahrzeuge AG" 64 "Unused (formerly SpectraPrecision Laserplane, then SpectraPhysics)" 63 "ZF Industries Inc." 62 "Wabco" 61 "Volvo Truck Corp." 60 "Volvo Trucks North America Inc." 59 "VES Inc." 58 "SPX Corporation, OTC Div" 57 "Danfoss  (formerly Sauer Sundstrand Co, then Sauer-Danfoss Co)" 56 "SAIC" 55 "Ryder System Inc." 54 "Meritor Wabco" 53 "Continental Automotive Systems US, Inc. (formerly Rockwell Land Transportation)" 52 "Meritor Automotive, Inc. (formerly Rockwell Automotive)" 51 "Robert Bosch GmbH" 50 "Robert Bosch Corp" 49 "RE America Inc." 48 "Pollak Alphabet" 47 "Phillips Semiconductor" 46 "Noregon Systems, Inc  (formerly Parasoft Computing Solutions)" 45 "PACCAR" 44 "Nippondenso Co. Ltd." 43 "International Truck and Engine Corporation - Vehicle Electronics (formerly Navistar Intl Trans Corp.)" 42 "International Truck and Engine Corporation - Engine Electronics  (formerly Navistar Intl Trans Co., Engine Electronics)" 41 "Motorola Inc." 40 "Motorola AIEG Inc." 39 "Microfirm Inc." 38 "Micro Processor Systems Inc." 37 "Mack Trucks Inc." 36 "Lucas Ind." 35 "Kenworth Truck Co." 34 "Kelsey Hayes Co." 33 "John Deere" 32 "Jacobs Vehicle Systems" 31 "J Pollak Corp" 30 "Isuzu Motors Ltd" 29 "Hino Motors Ltd." 28 "Grote Ind. Inc." 27 "GMC" 26 "General Motors Corp, Service Technology Grp" 25 "Daimler Trucks North America LLC (formerly Freightliner LLC)" 24 "Ford Motor Co., Vehicle Controls" 23 "Ford Motor Co., Heavy Truck" 22 "Ford Motor Co., Electronic Concepts & Systems" 21 "Echlin Inc., Midland Brake Inc." 20 "Eaton Ltd" 19 "Eaton Corp. Trucking Info Services" 18 "Eaton Corp, Transmission Div." 17 "Eaton Corp, Corp Res & Dev" 16 "Eaton Corp" 15 "DICKEY-john Corporation" 14 "Detroit Diesel Corporation" 13 "Delco Electronics" 12 "Deere & Company, Precision Farming" 11 "Dearborn Group Inc." 10 "Cummins Inc (formerly Cummins Engine Co)" 9 "Chrysler Corp." 8 "Caterpillar Inc." 7 "Case Corp." 6 "Berifors Electronics AB" 5 "AMP Inc." 4 "Ametek-Dixson" 3 "Ametek, US Gauge Division" 2 "Allison Transmission, Inc." 1 "Bendix Commercial Vehicle Systems LLC (formerly Allied Signal Inc.)" 0 "Reserved" ;
VAL_ 2565799434 IndustryGroup 7 "Reserved for SAE" 5 "IndustrialProcessCtrlStationary" 4 "Marine" 3 "Construction" 2 "Agricultural and Forestry" 1 "On-Highway" 0 "Global" ;
VAL_ 2565799434 VehicleSystem 127 "Not Available" 0 "Non-specific System" ;
VAL_ 2565799434 VehicleSystem5 0 "Ind. Process Control Stationary" 127 "Not Available" ;
VAL_ 2565799434 VehicleSystem4 0 "Non-specific System" 127 "Not Available" 10 "System Tools" 20 "Safety Systems" 25 "Inter/Intranetwork Device" 30 "Electrical Distribution" 40 "Steering and Control Surfaces" 50 "Propulsion" 60 "Navigation" 70 "Communications" 80 "Instrumentation/General Systems (deprecate)" 90 "Internal Environment" 100 "Deck, Cargo and Fishing Equipment" 35 "Electrical Generation" 75 "Sensor Communication Interface" 85 "External Environment" 120 "Display" 125 "Entertainment" ;
VAL_ 2565799434 VehicleSystem3 0 "Non-specific System" 127 "Not Available" 1 "Skid Steer Loader" 2 "Articulated Dump Truck" 3 "Backhoe" 4 "Crawler" 5 "Excavator" 6 "Forklift" 7 "Four Wheel Drive Loader" 8 "Grader" ;
VAL_ 2565799434 VehicleSystem2 0 "Non-specific System" 127 "Not Available" 1 "Tractor" 2 "Tillage" 3 "Secondary Tillage" 4 "Planters/Seeders" 5 "Fertilizers" 6 "Sprayers" 7 "Harvesters" 8 "Root Harvesters" 9 "Forage" 10 "Irrigation" 11 "Transport/Trailer" 12 "Farm Yard Operations" 13 "Powered Auxiliary Device" 14 "Special Crops" 15 "Earth Work" 16 "Skidder" 17 "Sensor Systems" 19 "Timber Harvesters" 20 "Forwarders" 21 "Timber loaders" 22 "Timber Processing Machines" 23 "Mulchers" 24 "Utility Vehicles" 25 "Slurry Applicators" ;
VAL_ 2565799434 VehicleSystem1 0 "Non-specific System" 127 "Not Available" 1 "Tractor" 2 "Trailer" ;
VAL_ 2565799434 Function 43 "Transmission Display" 44 "Exhaust Emission Control" 45 "Vehicle Dynamic Stability Control" 46 "Oil Sensor Unit" 47 "Information System Controller" 48 "Ramp Control" 49 "Clutch/Converter Control" 50 "Auxiliary Heater" 51 "Forward-Looking Collision Warning System" 52 "Chassis Controller" 53 "Alternator/Charging System" 54 "Communications Unit, Cellular" 55 "Communications Unit, Satellite" 56 "Communications Unit, Radio" 57 "Steering Column Unit" 58 "Fan Drive Control" 59 "Starter" 60 "Cab Display" 61 "File Server/Printer" 62 "On-Board Diagnostic Unit" 63 "Engine Valve Controller" 64 "Endurance Braking" 65 "Gas Flow Measurement" 66 "I/O Controller" 67 "Electrical System Controller" 68 "Aftertreatment system gas measurement" 69 "Engine Emission Aftertreatement System" 70 "Auxiliary Regeneration Device" 71 "Transfer Case Control" 72 "Coolant Valve Controller" 73 "Rollover Detection Control" 74 "Lubrication System" 75 "Supplemental Fan" 76 "Temperature Sensor" 77 "Fuel Properties Sensor" 78 "Fire Suppression System" 79 "Power Systems Manager" 80 "Electric Powertrain" 81 "Hydraulic Powertrain" 82 "File Server" 83 "Printer" 84 "Start Aid Device" 85 "Engine Injection Control Module" 86 "Reserved" 87 "Reserved" 88 "Reserved" 89 "Reserved" 90 "Reserved" 91 "Reserved" 92 "Reserved" 93 "Reserved" 94 "Reserved" 95 "Reserved" 96 "Reserved" 97 "Reserved" 98 "Reserved" 99 "Reserved" 100 "Reserved" 0 "Engine" 1 "Auxiliary Power Unit (APU)" 2 "Electric Propulsion Control" 3 "Transmission" 4 "Battery Pack Monitor" 5 "Shift Control/Console" 6 "Power TakeOff - (Main or Rear)" 7 "Axle - Steering" 8 "Axle - Drive" 9 "Brakes - System Controller" 10 "Brakes - Steer Axle" 11 "Brakes - Drive Axle" 12 "Retarder - Engine" 13 "Retarder - Driveline" 14 "Cruise Control" 15 "Fuel System" 16 "Steering Controller" 17 "Suspension - Steer Axle" 18 "Suspension - Drive Axle" 19 "Instrument Cluster" 20 "Trip Recorder" 21 "Cab Climate Control" 22 "Aerodynamic Control" 23 "Vehicle Navigation" 24 "Vehicle Security" 25 "Network Interconnect ECU" 26 "Body Controller" 27 "Power TakeOff (Secondary or Front)" 28 "Off Vehicle Gateway" 29 "Virtual Terminal (in cab)" 30 "Management Computer" 31 "Propulsion Battery Charger" 32 "Headway Controller" 33 "System Monitor" 34 "Hydraulic Pump Controller" 35 "Suspension - System Controller" 36 "Pneumatic - System Controller" 37 "Cab Controller" 38 "Tire Pressure Control" 39 "Ignition Control Module" 40 "Seat Control" 41 "Lighting - Operator Controls" 42 "Water Pump Control" 101 "Reserved" 102 "Reserved" 103 "Reserved" 104 "Reserved" 105 "Reserved" 106 "Reserved" 107 "Reserved" 108 "Reserved" 109 "Reserved" 110 "Reserved" 111 "Reserved" 112 "Reserved" 113 "Reserved" 114 "Reserved" 115 "Reserved" 116 "Reserved" 117 "Reserved" 118 "Reserved" 119 "Reserved" 120 "Reserved" 121 "Reserved" 122 "Reserved" 123 "Reserved" 124 "Reserved" 125 "Reserved" 126 "Reserved" 127 "Reserved" 128 "Non Virtual Terminal Display" 129 "Operator Controls" 130 "Task Controller" 131 "Position Control" 132 "Machine Control" 133 "Foreign Object Detection" 134 "Tractor ECU" 135 "Sequence Control Master" 136 "Product Dosing" 137 "Product Treatment" 138 "Reserved" 139 "Data Logger" 140 "Decision Support" 141 "Lighting Controller" 142 "TIM Server" 255 "Not Available" ;
VAL_ 2565799434 ManufacturerCode 1863 "Thomas G. Faria Co." 1862 "Sanshin" 1861 "Vector North America " 1860 "MMP" 1859 "Kvasar AB" 1858 "Litton" 1857 "Simrad" 1856 "Trimble" 1855 "Furuno USA" 1854 "Northstar Technologies" 1853 "Japan Radio Co" 1852 "Navionics" 1851 "RayMarine" 1850 "Teleflex" 786 "Johnson Matthey Battery Systems" 785 "Fischer Panda GmbH" 784 "CM Automotive Systems, Inc." 783 "Loup Electronics Inc." 782 "AVR bvba" 781 "Poly-Planar LLC" 780 "AVID Technology Ltd" 779 "RLC Electronic Systems" 778 "Seakeeper Inc." 777 "Ocean Signal Ltd" 776 "HMI Systems LLC" 775 "ZIEHL-ABEGG Automotive GmbH" 774 "Taisho Corporation" 773 "Clarion Corporation of America" 772 "Blink Marine" 771 "Shaw Development, LLC" 770 "MONOSEM" 769 "Trombetta" 768 "Flores Automation, LLC" 767 "Alliance Wireless Technologies Inc." 766 "Epec Oy" 765 "GIGAVAC" 764 "Bednar FMT s.r.o." 763 "AT-Systems BVBA" 762 "ROJ s.r.l." 761 "MITA OLEODINAMICA S.p.A." 760 "Bernecker + Rainer Industrie Elektronik GmbH" 759 "Hydro-Gear" 758 "Banner Engineering Corp." 757 "IMPCO Technologies" 756 "Maschio Gaspardo S.P.A." 755 "Firefly Integrations" 754 "Parker Hannifin Corp., Automation Group" 753 "AIROD Technologies" 752 "Deep Sea Electronics Plc" 751 "Pacific Track" 750 "Joskin SA" 749 "Chart Inc." 748 "ISOTTA" 747 "Agratronix" 746 "SureFire Ag Systems, Inc." 745 "Cidra Corporate Services Inc." 744 "Woosung Engineering Co., Ltd." 743 "Daemyung Elevator Co., Ltd." 742 "EROAD" 741 "Carling Technologies" 740 "e-Traction" 739 "LXNAV d.o.o." 738 "Blue Ink Technologies" 737 "Balluff GmbH" 736 "Terex Aerial Work Platforms - Genie" 735 "AEM Performance Electronics" 734 "REAPsystems" 733 "Intendia S.L." 732 "Gefran S.p.A." 731 "Modine Manufacturing Company" 730 "BERTHOUD AGRICOLE" 729 "Liebherr" 728 "Streumaster / Panien" 727 "Dhoot Transmission Pvt Ltd." 726 "MIDORI PRECISIONS" 725 "Hitachi Construction Machinery Co., Ltd." 724 "Electronic Applications, Inc." 723 "Jabil Inc." 722 "Contelec AG" 721 "Hypro" 720 "WITZ Corporation" 719 "Cojali S. L." 718 "Micronet Inc" 717 "Yacht Devices Ltd" 716 "Eaton Control & Power Conversion Division (CPCD)" 715 "Autonnic Research Ltd" 714 "Kobashi Kogyo Co., Ltd." 713 "US Hybrid Corporation" 712 "LOR Manufacturing Company Inc." 711 "DAS Co., LTD" 710 "Greentronics Ltd." 709 "Marquardt GmbH" 708 "Lars Thrane A/S" 707 "Rochester Gauges Inc" 706 "Shanghai Diesel Engine Corporation Limited" 705 "SVAB Hydraulik AB" 704 "JL Audio, Inc." 703 "Hydro Tab Marine Engineering" 702 "Weichai Power Co., Ltd." 701 "BigRoad Inc." 700 "K-Tec Earthmovers Inc." 699 "Harman International Industries" 698 "Scorpion Technologies Ltd." 697 "Ålö AB" 696 "DRS Network & Imaging Systems, LLC (DRS Technologies)" 695 "Weldon Technologies" 694 "GasTOPS Ltd." 693 "Agility Fuel Solutions (formerly Agility Fuel Systems)" 692 "Tanhay Corporation" 691 "Digitroll Agricultural Electronics" 690 "LINAK A/S" 689 "Aarcomm Systems Inc" 688 "Rockford Corp" 687 "Flight Systems, Inc." 686 "Taigene Electric Machinery Corp." 685 "ANEDO Ltd." 684 "KEB" 683 "Fosen Elektro" 682 "Eckelmann AG" 681 "BEDIA Motorentechnik GmbH & Co. KG" 680 "AMVAC Chemical Corporation" 679 "Cimco Marine AB" 678 "KeepTruckin, Inc." 677 "DSA Daten- und Systemtechnik GmbH" 676 "Danfoss IXA A/S" 675 "Kawasaki Motors Corp., USA" 674 "Yara International ASA" 673 "Caruelle Nicolas" 672 "OPTIMA Concept" 671 "Innovative Controls Inc." 670 "STEMCO LP" 669 "Quantum Fuel Systems Technologies Worldwide, Inc" 668 "MacDon Industries Ltd." 667 "Bartec" 666 "Schaeffler Technologies AG & Co., KG" 665 "Gebr. Bode GmbH & Co. KG" 664 "Level Developments Ltd" 663 "Delta Systems, Inc" 662 "Kissling Elektrotechnik GmbH" 661 "SPAL Automotive S.r.l." 660 "Auto-Gaz Centrum" 659 "Data Panel Corp." 658 "Shenzhen Jiuzhou Himunication Technology Co., Ltd" 657 "Terzo Power Systems" 656 "PRO SOLUS do Brasil" 655 "Genge & Thoma AG" 654 "Kohler Power Systems, Detroit Engine Development Center (DEDC)" 653 "AEV, spol. s r. o." 652 "MicroControl GmbH & Co. KG" 651 "Takakita Co, Ltd." 650 "Seiko Epson Corp." 649 "Control-Q BV" 648 "OJSC Ekran" 647 "Siloking" 646 "Veenhuis Machines BV" 645 "esd electronic system design gmbh" 644 "KUS USA" 643 "Bogballe A/S" 642 "Moog / Aspen Motion Technologies" 641 "Diverse Yacht Services" 640 "Power Solutions International" 639 "Startec s.r.l." 638 "KVH Industries, Inc." 637 "Bavaria Yachtbau GmbH" 636 "Divelbiss Corporation" 635 "Argo Tractors S.p.A." 634 "Rocky Research" 633 "TORC Robotics" 632 "Pepperl+Fuchs GmbH" 631 "Reltima" 630 "SmartDrive Systems Inc." 629 "Agri Info Design, Ltd." 524 "Vomax Instrumentation Pty. Ltd." 523 "Reggio Emilia Innovazione" 522 "Nebraska Tractor Test Laboratory" 521 "Clever Devices Ltd." 520 "Trapeze" 519 "Peeters Landbouwmachines b.v." 518 "Transas USA Inc." 517 "Noland Engineering" 516 "AVAT Automation GmbH" 515 "GINAF Trucks Nederland B.V." 514 "DISTek Integration, Inc." 513 "FarmscanAg" 512 "Inpower LLC" 511 "Sulky" 510 "Marinesoft Co. Ltd" 509 "MOTORTECH GmbH" 508 "Transtech Innovations" 507 "ISOBUS Test Center" 506 "IHI STAR Machinery Corporation" 505 "Yetter Farm Equipment" 504 "Vesper Marine" 503 "Naviop S.R.L." 502 "Attwood Corporation" 501 "Agrotronix S.A." 500 "Oxbo International Corporation" 499 "LCJ Capteurs" 498 "Innovative Design Solutions, Inc." 497 "SENTRON Sistemas Embarcados" 496 "W. Gessmann GmbH" 495 "HOLMER Maschinenbau GmbH" 494 "Synerject" 493 "Watcheye" 492 "Inergy Automotive Systems" 491 "Penny and Giles Ltd" 490 "QuikQ" 489 "Appareo Systems, LLC" 488 "The Charles Machine Works, Inc." 487 "DSE Test Solutions A/S" 486 "Westport Innovations Inc." 485 "MATT automotive" 484 "Headsight Inc." 483 "Valeo" 482 "Tricon Electronics" 481 "Chetco Digital Instruments" 480 "EnerDel, Inc." 479 "Vapor Bus International" 478 "OceanSat BV" 477 "OilQuick AB" 476 "Hummingbird Marine Electronics" 475 "GME" 474 "Persen Technologies Inc." 473 "Boss Industries, Inc." 472 "Tenneco Inc." 471 "Sea Cross Marine AB" 628 "Falck Schmidt Defence Systems" 627 "Radio Ocean" 626 "AVL DiTEST GmbH" 625 "Global MRV Inc." 624 "Blackbox Machine Control Pty Ltd" 623 "Xirgo Technologies" 622 "Floyd Bell Inc" 621 "Hagie Manufacturing Company" 620 "Sevcon Ltd." 619 "Right Weigh Load Scales" 618 "Evrard SA" 617 "Zero Emission Vehicles" 616 "SMART-TEC s.r.o." 615 "Networkfleet, Verizon Telematics" 614 "ARLT Technologies GmbH" 613 "HKS Co., Ltd." 612 "Samwon IT" 611 "Esterline" 610 "Trail Tech" 609 "Walvoil S.p.A." 608 "Gale Banks Engineering" 607 "Knappco/Civacon" 606 "Intellian Technologies" 605 "Aventics GmbH" 604 "Indexator Rototilt Systems AB" 603 "Kereval" 602 "Nomad Digital Ltd." 601 "Navitas Systems" 600 "Aquatic AV" 599 "Spudnik Equipment Co, LLC" 598 "ABB Turbo Systems Ltd" 597 "Hydac Filter Systems GmbH" 596 "Brunelco Electronic Innovators B.V." 595 "CustomWare" 594 "Kongsberg Automotive" 593 "Sensata Technologies" 592 "tecsis GmbH" 591 "United States Coast Guard" 590 "ARGO-HYTOS GMBH" 589 "MICO, Inc." 588 "Vignal Systems" 587 "JCA Electronics" 586 "Suzuki Motor Corp" 585 "Industrial Electronic Controls" 584 "CarMedialab GmbH" 583 "Yachtcontrol" 582 "Innovative Software Engineering" 581 "Väderstad - Verken AB" 580 "San Jose Technology, Inc." 579 "KVH Industries, Inc." 578 "advanSea" 577 "Denchi Power Ltd  (formerly ABSL Power Solutions Limited)" 576 "Vectia" 575 "Lytx" 574 "Vishay Precision Group" 573 "Orolia Ltd" 572 "Fasse Valves" 571 "Marinecraft Co., Ltd." 570 "frenzel + berg electronic GmbH & Co. KG" 569 "LORD MicroStrain Sensing Systems" 568 "Makersan Ltd. Co." 567 "Lithiumstart LLC" 566 "Geode Technology, Inc." 565 "Micro-Trak Systems, Inc." 564 "Auto Power Electronic" 563 "LOHR Sistemas Eletronicos LTDA" 562 "Bombardier Transportation GmbH" 561 "b-plus GmbH" 560 "Iowa State University, Agricultural and Biosystems Engineering" 559 "Four Peaks Navigation" 558 "Davis Instruments Corp." 557 "Rockson Automation GmbH" 556 "Doosan Infracore Norway" 555 "Sasaki Corporation" 554 "iris-GmbH infrared & intelligent sensors" 553 "KIB Electronics" 552 "Matsuyama Plow Mfg Co, Ltd" 551 "Wexler CSD Ltd." 550 "SUN-A Corporation" 549 "ROAD Deutschland GmbH" 548 "TM4 Inc." 547 "Thomson Linear LLC" 546 "Maruyama Mfg Co, Inc." 545 "GS Hydraulics" 544 "Au Group Electronics" 543 "BAUER Maschinen GmbH" 542 "Dinamica Generale s.p.a." 541 "Total Fire Systems, Inc." 540 "Dinex A/S" 539 "Mobileview" 538 "Crop Ventures, Inc." 537 "Schrader Electronics Ltd." 536 "SSI Technologies" 535 "MOTORPAL, a.s." 534 "Webasto Thermo & Comfort SE" 533 "Doran Manufacturing, LLC" 532 "Onwa Marine Electronics Co Ltd." 531 "Genge & Thoma AG" 530 "NMEA" 529 "National Instruments Korea" 528 "Hoganas AB, Electric Drive Systems" 527 "GKN Walterscheid GmbH" 526 "LOFA Industries, Inc" 525 "Rust Sales INC" 470 "SI-TEX Marine Electronics" 469 "RA Consulting GmbH" 468 "Tyco Fire Protection Products" 467 "Lely Industries N.V." 466 "Veethree Electronics and Marine LLC" 465 "Ashcroft Inc" 464 "Leach International Corporation" 463 "PROBOTIQ" 462 "IHI Shibaura Machinery Corporation" 461 "HAWE Hydraulik SE" 460 "San Giorgio S.E.I.N." 459 "Alltek Marine Electronics Corp" 458 "Control Solutions, Inc." 457 "RUSELPROM-ElectricDrive Ltd" 456 "General Kinetics" 455 "ADZ NAGANO GmbH" 454 "NGK Spark Plug Co. Ltd" 453 "Cooper Bussmann" 452 "WIKA Alexander Wiegand SE & Co. KG" 451 "Parker Hannifin Corp" 450 "Dycor Technologies Ltd." 449 "Polaris Industries Inc" 448 "Stanadyne Corporation, Electronics Systems" 447 "Great Plains Mfg." 446 "CertTech, L.L.C." 445 "KAT MECHATRONIC, Electronic Product Division" 444 "ITT Power Solutions" 443 "SignalQuest, Inc." 442 "Horsch Maschinen GmbH" 441 "PTG Reifendruckregelsysteme GmbH" 440 "Cummins Power Generation" 439 "Hyundai Heavy Industries" 438 "Comar Systems Ltd" 437 "Digital Yacht Limited" 436 "Kinze Manufacturing" 435 "Zunhammer GmbH" 434 "Stored Energy Systems" 433 "Rowe Electronics" 432 "S&A Systems, Inc." 431 "Tohatsu Corporation" 430 "Auteq Telematica S.A." 429 "Rota Engineering Ltd." 425 "Methode Electronics Inc, MDI" 424 "Odyne LLC" 423 "BSM Wireless, Inc." 422 "True Heading AB" 421 "Vertex Standard Co, Ltd" 420 "Vermeer Corporation, ACS Group" 419 "Fusion Electronics Ltd" 418 "Intellistick Inc" 417 "KZValve" 416 "Kubota Corporation" 415 "Valid Manufacturing Ltd." 414 "Cattron Group International" 413 "Datapross Nijbroek bv" 412 "WebTech Wireless Inc." 411 "Hy-Drive Technologies Ltd." 410 "COBO S.p.A. Divisione 3B6" 409 "Transfluid S.r.L." 408 "Corvus Energy Ltd." 407 "Comtech Mobile Datacom" 406 "Vecima Networks Inc." 405 "Wema System AS" 404 "Com Nav Marine Ltd" 403 "Trackwell ADS, Inc." 402 "Simma Software, Inc." 401 "Torqeedo GmbH" 400 "Livorsi Marine" 399 "ISEKI & Co., Ltd." 398 "Hilite International" 397 "Sanyo-kiki Co Ltd." 396 "Beyond Measure" 395 "GENTEC S.R.L." 394 "Capi 2 Nederland BV" 393 "Harvest Tec, Inc" 392 "Tianyuan Technology Co Ltd." 391 "Electronic Design for Industry, Inc" 390 "Partech Inc." 389 "Benchmark Electronics, Minnesota Division" 388 "Innomatix, LLC" 387 "Orscheln Products, LLC" 386 "JLG Automation BVBA" 385 "Johnson Outdoor Marine Electronics" 384 "Camano Light" 383 "MCL Industries" 382 "National Agriculture and Food Research Organization" 381 "B & G" 380 "Suntech International Ltd." 379 "Yamabiko Corporation" 378 "Glendinning Marine Products" 377 "ifm electronic gmbh" 376 "Quake Global" 375 "Williams Controls Inc." 374 "Northern Lights, Inc." 373 "Electronic Design Inc." 372 "Delphi" 371 "Heinzmann GmbH & Co. KG" 370 "Rolls-Royce Marine AS" 369 "Power Torque Engineering Ltd" 368 "HANSENHOF_electronic" 367 "Fliegl Agrartechnik" 366 "Viewnyx Corp." 365 "Digi-Star, LLC" 364 "OEM Controls Inc." 363 "BEI Duncan" 362 "Poettinger Landtechnik GmbH (formerly Alois Poettinger Maschinenfabrik GmbH)" 361 "InMach" 360 "HJS Emission Technology GmbH & Co KG   (formerly HJS Fahrzeugtechnik GmbH & Co KG)" 359 "Ludwig Bergmann GmbH" 358 "Victron Energy BV" 357 "Hardi International A/S" 356 "Fischer Panda Generators, Inc" 355 "Mastervolt International B.V." 354 "Junkkari OY" 353 "Hegemon Electronics, Inc." 352 "SAME DEUTZ-FAHR GROUP S.p.A." 351 "Thrane & Thrane" 350 "Noris Marine Systems GmbH & Co KG" 349 "Suonentieto" 348 "Amazonen Werke H. Dreyer" 347 "Honeywell" 346 "Control Solutions" 345 "Korean Maritime University" 344 "Parvus Corporation" 343 "Baumer Group" 342 "THOMAS MAGNETE GmbH" 341 "Boning GmbH & Co" 340 "Continental AG" 339 "Competence Center ISOBUS e.V." 338 "GRAF-SYTECO" 337 "Carraro S.p.A." 336 "APE s.r.o." 335 "Evo Electric Ltd" 334 "Takata-Petri AG" 333 "Hadley Products Corporation" 332 "HWH Corporation" 331 "Horton, Inc." 330 "Kidde Aerospace and Defense" 329 "Deif A/S" 328 "Qwerty Electronik AB" 327 "Sonceboz SA" 326 "Akron Brass Company" 325 "ASM Automation Sensorik Messtechnik GmbH" 324 "Snap-on Diagnostics" 323 "Mobileye Vision Technologies Ltd." 322 "MICHENKA s.r.o." 321 "Ultra Electronics, Electrics" 320 "Miedema Landbouwwerktuigenfabriek B.V." 319 "Cadec Global" 318 "SAT Plan" 317 "Navtronics Bvba" 263 "IMMI" 262 "HydraForce, Inc" 261 "Red Dot Corporation" 260 "Reichhardt GmbH Steuerungstechnik" 259 "Jetter AG" 258 "ARAG" 257 "Honda Motor Co., Ltd" 256 "Tyco Electronics AMP" 255 "MEAS France" 254 "GE Sensing" 253 "Mobile Control Systems" 252 "Sensor-Technik Wiedemann GmbH" 251 "German Agricultural Society, Test Center (DLG)" 250 "Kuhn Group" 249 "Schaltbau GmbH" 248 "Cooper Standard Automotive Active Systems Group" 247 "ePULSE" 246 "Class 1, Inc" 245 "Capstan Ag Systems, Inc." 244 "Techno-Matic" 243 "eRide, Inc." 242 "Kokusandenki Co. Ltd" 241 "Schneider Automation SAS" 240 "Vanair Mfg" 239 "May & Scofield Ltd" 238 "ZF Friedrichshafen AG" 237 "Agtron Enterprises Inc" 236 "NORAC Systems International Inc" 235 "SailorMade Marine Telemetry - Tetra Technology Ltd." 234 "Mondial electronic GmbH" 233 "Yacht Monitoring Solutions Inc." 232 "TSD Integrated Controls" 231 "Topcon Positioning Systems, Inc." 230 "Saucon Technologies" 229 "Garmin International Inc." 228 "Unused (formerly ZF Marine Electronics)" 227 "Lykketronic A/S" 226 "Monaco Coach Corporation" 225 "SKF" 224 "EMMI Network, S.L." 223 "Vaueo Retarder Co., Ltd." 222 "Generac Power Systems, Inc." 221 "SiE" 220 "Beede Electrical Instrument Company, Inc" 219 "Cat OEM Solutions" 218 "Gits Manufacturing Company" 217 "RM Michaelides Software & Elektronik GmbH" 216 "Paneltronics Inc." 215 "Aetna Engineering/Fireboy-Xintex" 214 "MC elettronica Srl" 164 "MTU Friedrichshafen GmbH (formerly DaimlerChrysler Off-Highway)" 163 "BRP Inc." 162 "Axiomatic Technologies" 161 "Offshore Systems (UK) Ltd" 160 "Nido" 159 "NTech Industries Inc" 158 "Firestone Industrial Products Company" 157 "ISSPRO Inc." 156 "ITT Industries - Cannon" 155 "Vetronix Corporation" 154 "Westerbeke Corporation" 153 "Woodward, Industrial Controls Division" 152 "elobau GmbH & Co. KG" 151 "Raven Industries, Inc." 150 "Fleetguard" 149 "Holset" 148 "Blue Water Data, Inc." 147 "Nautibus electronic GmbH" 146 "Maxima Technologies" 145 "MurCal Controls" 144 "Mercury Marine" 143 "W. Gmeiner GmbH & Co." 142 "TRW Automotive (Commercial Steering Systems)" 141 "Thales Navigation Ltd." 140 "Lowrance Electronics, Inc." 139 "Caterpillar Trimble Control Technologies (CTCT), LLC" 138 "Georg Fritzmeier GmbH & Co. KG" 137 "Maretron" 136 "Komatsu Ltd" 135 "Airmar Technology Corporation" 134 "Iris Technology Ltd" 133 "Bucher Schoerling GmbH" 132 "Mulag-Fahrzeugwerk" 131 "ITT Industries" 130 "Nido - Universal Machines B.V." 129 "OMNEX Control Systems Inc." 128 "Gerhard Duecker GmbH & Co. KG" 127 "Holland USA" 126 "Driver Tech" 125 "Nevada Automotive Test Center" 124 "Hydac Electronic" 123 "Basler Electric" 122 "FG Wilson (Engineering) Limited" 121 "HED (Hydro Electronic Devices, Inc.)" 120 "RDS Technology Ltd" 119 "IntegriNautics  " 118 "Intron GmbH" 117 "HUSCO International" 116 "BEELINE Technologies" 115 "NACCO Materials Handling Group, Inc." 114 "EControls, Inc." 113 "Stress-Tek, Inc." 112 "MECALAC" 111 "Maschinenfabrik Bernard Krone GmbH" 110 "EPIQ Sensor-Nite" 109 "TeeJet Technologies Denmark (formerly LH Technologies ApS)" 108 "WTK-Elecktronik GmbH" 107 "Grimme Landmaschinen GmbH & Co. KG" 106 "BAE Systems Controls, Inc." 105 "Kiepe Elektrik GmbH & Co. KG" 104 "CLAAS KGaA mbH (formerly CLAAS Selbstfahrende Erntemaschinen GmbH)" 103 "CLAAS E-Systems KGaA mbH & Co. KG (formerly CLAAS Agrosystems GmbH & Co. KG)" 102 "AGCO (formerly AGCO GmbH & Co.)" 101 "Sensoria" 100 "VDO Technik AG" 99 "International Transmissions Ltd (ITL)" 98 "Mueller-Elektronik GmbH & Co" 97 "Ag Leader Technology, Inc." 96 "Mech@tronic IT GmbH" 95 "Pacific Insight Electronics Corp." 94 "CNH Industrial N.V. (formerly CNH Global N.V.)" 93 "Perkins Engines Company Ltd." 92 "Ag-Chem Equipment Co., Inc." 91 "BSG Bodensee Steuergeraete GmbH" 90 "Knorr-Bremse SfN GmbH" 89 "Kverneland Group, Electronics Division" 88 "Satloc Precision GPS" 87 "J.C. Bamford Excavators Ltd (JCB)" 86 "C. E. Niehoff & Company" 85 "Kohler Co" 84 "New Holland UK Limited" 83 "Bendix VORAD Technologies (formerly Eaton VORAD Technologies)" 82 "Bobcat/Ingersoll-Rand (formerly Melroe/Ingersoll-Rand)" 81 "Fire Research Corp." 80 "Twin Disc, Inc." 79 "Daimler Benz AG - Engine Division (PBM)" 78 "Frank W. Murphy Manufacturing, Inc" 77 "Deere Power Systems Group" 76 "unused (formerly Deere & Co, Construction Division)" 75 "Deere & Co, Agricultural Division" 74 "Eaton Axle-Brake Division" 73 "LeTourneau, Inc." 72 "Sisu Corporation" 71 "Vansco Electronics Ltd." 70 "Flex-coil Limited" 69 "Trimble Navigation" 316 "ITT Flow Control" 315 "Icom Incorporated" 314 "CSM GmbH" 313 "Ilmor Engineering, Inc." 312 "Lectronix, Inc." 311 "Patrick Power Products" 310 "TECNORD srl" 309 "Krauss-Maffei Wegmann GmbH & Co. KG" 308 "Cyntrx" 307 "MAS Technologies" 306 "Sleipner Motor AB" 305 "NovAtel Inc" 304 "EmpirBus AB" 303 "CTS Corporation" 302 "Nissin Kogyo Co., LTD" 301 "Parker Hannifin (UK) Ltd FDE group" 300 "Systron Donner Automotive" 299 "Rauch" 298 "Holley Performance" 297 "Zonar Systems Inc" 296 "micro dynamics GmbH" 295 "BEP Marine" 294 "Grayhill Inc." 293 "Spyder Controls Corp." 292 "IKUSI - Angel Iglesias S.A." 291 "Groeneveld Transport Efficiency BV" 290 "Kuebler GmbH" 289 "Watlow" 288 "Mitsubishi FUSO Truck & Bus Corp." 287 "NTech Industries, Inc" 286 "Coelmo srl" 285 "Sea Recovery Corp" 284 "Mobile Tech Chile" 283 "CWF Hamilton & Co Ltd" 282 "Medallion Instrumentation Systems" 281 "Precision Governors LLC" 280 "Leica Geosystems Pty Ltd" 279 "Geometris LP" 278 "Takata Electronics" 277 "LHP Telematics" 276 "Aqua-Hot Heating Systems" 275 "Navico Egersund AS" 274 "LTW Technology Co., LTD" 273 "Active Research Limited" 272 "Gross Mechanical Laboratories, Inc" 271 "Cole Hersee" 270 "Tennant" 269 "Saft America Inc.,  Space & Defense Division" 268 "Accurate Technologies" 267 "Red Lion Controls, Inc" 266 "International Thermal Research Ltd" 265 "MTS Sensor Technologie GmbH" 264 "Autolync" 213 "CNH Belgium N.V." 212 "Sure Power Industries, Inc" 211 "DNA Group" 210 "Iteris, Inc." 209 "Bell Equip. Co. SA (PTY) LTD" 208 "Drew Technologies, Inc" 207 "Otto Engineering" 206 "port GmbH" 205 "SmarTire Systems Inc" 204 "The Morey Corporation" 203 "MILtronik GmbH" 202 "Curtis Instruments, Inc" 201 "Disenos y Tecnologia S.A." 200 "MGM Brakes" 199 "Actia Corp" 198 "Mystic Valley Communications" 197 "Mechron Power Systems" 196 "LEMKEN GmbH & Co KG" 195 "General Engine Products" 194 "TriMark Corporation" 193 "Jeppesen Marine" 192 "Floscan" 191 "XRS Corporation (formerly XATA Corporation)" 190 "Hella KGaA Hueck & Co" 189 "QUALCOMM" 188 "EMP Corp" 187 "Air-Weigh" 186 "Altronic, Inc" 185 "Beede Electrical Instrument Company" 184 "EIA Electronics" 183 "KDS Controls, Inc" 182 "Vehicle Systems Engineering B.V." 181 "Coretronics, Inc." 180 "Smart Power Systems" 179 "TeeJet Technologies Springfield (formerly Midwest Technologies Illinois, LLC)" 178 "Continental Automotive GmbH (formerly Siemens VDO Automotive AG)" 177 "Diagnostic Systems Associates" 176 "Moritz Aerospace" 175 "Veris Technologies, Inc." 174 "AB Volvo Penta" 173 "Ryeso, Inc." 172 "Yanmar Co., Ltd. (formerly Yanmar Marine USA)" 171 "Wachendorff Elektronik GmbH & Co. KG" 170 "Computronics Corporation Ltd." 169 "Marlin Technologies Inc." 168 "Xantrex" 167 "JLG Industries Inc" 166 "John Deere Electronic Solutions (formerly Phoenix International)" 165 "CPAC Systems AB" 68 "Scania" 67 "John Deere Coffeyville Works (formerly Funk Manufacturing Company)" 66 "John Deere Construction Equipment Division" 65 "MAN Nutzfahrzeuge AG" 64 "Unused (formerly SpectraPrecision Laserplane, then SpectraPhysics)" 63 "ZF Industries Inc." 62 "Wabco" 61 "Volvo Truck Corp." 60 "Volvo Trucks North America Inc." 59 "VES Inc." 58 "SPX Corporation, OTC Div" 57 "Danfoss  (formerly Sauer Sundstrand Co, then Sauer-Danfoss Co)" 56 "SAIC" 55 "Ryder System Inc." 54 "Meritor Wabco" 53 "Continental Automotive Systems US, Inc. (formerly Rockwell Land Transportation)" 52 "Meritor Automotive, Inc. (formerly Rockwell Automotive)" 51 "Robert Bosch GmbH" 50 "Robert Bosch Corp" 49 "RE America Inc." 48 "Pollak Alphabet" 47 "Phillips Semiconductor" 46 "Noregon Systems, Inc  (formerly Parasoft Computing Solutions)" 45 "PACCAR" 44 "Nippondenso Co. Ltd." 43 "International Truck and Engine Corporation - Vehicle Electronics (formerly Navistar Intl Trans Corp.)" 42 "International Truck and Engine Corporation - Engine Electronics  (formerly Navistar Intl Trans Co., Engine Electronics)" 41 "Motorola Inc." 40 "Motorola AIEG Inc." 39 "Microfirm Inc." 38 "Micro Processor Systems Inc." 37 "Mack Trucks Inc." 36 "Lucas Ind." 35 "Kenworth Truck Co." 34 "Kelsey Hayes Co." 33 "John Deere" 32 "Jacobs Vehicle Systems" 31 "J Pollak Corp" 30 "Isuzu Motors Ltd" 29 "Hino Motors Ltd." 28 "Grote Ind. Inc." 27 "GMC" 26 "General Motors Corp, Service Technology Grp" 25 "Daimler Trucks North America LLC (formerly Freightliner LLC)" 24 "Ford Motor Co., Vehicle Controls" 23 "Ford Motor Co., Heavy Truck" 22 "Ford Motor Co., Electronic Concepts & Systems" 21 "Echlin Inc., Midland Brake Inc." 20 "Eaton Ltd" 19 "Eaton Corp. Trucking Info Services" 18 "Eaton Corp, Transmission Div." 17 "Eaton Corp, Corp Res & Dev" 16 "Eaton Corp" 15 "DICKEY-john Corporation" 14 "Detroit Diesel Corporation" 13 "Delco Electronics" 12 "Deere & Company, Precision Farming" 11 "Dearborn Group Inc." 10 "Cummins Inc (formerly Cummins Engine Co)" 9 "Chrysler Corp." 8 "Caterpillar Inc." 7 "Case Corp." 6 "Berifors Electronics AB" 5 "AMP Inc." 4 "Ametek-Dixson" 3 "Ametek, US Gauge Division" 2 "Allison Transmission, Inc." 1 "Bendix Commercial Vehicle Systems LLC (formerly Allied Signal Inc.)" 0 "Reserved" ;
VAL_ 2628452094 SA_ATTR_SupportsLongFilenames 0 "Does not support long file names" 1 "Supports long file names" ;
VAL_ 2628452094 SA_ATTR_VolumeSupportsHidden 0 "No support of hidden attribute" 1 "Supports hidden attribute" ;
VAL_ 2628452094 SA_ATTR_VolumeIsRemovable 0 "Is not removable" 1 "Is removable" ;
VAL_ 2628452094 SA_ATTR_VolumeIsCaseSensitive 0 "Is case-insensitive" 1 "Is case-sensitive" ;
VAL_ 2628452094 SA_ATTR_IsVolume 0 "Does not specify a volume " 1 "Specifies a volume" ;
VAL_ 2628452094 SA_ATTR_IsDirectory 0 "Does not specify a directory" 1 "Specifies a directory" ;
VAL_ 2628452094 RF_ReportHiddenFiles 0 "DoNotReportHiddenFiles" 1 "ReportHiddenFiles" 255 "NotAvailable" ;
VAL_ 2628452094 SF_PositionMode 0 "From the beginning of the file" 1 "From the current pointer pos" 2 "From the end of the file" ;
VAL_ 2628452094 OF_FlagExclusiveAccess 0 "Open file for shared read access" 1 "Open file with exclusive access" ;
VAL_ 2628452094 OF_FlagAppend 0 "Open file for random access" 1 "Open file for appending data" ;
VAL_ 2628452094 SA_ATTR_Hidden 0 "'Hidden' attribute is not set" 1 "'Hidden' attribute is set" ;
VAL_ 2628452094 OF_FlagCreateNew 0 "Open an existing file" 1 "Create new file if not existing" ;
VAL_ 2628452094 MF_MoveModeRecursive 0 "'recursive' mode is not set" 1 "'recursive' mode is set" ;
VAL_ 2628452094 DF_DeleteModeRecursive 0 "'recursive' mode is not set" 1 "'recursive' mode is set" ;
VAL_ 2628452094 MF_MoveModeForce 0 "'force' mode is not set" 1 "'force' mode is set" ;
VAL_ 2628452094 DF_DeleteModeForce 0 "'force' mode is not set" 1 "'force' mode is set" ;
VAL_ 2628452094 SA_ATTR_ReadOnly 0 "'Read-only' attribute is not set" 1 "'Read-only' attribute is set" ;
VAL_ 2628452094 OF_FlagReadWrite 0 "Open file for reading only" 1 "Open file for writing only" 2 "Open file for reading & writing" 3 "Open directory for reading" ;
VAL_ 2628452094 MF_MoveModeCopy 0 "'copy' mode is not set" 1 "'copy' mode is set" ;
VAL_ 2628452094 DF_DeleteMode 0 "'copy' mode is not set" 1 "'copy' mode is set" ;
VAL_ 2628452094 VS_RequestVolumeToPrepareFo_0001 1 "RequestVolumeToPrepareForRemoval" ;
VAL_ 2628452094 VS_ReportVolumeUsedByClient 0 "ReportVolumeNotInUseByClient" 1 "ReportVolumeInUseByClient" ;
VAL_ 2628452094 CM_VersionNumber 0 "DIS" 1 "FDIS" 2 "FirstPublishedEditionOfIS" 3 "SecondPublishedEditionOfIS" 255 "CompliantToVersion2AndPrior" ;
VAL_ 2628452094 FSClientCommand 0 "ConnectionMaintenance" 16 "GetCurrentDirectoryRequest" 32 "OpenFileRequest" 33 "SeekFileRequest" 34 "ReadFileRequest" 35 "WriteFileRequest" 36 "CloseFileRequest" 48 "MoveFileRequest" 49 "DeleteFileRequest" 50 "GetFileAttributesRequest" 51 "SetFileAttributesRequest" 17 "ChangeCurrentDirectoryRequest" 52 "GetFileDateTimeRequest" 64 "VolumeInitializationRequest" 1 "GetFileServerProperties" 2 "VolumeStatusRequest" ;
VAL_ 2628517630 OF_ATTR_VolumeSupportsHidden 0 "No support of hidden attribute" 1 "Supports hidden attribute" ;
VAL_ 2628517630 OF_ATTR_VolumeIsCaseSensitive 0 "Is case-insensitive" 1 "Is case-sensitive" ;
VAL_ 2628517630 OF_ATTR_VolumeIsRemovable 0 "Is removable" 1 "Is not removable" ;
VAL_ 2628517630 OF_ATTR_SupportsLongFilenames 0 "Does not support long filename" 1 "Supports long filenames" ;
VAL_ 2628517630 OF_ATTR_IsDirectory 0 "Does not specifiy a directory" 1 "Specifes a directory" ;
VAL_ 2628517630 OF_ATTR_IsVolume 0 "Does not specifiy a volume" 1 "Specifies a volume" ;
VAL_ 2628517630 OF_ATTR_Hidden 0 "'Hidden' attribute is not set" 1 "'Hidden' attribute is set" ;
VAL_ 2628517630 OF_ATTR_ReadOnly 0 "'Read-only' attribute is not set" 1 "'Read-only' attribute is set" ;
VAL_ 2628517630 GA_ATTR_VolumeIsCaseSensitive 0 "Is case-insensitive" 1 "Is case-sensitive" ;
VAL_ 2628517630 VI_ATTR_VolumeRemovable 0 "Is removable" 1 "Is not removable" ;
VAL_ 2628517630 GA_ATTR_VolumeIsRemovable 0 "Is removable" 1 "Is not removable" ;
VAL_ 2628517630 VI_ATTR_SupportsLongFilenames 0 "Does not support long filename" 1 "Supports long filenames" ;
VAL_ 2628517630 GA_ATTR_SupportsLongFilenames 0 "Does not support long filename" 1 "Supports long filenames" ;
VAL_ 2628517630 GA_ATTR_IsDirectory 0 "Does not specifiy a directory" 1 "Specifes a directory" ;
VAL_ 2628517630 VI_ATTR_IsDirectory 0 "Does not specify a directory" 1 "Secifies a directory" ;
VAL_ 2628517630 VI_ATTR_IsVolume 0 "Does not specifiy a volume" 1 "Specifies a volume" ;
VAL_ 2628517630 GA_ATTR_IsVolume 0 "Does not specifiy a volume" 1 "Specifies a volume" ;
VAL_ 2628517630 VI_ATTR_VolumeSupportsHidden 0 "No support of hidden attribute" 1 "Supports hidden attribute" ;
VAL_ 2628517630 GA_ATTR_VolumeSupportsHidden 0 "No support of hidden attribute" 1 "Supports hidden attribute" ;
VAL_ 2628517630 VI_ATTR_Hidden 0 "'Hidden' attribute is not set" 1 "'Hidden' attribute is set" ;
VAL_ 2628517630 GA_ATTR_Hidden 0 "'Hidden' attribute is not set" 1 "'Hidden' attribute is set" ;
VAL_ 2628517630 VI_ATTR_ReadOnly 0 "'Read-only' attribute is not set" 1 "'Read-only' attribute is set" ;
VAL_ 2628517630 GA_ATTR_ReadOnly 0 "'Read-only' attribute is not set" 1 "'Read-only' attribute is set" ;
VAL_ 2628517630 GSP_SupportMultipleVolumes 0 "Beschreibung für den Wert '0'" ;
VAL_ 2628517630 FDT_ErrorCode 0 "Success" 1 "Access Denied" 3 "Too many files open" 4 "File, path or volume not found" 6 "Invalid given source name" 10 "Media is not present" 44 "Any other error" 43 "Out ot memory" 11 "Failure during a read operation" 13 " Volume possibly not initialized" ;
VAL_ 2628517630 RF_ErrorCode 45 "File pointer at end of file" 44 "Any other error" 42 "Invalid request length" 5 "Invalid handle" 0 "Success" 11 "Failure during read operation" 43 "Out of memory" 1 "Access denied" ;
VAL_ 2628517630 SF_ErrorCode 0 "Success" 5 "Invalid handle" 42 "Invalid request length" 44 "Any other error" 45 "File pointer at end of file" 11 "Failure during read operation" 43 "Out of memory" ;
VAL_ 2628517630 OF_ErrorCode 0 "Success" 1 "Access Denied" 2 "Invalid Access" 3 "Too many files open" 4 "File, path or volume not found" 6 "Invalid given source name" 8 "Volume out of free space" 10 "Media is not present" 44 "Any other error" 43 "Out of memory" 13 "Volume possibly not initialized" ;
VAL_ 2628517630 WF_ErrorCode 0 "Success" 1 "Access Denied" 5 "Invalid handle" 8 "Volume out of free space" 9 "Failure during a write operation" 42 "Invalid request length" 44 "Any other error" 43 "Out of memory" ;
VAL_ 2628517630 CF_ErrorCode 0 "Success" 1 "Access Denied" 5 "Invalid handle" 8 "Volume out of free space" 9 "Failure during a write operation" 44 "Any other error" 43 "Out ot memory" ;
VAL_ 2628517630 MF_ErrorCode 0 "Success" 1 "Access Denied" 3 "Too many files open" 6 "Invalid given source name" 7 "Invalid given destination name" 8 "Volume out of free space" 9 "Verify failure during a write op" 10 "Media is not present" 44 "Any other error" 43 "Out of memory" 4 "File, path or volume not found" 13 "Volume possibly not initialized" ;
VAL_ 2628517630 GA_ErrorCode 0 "Success" 1 "Access Denied" 3 "Too many files open" 4 "File, path or volume not found" 6 "Invalid given source name" 10 "Media is not present" 44 "Any other error" 43 "Out of memory" 11 "Failure during read operation" 13 "Volume possibly not initialized" ;
VAL_ 2628517630 SA_ErrorCode 0 "Success" 1 "Access Denied" 3 "Too many files open" 4 "File, path or volume not found" 6 "Invalid given source name" 8 "Volume out of free space" 9 "Failure during write operation" 10 "Media is not present" 44 "Any other error" 43 "Out of memory" 11 "Failure during read operation" 13 "Volume possibly not initialized" ;
VAL_ 2628517630 GCD_ErrorCode 0 "Success" 10 "Media is not present" 44 "Any other error" 43 "Out of Memory" 13 "Volume possibly not initialized" ;
VAL_ 2628517630 CCD_ErrorCode 0 "Success" 10 "Media is not present" 44 "Any other error" 43 "Out of memory" 13 "Volume possibly not initialized" 1 "Access denied" 2 "Invalid Access" 4 "File, path or volume not found" 7 "Invalid destination name given" ;
VAL_ 2628517630 DF_ErrorCode 0 "Success" 1 "Access Denied" 4 "File, path or volume not found" 6 "Invalid given source name" 10 "Media is not present" 44 "Any other error" 43 "Out of memory" 9 "Failure during write operation" 11 "Failure during read operation" 13 "Volume possibly not initialized" ;
VAL_ 2628517630 VI_ErrorCode 0 "Success" 1 "Access Denied" 4 "File, path or volume not found" 6 "Invalid given source name" 8 "Volume out of free space" 9 "Failure during write operation" 42 "Invalid request length" 44 "Any other error" 43 "Out of memory" 10 "Media is not present" 11 "Failure during read operation" 13 "Volume possibly not initialized" ;
VAL_ 2628517630 GSP_VersionNumber 0 "DIS" 1 "FDIS" 2 "FirstPublishedEditionOfIS" 3 "SecondPublishedEditionOfIS" 255 "CompliantToVersion2AndPrior" ;
VAL_ 2628517630 VS_VolumeStatus 0 "Present" 1 "InUse" 2 "PreparingForRemoval" 3 "Removed" ;
VAL_ 2628517630 FSServerCommand 0 "FileServerStatus" 16 "GetCurrentDirectoryResponse" 32 "OpenFileResponse" 33 "SeekFileResponse" 34 "ReadFileResponse" 35 "WriteFileResponse" 36 "CloseFileResponse" 48 "MoveFileResponse" 49 "DeleteFileResponse" 50 "GetFileAttributesResponse" 51 "SetFileAttributeResponse" 17 "ChangeCurrentDirectoryResponse" 52 "GetFileDateTimeResponse" 64 "VolumeInitializationResponse" 1 "GetFileServerPropertiesResponse" 2 "VolumeStatusResponse" ;
VAL_ 2364540158 EngStarterMode 15 "not available" 14 "error" 12 "starter inhibited  reason unknown" 9 "starter inhibited due to intake air shutoff valve being active" 8 "starter inhibited due to starter overtemp" 7 "starter inhibited due to active immobilizer" 6 "starter inhibited due to driveline engaged or other transmission inhibit" 5 "starter inhibited due to engine not ready for start preheating" 4 "starter inhibited due to engine already running" 3 "start finished starter not active after having been actively engaged after 50ms mode goes to 0000" 2 "starter active gear engaged" 1 "starter active gear not engaged" 0 "start not requested" 10 "starter inhibited due to active SCR inducement" 11 "Reserved" 13 "error legacy implementation only use 1110" ;
VAL_ 2364540158 ActlEngPrcntTorqueHighResolution 0 "0000" 1 "0125" 7 "0875" 8 "1111  not available" ;
VAL_ 2563309310 PGNumber 255 "NotAvailable" ;
VAL_ 2563309310 ControlByte 255 "EAbort" 20 "ERTS" 21 "ECTS" 22 "EDPO" 23 "EEoMACK" 24 "EAbort" ;
VAL_ 2563309310 ConnectionAbortReason 15 "ECTS requested packets exceeds message size" 14 "Unexpected ECTS PGN (PGN in ECTS is bad)" 13 "Deprecated use 254 instead" 12 "Bad EDPO offset" 11 "EDPO number of packets is greater than CTS" 10 "Unexpected EDPO PGN (PGN in EDPO is bad)" 9 "Unexpected EDPO packet" 8 "Duplicate sequence number" 1 "Already in one or more connection-managed sessions" 2 "System resources were needed for another task" 3 "Timeout occurred" 4 "CTS messages received when data transfer is in progress" 5 "Maximum retransmit request limit reached" 6 "Unexpected data transfer packet" 7 "Bad sequence number" ;
VAL_ 2365475326 GroundBasedMachineDirection 3 "NotAvailable" 2 "ErrorIndication" 1 "Forward" 0 "Reverse" ;
